VERSION ""

NS_ :

BS_:

BU_: BDCF THU FP IP RRS PLG BDCR FIS EPS ARHUD ETC EMS EPBI LAS WLCM ESCL HU APA ACC LCDAL LCDAR BMT AMP SRS TCU ATB AWD ESL ACM ECM PCU BMS IBCU OTA

BO_ 651 BCM_28B: 8 BDCF
 SG_ BCM_LowBeamStatus : 7|2@0+ (1,0) [0|3] "" THU,HU,IP
 SG_ BCM_HighBeamStatus : 5|2@0+ (1,0) [0|3] "" THU,HU,IP
 SG_ BCM_TurnLightSwitchSts : 3|2@0+ (1,0) [0|3] "" THU,HU,IP
 SG_ PEPS_EngineStallReq : 1|1@0+ (1,0) [0|1] "" EMS
 SG_ BCM_ReversePosition : 0|1@0+ (1,0) [0|1] "" THU,HU,IP,RRS
 SG_ BCM_HU_LampHeightLevFeedback : 11|4@0+ (1,0) [0|15] "" THU,HU
 SG_ BCM_DriverDoorStatus : 23|1@0+ (1,0) [0|1] "" THU,HU,IP,FIS,ESCL,BDCR
 SG_ BCM_TurnIndicatorLeft : 22|2@0+ (1,0) [0|3] "" THU,HU,IP,FIS
 SG_ BCM_TurnIndicatorRight : 20|2@0+ (1,0) [0|3] "" THU,HU,IP,FIS
 SG_ BCM_HoodStatus : 18|1@0+ (1,0) [0|1] "" THU,HU,IP
 SG_ PEPS_StartControlsignal : 17|2@0+ (1,0) [0|3] "" THU,IP
 SG_ LCM_LASSwitch : 25|2@0+ (1,0) [0|3] "" Vector__XXX
 SG_ PEPS_RemoteStartReq : 39|2@0+ (1,0) [0|3] "" THU,IP
 SG_ BCM_emergencylightstatus : 37|2@0+ (1,0) [0|3] "" THU,HU,IP
 SG_ BCM_PowerStatusFeedback : 35|2@0+ (1,0) [0|3] "" THU,HU,IP,FIS,PLG,BDCR
 SG_ BCM_RearDefrosterstatus : 33|2@0+ (1,0) [0|3] "" FP,THU
 SG_ BCM_RefuelReq : 55|1@0+ (1,0) [0|1] "" Vector__XXX
 SG_ PEPS_ShiftForbidReq : 54|1@0+ (1,0) [0|1] "" THU
 SG_ BCM_KeyAlarmStatus : 53|2@0+ (1,0) [0|3] "" THU,HU,IP,PLG
 SG_ BCM_RollingCounter_28B : 51|4@0+ (1,0) [0|15] "" Vector__XXX
 SG_ BCM_CRCCheck_28B : 63|8@0+ (1,0) [0|255] "" Vector__XXX

BO_ 610 BCM_262: 8 BDCF
 SG_ PEPS_StartIndicatorSignal : 7|1@0+ (1,0) [0|1] "" THU,IP
 SG_ PEPS_RemoteAPADoneKeyOffReq : 6|2@0+ (1,0) [0|3] "" Vector__XXX
 SG_ PEPS_APA_Engine0ffFeedback : 4|2@0+ (1,0) [0|3] "" Vector__XXX
 SG_ PEPS_APA_LockFeedback : 2|2@0+ (1,0) [0|3] "" Vector__XXX
 SG_ PEPS_APARemoteParkingSwitch : 0|1@0+ (1,0) [0|1] "" Vector__XXX
 SG_ PEPS_UnallowStart_ESCL_Error : 15|1@0+ (1,0) [0|1] "" THU,IP
 SG_ PEPS_APA_CloseWinFeedback : 11|2@0+ (1,0) [0|3] "" Vector__XXX
 SG_ PEPS_RemoteControlACReq : 9|2@0+ (1,0) [0|3] "" Vector__XXX
 SG_ PEPS_PowerDistributionStatus : 23|2@0+ (1,0) [0|3] "" THU,IP,ESCL
 SG_ PEPS_UnallowStart_ESCL_LOCK : 21|1@0+ (1,0) [0|1] "" THU,IP
 SG_ PEPS_EngineRuningWarning : 20|1@0+ (1,0) [0|1] "" Vector__XXX
 SG_ PEPS_UnallowStartSignal_Not_PN : 19|1@0+ (1,0) [0|1] "" THU,IP
 SG_ PEPS_IMMOFailedAlarmsignal : 18|1@0+ (1,0) [0|1] "" THU,IP
 SG_ PEPS_StartupButtonSignal : 17|2@0+ (1,0) [0|3] "" THU
 SG_ PEPS_RemoteStartFeedback : 31|5@0+ (1,0) [0|31] "" THU,IP
 SG_ PEPS_APA_PowerMirrorFoldFeedback : 26|2@0+ (1,0) [0|3] "" Vector__XXX
 SG_ PEPS_EngineStartupInhibitSts : 24|1@0+ (1,0) [0|1] "" Vector__XXX
 SG_ PEPS_PowerOff_NotPN_AlarmSignal : 38|1@0+ (1,0) [0|1] "" THU,IP
 SG_ PEPS_FRCameraStart : 37|2@0+ (1,0) [0|3] "" THU,IP,FIS
 SG_ PEPS_TBOX_RemoteIGNOnOffFeedback : 35|2@0+ (1,0) [0|3] "" THU,IP
 SG_ PEPS_PowerDistributionFaultBit : 47|1@0+ (1,0) [0|1] "" THU,IP
 SG_ PEPS_EngineStartupInhibitFB : 46|1@0+ (1,0) [0|1] "" THU
 SG_ PEPS_IMMOFeedback : 45|2@0+ (1,0) [0|3] "" Vector__XXX
 SG_ PEPS_PEPSFailStatus : 55|1@0+ (1,0) [0|1] "" THU,IP
 SG_ PEPS_KeyStandbyPositionIndicator : 54|1@0+ (1,0) [0|1] "" Vector__XXX
 SG_ PEPS_APARemoteParkingOff : 53|1@0+ (1,0) [0|1] "" Vector__XXX
 SG_ PEPS_RollingCounter_262 : 51|4@0+ (1,0) [0|15] "" Vector__XXX
 SG_ BCM_PEPS_BlueTooth : 60|2@0+ (1,0) [0|3] "" Vector__XXX
 SG_ PEPS_CRCCheck_262 : 63|8@0+ (1,0) [0|255] "" Vector__XXX

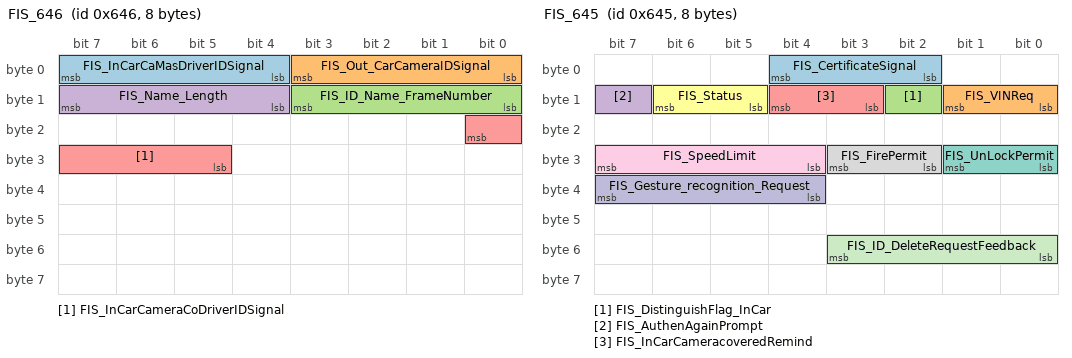
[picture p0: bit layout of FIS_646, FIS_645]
BO_ 1606 FIS_646: 8 FIS
 SG_ FIS_InCarCaMasDriverIDSignal : 7|4@0+ (1,0) [0|15] "" BDCF,THU
 SG_ FIS_Out_CarCameraIDSignal : 3|4@0+ (1,0) [0|15] "" BDCF,THU
 SG_ FIS_ID_Name_FrameNumber : 11|4@0+ (1,0) [0|15] "" BDCF,THU,IP
 SG_ FIS_Name_Length : 15|4@0+ (1,0) [0|15] "" BDCF,THU,IP
 SG_ FIS_InCarCameraCoDriverIDSignal : 16|4@0+ (1,0) [0|15] "" BDCF,THU

BO_ 1605 FIS_645: 8 FIS
 SG_ FIS_CertificateSignal : 4|3@0+ (1,0) [0|7] "" BDCF,THU,IP
 SG_ FIS_VINReq : 9|2@0+ (1,0) [0|3] "" BDCF,THU
 SG_ FIS_DistinguishFlag_InCar : 10|1@0+ (1,0) [0|1] "" BDCF,THU,IP
 SG_ FIS_AuthenAgainPrompt : 15|1@0+ (1,0) [0|1] "" BDCF,THU,IP
 SG_ FIS_InCarCameracoveredRemind : 12|2@0+ (1,0) [0|3] "" BDCF,THU,IP
 SG_ FIS_Status : 14|2@0+ (1,0) [0|3] "" BDCF,THU,IP
 SG_ FIS_UnLockPermit : 25|2@0+ (1,0) [0|3] "" BDCF,THU
 SG_ FIS_FirePermit : 27|2@0+ (1,0) [0|3] "" BDCF,THU
 SG_ FIS_SpeedLimit : 31|4@0+ (1,0) [0|15] "" BDCF,THU,IP
 SG_ FIS_Gesture_recognition_Request : 39|4@0+ (1,0) [0|7] "" BDCF,THU,IP
 SG_ FIS_ID_DeleteRequestFeedback : 51|4@0+ (1,0) [0|15] "" BDCF,THU

BO_ 935 FIS_3A7: 8 FIS
 SG_ FIS_PassengerDrowsinessStatus : 21|3@0+ (1,0) [0|3] "" BDCF,THU

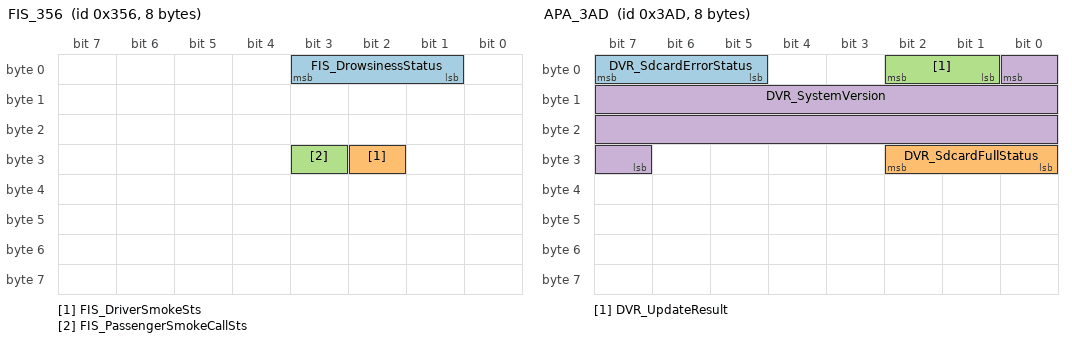
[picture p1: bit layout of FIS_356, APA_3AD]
BO_ 854 FIS_356: 8 FIS
 SG_ FIS_DrowsinessStatus : 3|3@0+ (1,0) [0|7] "" BDCF,THU
 SG_ FIS_DriverSmokeSts : 26|1@0+ (1,0) [0|1] "" BDCF,THU
 SG_ FIS_PassengerSmokeCallSts : 27|1@0+ (1,0) [0|1] "" BDCF,THU

BO_ 1554 APA_612: 8 APA
 SG_ DVR_DVREnableSetStatus : 7|2@0+ (1,0) [0|3] "" BDCF,THU
 SG_ DVR_DVRTapeSetStatus : 5|2@0+ (1,0) [0|3] "" THU
 SG_ DVR_RecordingCycleSetStatus : 1|2@0+ (1,0) [0|3] "" THU
 SG_ DVR_Error : 15|1@0+ (1,0) [0|1] "" THU
 SG_ DVR_DisplayVison : 12|3@0+ (1,0) [0|7] "" THU
 SG_ DVR_PhotographResult : 9|2@0+ (1,0) [0|3] "" THU
 SG_ DVR_DVRErrorRecordStatus : 31|2@0+ (1,0) [0|3] "" THU
 SG_ DVR_EmergencyRecordStatus : 29|2@0+ (1,0) [0|3] "" THU
 SG_ DVR_FormatStatus : 27|3@0+ (1,0) [0|7] "" THU
 SG_ AVM_DVREditFeedback : 24|1@0+ (1,0) [0|1] "" THU
 SG_ DVR_ReplayMode : 39|3@0+ (1,0) [0|7] "" THU
 SG_ AVM_DVRModeFeedback : 18|3@0+ (1,0) [0|7] ""  THU
 SG_ DVR_DistortCorrection : 34|1@0+ (1,1) [0|1] "" THU
 SG_ DVR_StoragePercent : 33|7@0+ (1,0) [0|100] "%" THU
 SG_ DVR_NormalToEmergency : 42|3@0+ (1,1) [0|7] "" THU
 SG_ DVR_StorageStatus : 55|2@0+ (1,0) [0|3] "" THU
 SG_ AVM_DVRReplayCommandStatus : 51|2@0+ (1,0) [0|3] "" THU
 SG_ AVM_DVRReplaySpeedStatus : 49|2@0+ (1,0) [0|3] "" THU
 SG_ DVR_PrintScreenFeedback : 53|2@0+ (1,0) [0|3] "" THU
 SG_ AVM_DVRDeleteStatus : 63|2@0+ (1,0) [0|3] "" THU
 SG_ AVM_CurrentVideo_counts : 61|4@0+ (1,0) [0|15] "" THU
 SG_ AVM_FormatFAT32Req : 57|1@0+ (1,0) [0|1] "" THU

BO_ 941 APA_3AD: 8 APA
 SG_ DVR_SdcardErrorStatus : 7|3@0+ (1,0) [0|7] "" BDCF,THU
 SG_ DVR_SdcardFullStatus : 26|3@0+ (1,0) [0|7] ""  THU
 SG_ DVR_UpdateResult : 2|2@0+ (1,0) [0|3] "" THU
 SG_ DVR_SystemVersion : 0|18@0+ (1,0) [0|0] "" THU

BO_ 992 APA_3E0: 8 APA
 SG_ AVM_DisplayForm : 4|5@0+ (1,0) [0|31] "" BDCF,THU
 SG_ AVM_DisplayReq : 7|2@0+ (1,0) [0|3] "" THU
 SG_ AVM_OverspeedWarning : 5|1@0+ (1,0) [0|1] "" THU
 SG_ AVM_LineOnOff : 15|2@0+ (1,0) [0|1] "" THU
 SG_ AVM_VisionAngle : 13|2@0+ (1,0) [0|3] "" THU
 SG_ AVM_RecordFeedback : 11|2@0+ (1,0) [0|3] "" THU
SG_ AVM_TopLookDownFeedBack : 52|2@0+ (1,0) [0|3] ""  THU
 SG_ AVM_3DFeedback : 23|2@0+ (1,0) [0|3] "" THU
 SG_ AVM_MODFeedback : 21|2@0+ (1,0) [0|3] "" THU
 SG_ AVM_MODAlert_Sound : 19|2@0+ (1,0) [0|3] "" THU,IP
 SG_ AVM_CalibrationStatus : 17|3@0+ (1,0) [0|7] "" THU
 SG_ AVM_CalibrationComfirm : 30|2@0+ (1,0) [0|3] "" THU
 SG_ AVM_RadarAVMFeedback : 28|2@0+ (1,0) [0|3] "" THU
 SG_ AVM_TurnlightFeedback : 26|2@0+ (1,0) [0|3] "" THU
 SG_ AVM_DVRVideoTimeLength : 24|9@0+ (1,0) [0|3] "second" THU
 SG_ AVM_DVRVideoPlayTime : 47|9@0+ (1,0) [0|3] "second" THU
 SG_ AVM_TransparentCarFeedback : 54|2@0+ (1,0) [0|3] "" THU
 SG_ AVM_RVDisplayReq : 56|1@0+ (1,0) [0|1] "" THU
 SG_ AVM_AVMOffSpeedStatus : 59|3@0+ (1,0) [0|7] "" THU
 SG_ DVR_UploadFeedback : 61|2@0+ (1,0) [0|3] "" THU
 SG_ AVM_StartOpenAvmSts : 63|2@0+ (1,0) [0|3] "" THU
 SG_ AVM_DirtyWarning : 48|1@0+ (1,0) [0|1] ""  THU

BO_ 1365 TBOX_555: 8 THU
SG_ TBOX_TUIDFrameNumber : 7|2@0+ (1,0) [0|3] "" BDCF
SG_ TBOX_TUIDNumber : 15|48@0+ (1,0) [0|16777215] "" BDCF
SG_ TBOX_CRCCheck_555 : 63|8@0+ (1,0) [0|255] "" BDCF

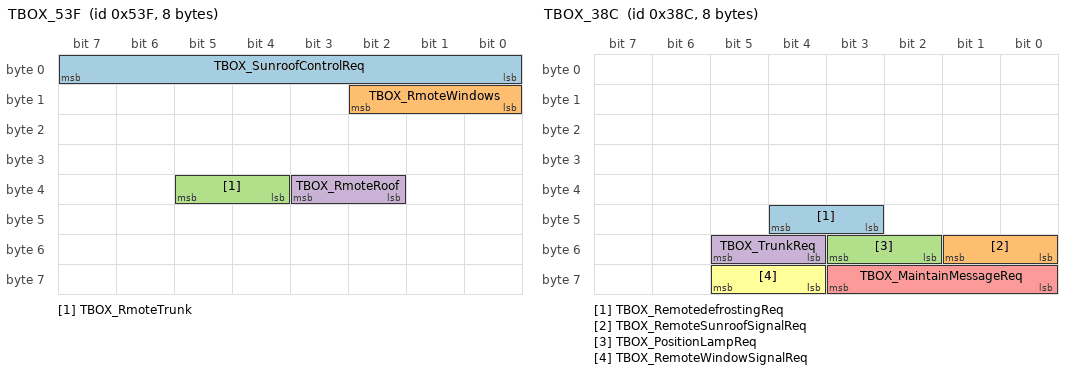
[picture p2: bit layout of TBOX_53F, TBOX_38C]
BO_ 1343 TBOX_53F: 8 THU
SG_ TBOX_SunroofControlReq : 7|8@0+ (1,0) [0|255] "" BDCF
SG_ TBOX_RmoteWindows : 10|3@0+ (1,0) [0|7] "" BDCF
SG_ TBOX_RmoteTrunk : 37|2@0+ (1,0) [0|3] "" BDCF,PLG
SG_ TBOX_RmoteRoof : 35|2@0+ (1,0) [0|3] "" BDCF

BO_ 719 TBOX_2CF: 8 THU
SG_ TBOX_BLEDataFlow : 7|64@0+ (1,0) [0|0] "" BDCF

BO_ 909 TBOX_38D: 8 THU
SG_ TBOX_VehicleVedioDetectReq : 1|2@0+ (1,0) [0|3] "" BDCF
SG_ TBOX_LockCommand : 3|2@0+ (1,0) [0|3] "" BDCF
SG_ TBOX_EngineStartupInhibit : 5|2@0+ (1,0) [0|3] "" BDCF
SG_ TBOX_RemoteEngineStartupReq : 7|2@0+ (1,0) [0|3] "" BDCF
SG_ TBOX_CallStatus : 10|3@0+ (1,0) [0|7] "" BDCF
SG_ TBOX_ChangePartStatus : 12|1@0+ (1,0) [0|1] "" BDCF
SG_ TBOX_AudioRequest : 14|2@0+ (1,0) [0|3] "" BDCF
SG_ TBOX_CarRemind : 15|1@0+ (1,0) [0|1] "" BDCF
SG_ TBOX_ACTempValueReq : 20|5@0+ (1,0) [0|31] "degreeC" BDCF
SG_ TBOX_BCallStatus : 23|3@0+ (1,0) [0|7] "" BDCF
SG_ TBOX_VINReq : 25|2@0+ (1,0) [0|3] "" BDCF
SG_ TBOX_VINMatchStatus : 27|2@0+ (1,0) [0|3] "" BDCF
SG_ TBOX_RemoteStartRunTime : 30|3@0+ (1,0) [0|7] "" BDCF
SG_ TBOX_VehicleStatusDemandReq : 31|1@0+ (1,0) [0|1] "" BDCF
SG_ TBOX_RemoteACStartupReq : 33|2@0+ (1,0) [0|3] "" BDCF
SG_ TBOX_ACFanAdjustValueReq : 37|4@0+ (1,0) [0|15] "" BDCF
SG_ TBOX_SearchCarReq : 39|2@0+ (1,0) [0|3] "" BDCF
SG_ TBOX_RemotePassangerSeatHotReq : 42|3@0+ (1,0) [0|7] "" BDCF
SG_ TBOX_RemoteDriverSeatHotReq : 45|3@0+ (1,0) [0|7] "" BDCF
SG_ TBOX_RemoteAirQualityInquire : 49|2@0+ (1,0) [0|3] "" BDCF
SG_ TBOX_CirculationModeReq : 51|2@0+ (1,0) [0|3] "" BDCF
SG_ TBOX_RemoteAirCleanReq : 53|2@0+ (1,0) [0|3] "" BDCF
SG_ TBOX_RemoteDetectReq : 55|2@0+ (1,0) [0|3] "" BDCF
SG_ TBOX_RemoteInstallReq : 57|2@0+ (1,0) [0|3] "" BDCF
SG_ TBOX_RemotePaVentilatieReq : 60|3@0+ (1,0) [0|7] "" BDCF
SG_ TBOX_RemoteDrVentilatieReq : 63|3@0+ (1,0) [0|7] "" BDCF

BO_ 908 TBOX_38C: 8 THU
 SG_ TBOX_RemotedefrostingReq : 44|2@0+ (1,0) [0|3] "" BDCF
 SG_ TBOX_RemoteSunroofSignalReq : 49|2@0+ (1,0) [0|3] "" BDCF
 SG_ TBOX_PositionLampReq : 51|2@0+ (1,0) [0|3] "" BDCF
 SG_ TBOX_TrunkReq : 53|2@0+ (1,0) [0|3] "" BDCF
 SG_ TBOX_MaintainMessageReq : 59|4@0+ (1,0) [0|15] "" BDCF
 SG_ TBOX_RemoteWindowSignalReq : 61|2@0+ (1,0) [0|3] "" BDCF

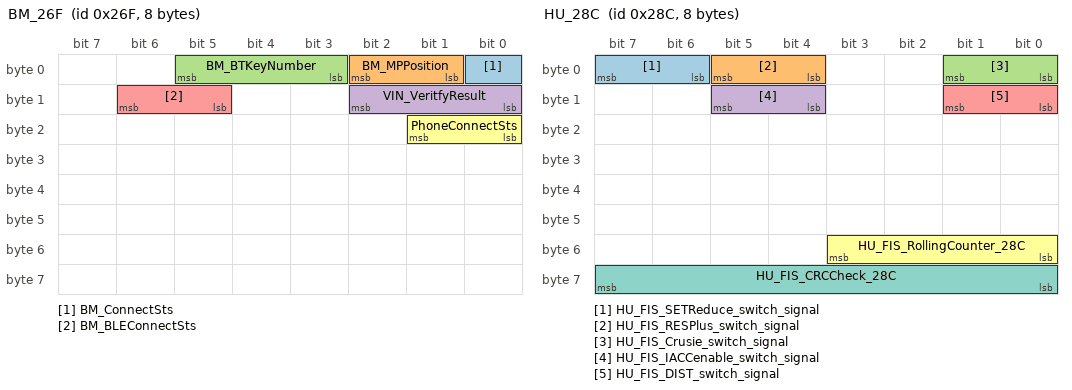
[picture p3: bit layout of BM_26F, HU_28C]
BO_ 623 BM_26F: 8 THU
SG_ BM_ConnectSts : 0|1@0+ (1,0) [0|1] "" BDCF
SG_ BM_MPPosition : 2|2@0+ (1,0) [0|3] "" BDCF
SG_ BM_BTKeyNumber : 5|3@0+ (1,0) [0|7] "" BDCF
SG_ VIN_VeritfyResult : 10|3@0+ (1,0) [0|7] "" BDCF
SG_ BM_BLEConnectSts : 14|2@0+ (1,0) [0|3] "" BDCF
 SG_ PhoneConnectSts : 17|2@0+ (1,0) [0|3] ""  BDCF

BO_ 622 BM_26E: 8 THU
SG_ BM_UnlockSignal : 0|1@0+ (1,0) [0|1] "" BDCF
SG_ BM_LockSignal : 1|1@0+ (1,0) [0|1] "" BDCF
SG_ BM_SunroofOpen : 2|1@0+ (1,0) [0|1] "" BDCF
SG_ BM_SunroofClose : 3|1@0+ (1,0) [0|1] "" BDCF
SG_ BM_LuggagelockSignal : 4|1@0+ (1,0) [0|1] "" BDCF
SG_ BM_LuggageUnlockSignal : 5|1@0+ (1,0) [0|1] "" BDCF
SG_ BM_SearchCarSignal : 9|2@0+ (1,0) [0|3] "" BDCF
SG_ BM_APAPOCModeSelect : 33|2@0+ (1,0) [0|3] "" BDCF
SG_ BM_All_WindowOpen : 34|1@0+ (1,0) [0|1] "" BDCF
SG_ BM_All_WindowClose : 35|1@0+ (1,0) [0|1] "" BDCF
SG_ BM_APAManeuverSuspend : 11|1@0+ (1,0) [0|1] "" BDCF
SG_ BM_APAManeuverCancel : 12|1@0+ (1,0) [0|1] "" BDCF
SG_ BM__StartControlsignal : 14|2@0+ (1,0) [0|3] "" BDCF
SG_ BM_APAManeuverStart : 15|1@0+ (1,0) [0|1] "" BDCF
SG_ BM_AllWindowCommand : 23|8@0+ (0.5,0) [0|100] "%" BDCF
SG_ BM_APAFunctionmoduleEnable : 25|2@0+ (1,0) [0|3] "" BDCF
SG_ BM_RPASwitch : 27|2@0+ (1,0) [0|3] "" BDCF
SG_ BM_OneTouchResponseSwitch : 29|2@0+ (1,0) [0|3] "" BDCF
SG_ BM_OneTouchDirectionSelect : 31|2@0+ (1,0) [0|3] "" BDCF

BO_ 652 HU_28C: 8 THU
 SG_ HU_FIS_SETReduce_switch_signal : 7|2@0+ (1,0) [0|3] "" BDCF,IP
 SG_ HU_FIS_RESPlus_switch_signal : 5|2@0+ (1,0) [0|3] "" BDCF,IP
 SG_ HU_FIS_Crusie_switch_signal : 1|2@0+ (1,0) [0|3] "" BDCF,IP
 SG_ HU_FIS_IACCenable_switch_signal : 13|2@0+ (1,0) [0|3] "" BDCF,IP
 SG_ HU_FIS_DIST_switch_signal : 9|2@0+ (1,0) [0|3] "" BDCF
 SG_ HU_FIS_RollingCounter_28C : 51|4@0+ (1,0) [0|15] ""  BDCF
 SG_ HU_FIS_CRCCheck_28C : 63|8@0+ (1,0) [0|255] ""  BDCF

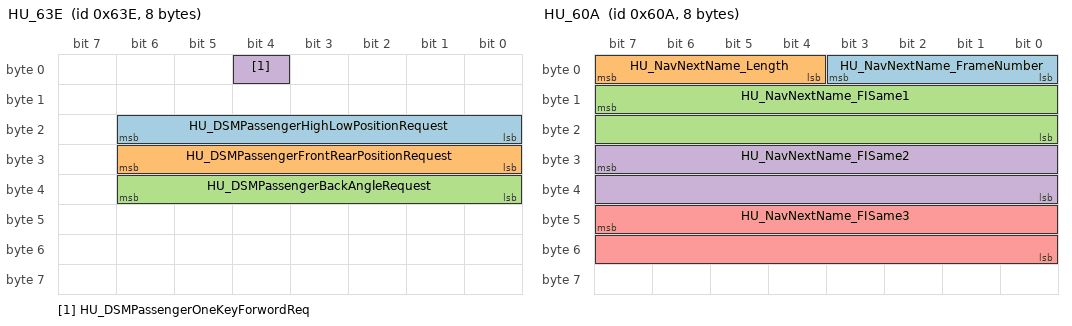
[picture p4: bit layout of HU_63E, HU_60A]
BO_ 1598 HU_63E: 8 THU
 SG_ HU_DSMPassengerHighLowPositionRequest : 22|7@0+ (1,0) [0|100] "%" BDCF
 SG_ HU_DSMPassengerFrontRearPositionRequest : 30|7@0+ (1,0) [0|100] "%" BDCF
 SG_ HU_DSMPassengerBackAngleRequest : 38|7@0+ (1,0) [0|126] "°" BDCF
 SG_ HU_DSMPassengerOneKeyForwordReq : 4|1@0+ (1,0) [0|1] "" BDCF

BO_ 1550 HU_60E: 8 THU
 SG_ HU_DSM_PositionSaved_Feedback : 1|2@0+ (1,0) [0|3] "" BDCF,FIS
 SG_ HU_MirrorTurnSet : 3|2@0+ (1,0) [0|3] "" BDCF
 SG_ HU_FRFuntionSet : 5|2@0+ (1,0) [0|3] "" BDCF,FIS
 SG_ HU_DSMComitySet : 7|2@0+ (1,0) [0|3] "" BDCF,FIS
 SG_ HU_DrDSMPositionSavedRequest : 9|2@0+ (1,0) [0|3] "" BDCF
 SG_ HU_PaDSMPositionSavedRequest : 11|2@0+ (1,0) [0|3] "" BDCF
 SG_ HU_DrDSMPositionRequest : 13|2@0+ (1,0) [0|3] "" BDCF,FIS
 SG_ HU_PaDSMPositionRequest : 15|2@0+ (1,0) [0|3] "" BDCF,FIS
 SG_ HU_DSMDriverHighLowPositionRequest : 22|7@0+ (1,0) [0|100] "%" BDCF
 SG_ HU_Current_position : 23|1@0+ (1,0) [0|1] "" BDCF
 SG_ HU_DSMDriverFrontRearPositionRequest : 30|7@0+ (1,0) [0|100] "%" BDCF
 SG_ HU_DSMDriverBackAngleRequest : 38|7@0+ (1,0) [0|126] "°" BDCF
 SG_ HU_DSMLeftMirrorXPositionRequest : 43|4@0+ (5,0) [0|75] "°" BDCF
 SG_ HU_DSMLeftMirrorYPositionRequest : 47|4@0+ (5,0) [0|75] "°" BDCF
 SG_ HU_DSMRightMirrorXPositionRequest : 51|4@0+ (5,0) [0|75] "°" BDCF
 SG_ HU_DSMRighttMirrorYPositionRequest : 55|4@0+ (5,0) [0|75] "°" BDCF
 SG_ HU_DSMComity_SwitchSet : 57|2@0+ (1,0) [0|3] "" BDCF
 SG_ HU_MirrorPositionSaved_Reques : 59|2@0+ (1,0) [0|3] "" BDCF

BO_ 1546 HU_60A: 8 THU
 SG_ HU_NavNextName_FrameNumber : 3|4@0+ (1,0) [0|15] "" BDCF
 SG_ HU_NavNextName_Length : 7|4@0+ (1,0) [0|15] "" BDCF
 SG_ HU_NavNextName_FISame1 : 15|16@0+ (1,0) [0|65535] "" BDCF
 SG_ HU_NavNextName_FISame2 : 31|16@0+ (1,0) [0|65535] "" BDCF
 SG_ HU_NavNextName_FISame3 : 47|16@0+ (1,0) [0|65535] "" BDCF

BO_ 1549 HU_60D: 8 THU
 SG_ HU_DSMUserIDDelete : 27|4@0+ (1,0) [0|15] ""  BDCF,FIS
 SG_ HU_GameStartRuest : 63|2@0+ (1,0) [0|3] ""  BDCF,FIS

BO_ 1552 HU_610: 8 THU
 SG_ CallingStatus : 7|4@0+ (1,0) [0|15] "" BDCF,IP

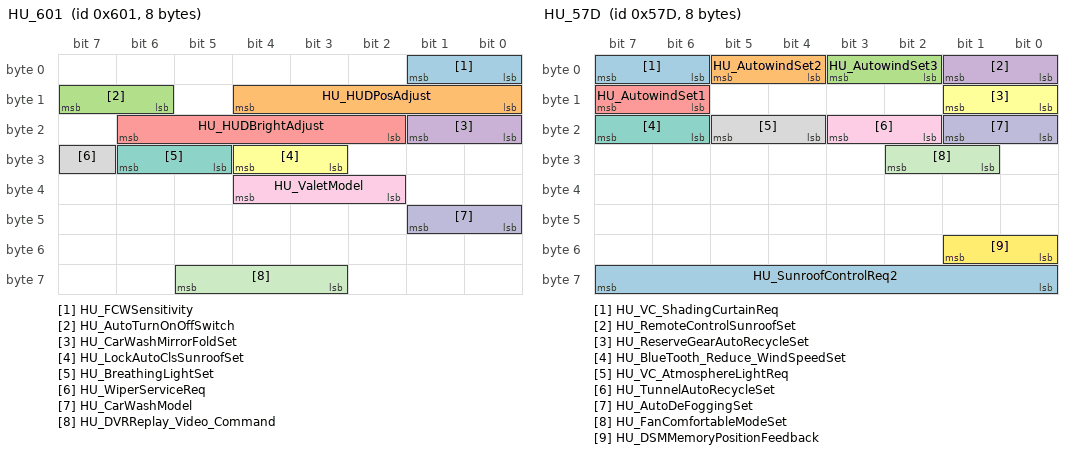
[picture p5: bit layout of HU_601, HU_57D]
BO_ 1537 HU_601: 8 THU
 SG_ HU_FCWSensitivity : 1|2@0+ (1,0) [0|3] "" BDCF
 SG_ HU_HUDPosAdjust : 12|5@0+ (1,0) [0|31] "" BDCF
 SG_ HU_AutoTurnOnOffSwitch : 15|2@0+ (1,0) [0|3] "" BDCF
 SG_ HU_CarWashMirrorFoldSet : 17|2@0+ (1,0) [0|3] "" BDCF
 SG_ HU_HUDBrightAdjust : 22|5@0+ (1,0) [0|31] "" BDCF
 SG_ HU_LockAutoClsSunroofSet : 28|2@0+ (1,0) [0|3] "" BDCF
 SG_ HU_BreathingLightSet : 30|2@0+ (1,0) [0|3] "" BDCF
 SG_ HU_WiperServiceReq : 31|1@0+ (1,0) [0|1] "" BDCF
 SG_ HU_ValetModel : 36|3@0+ (1,0) [0|7] "" BDCF
 SG_ HU_CarWashModel : 41|2@0+ (1,0) [0|1] "" BDCF
 SG_ HU_DVRReplay_Video_Command : 61|3@0+ (1,0) [0|7] "" BDCF

BO_ 1405 HU_57D: 8 THU
 SG_ HU_VC_ShadingCurtainReq : 7|2@0+ (1,0) [0|3] "" BDCF
 SG_ HU_AutowindSet2 : 5|2@0+ (1,0) [0|3] "" BDCF
 SG_ HU_AutowindSet3 : 3|2@0+ (1,0) [0|3] "" BDCF
 SG_ HU_RemoteControlSunroofSet : 1|2@0+ (1,0) [0|3] "" BDCF
 SG_ HU_AutowindSet1 : 15|2@0+ (1,0) [0|3] "" BDCF
 SG_ HU_ReserveGearAutoRecycleSet : 9|2@0+ (1,0) [0|3] "" BDCF
 SG_ HU_BlueTooth_Reduce_WindSpeedSet : 23|2@0+ (1,0) [0|3] "" BDCF
 SG_ HU_VC_AtmosphereLightReq : 21|2@0+ (1,0) [0|3] "" BDCF
 SG_ HU_TunnelAutoRecycleSet : 19|2@0+ (1,0) [0|3] "" BDCF
 SG_ HU_AutoDeFoggingSet : 17|2@0+ (1,0) [0|3] "" BDCF
 SG_ HU_FanComfortableModeSet : 26|2@0+ (1,0) [0|3] "" BDCF
 SG_ HU_DSMMemoryPositionFeedback : 49|2@0+ (1,0) [0|3] "" BDCF
 SG_ HU_SunroofControlReq2 : 63|8@0+ (1,0) [0|255] "" BDCF

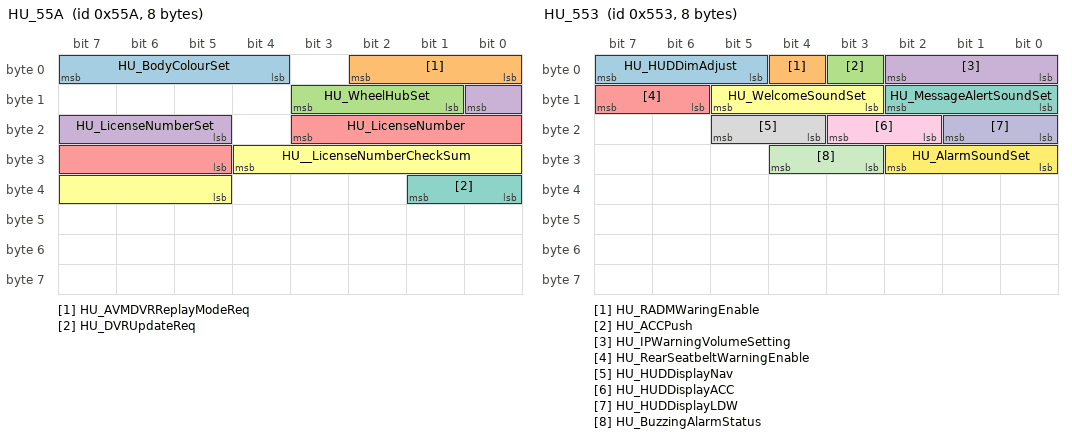
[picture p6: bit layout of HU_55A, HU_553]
BO_ 1370 HU_55A: 8 THU
 SG_ HU_BodyColourSet : 7|4@0+ (1,0) [0|15] "" BDCF
 SG_ HU_AVMDVRReplayModeReq : 2|3@0+ (1,0) [0|7] "" BDCF
 SG_ HU_WheelHubSet : 11|3@0+ (1,0) [0|7] "" BDCF
 SG_ HU_LicenseNumberSet : 8|4@0+ (1,0) [0|15] "" BDCF
 SG_ HU_LicenseNumber : 19|7@0+ (1,0) [0|127] "" BDCF
 SG_ HU__LicenseNumberCheckSum : 28|8@0+ (1,0) [0|255] "" BDCF
 SG_ HU_DVRUpdateReq : 33|2@0+ (1,0) [0|3] "" BDCF

BO_ 1363 HU_553: 8 THU
 SG_ HU_HUDDimAdjust : 7|3@0+ (1,0) [0|7] "" BDCF
 SG_ HU_RADMWaringEnable : 4|1@0+ (1,0) [0|1] "" BDCF
 SG_ HU_ACCPush : 3|1@0+ (1,0) [0|1] "" BDCF
 SG_ HU_IPWarningVolumeSetting : 2|3@0+ (1,0) [0|7] "" BDCF
 SG_ HU_RearSeatbeltWarningEnable : 15|2@0+ (1,0) [0|3] "" BDCF
 SG_ HU_WelcomeSoundSet : 13|3@0+ (1,0) [0|7] "" BDCF
 SG_ HU_MessageAlertSoundSet : 10|3@0+ (1,0) [0|7] "" BDCF
 SG_ HU_HUDDisplayNav : 21|2@0+ (1,0) [0|3] "" BDCF
 SG_ HU_HUDDisplayACC : 19|2@0+ (1,0) [0|3] "" BDCF
 SG_ HU_HUDDisplayLDW : 17|2@0+ (1,0) [0|3] "" BDCF
 SG_ HU_BuzzingAlarmStatus : 28|2@0+ (1,0) [0|3] "" BDCF
 SG_ HU_AlarmSoundSet : 26|3@0+ (1,0) [0|7] "" BDCF

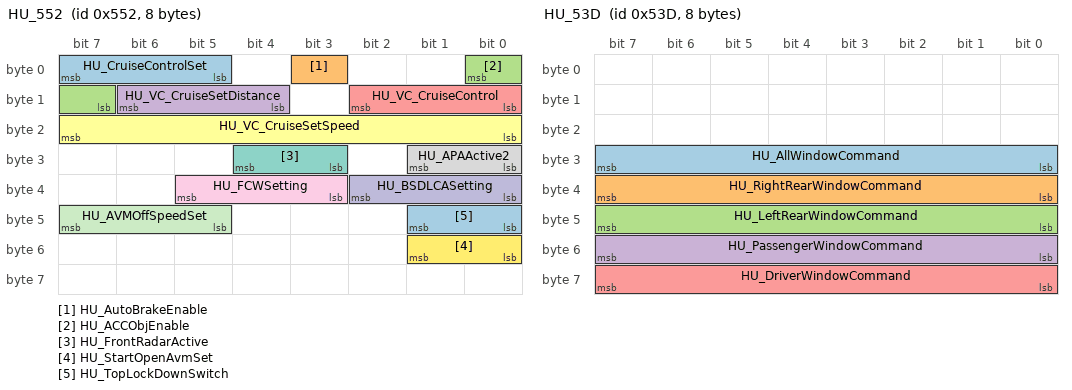
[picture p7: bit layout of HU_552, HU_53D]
BO_ 1362 HU_552: 8 THU
 SG_ HU_CruiseControlSet : 7|3@0+ (1,0) [0|7] "" BDCF
 SG_ HU_AutoBrakeEnable : 3|1@0+ (1,0) [0|1] "" BDCF
 SG_ HU_ACCObjEnable : 0|2@0+ (1,0) [0|3] "" BDCF
 SG_ HU_VC_CruiseSetDistance : 14|3@0+ (1,0) [0|7] "" BDCF
 SG_ HU_VC_CruiseControl : 10|3@0+ (1,0) [0|7] "" BDCF
 SG_ HU_VC_CruiseSetSpeed : 23|8@0+ (1,0) [0|255] "" BDCF
 SG_ HU_FrontRadarActive : 28|2@0+ (1,0) [0|3] "" BDCF
 SG_ HU_APAActive2 : 25|2@0+ (1,0) [0|3] "" BDCF
 SG_ HU_FCWSetting : 37|3@0+ (1,0) [0|7] "" BDCF
 SG_ HU_BSDLCASetting : 34|3@0+ (1,0) [0|7] "" BDCF
 SG_ HU_AVMOffSpeedSet : 47|3@0+ (1,0) [0|7] "" BDCF
 SG_ HU_StartOpenAvmSet : 49|2@0+ (1,0) [0|3] "" BDCF
 SG_ HU_TopLockDownSwitch : 41|2@0+ (1,0) [0|3] "" BDCF

BO_ 1341 HU_53D: 8 THU
 SG_ HU_AllWindowCommand : 31|8@0+ (0.5,0) [0|100] "%" BDCF
 SG_ HU_RightRearWindowCommand : 39|8@0+ (0.5,0) [0|100] "%" BDCF
 SG_ HU_LeftRearWindowCommand : 47|8@0+ (0.5,0) [0|100] "%" BDCF
 SG_ HU_PassengerWindowCommand : 55|8@0+ (0.5,0) [0|100] "%" BDCF
 SG_ HU_DriverWindowCommand : 63|8@0+ (0.5,0) [0|100] "%" BDCF

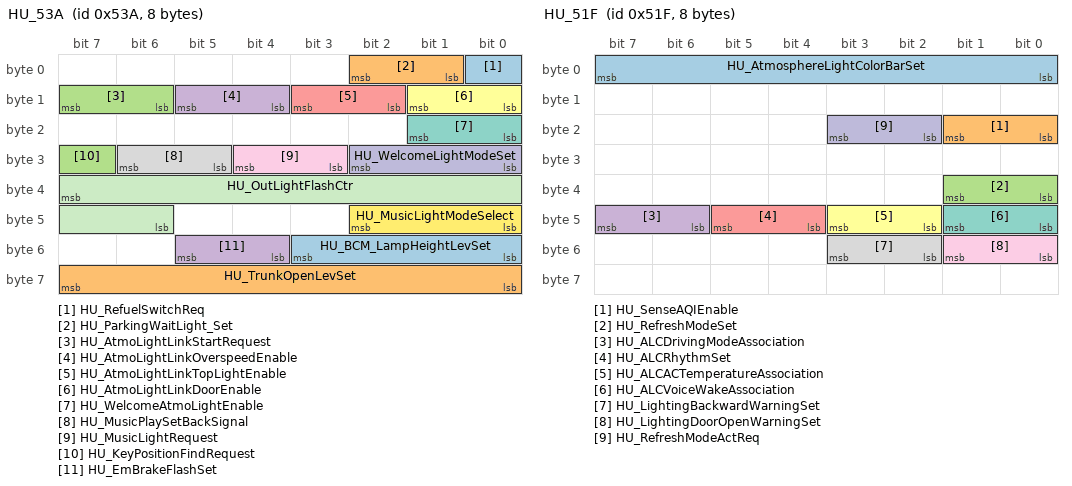
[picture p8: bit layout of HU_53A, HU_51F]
BO_ 1338 HU_53A: 8 THU
 SG_ HU_RefuelSwitchReq : 0|1@0+ (1,0) [0|1] "" BDCF
 SG_ HU_ParkingWaitLight_Set : 2|2@0+ (1,0) [0|3] "" BDCF
 SG_ HU_AtmoLightLinkStartRequest : 15|2@0+ (1,0) [0|3] "" BDCF
 SG_ HU_AtmoLightLinkOverspeedEnable : 13|2@0+ (1,0) [0|3] "" BDCF
 SG_ HU_AtmoLightLinkTopLightEnable : 11|2@0+ (1,0) [0|3] "" BDCF
 SG_ HU_AtmoLightLinkDoorEnable : 9|2@0+ (1,0) [0|3] "" BDCF
 SG_ HU_WelcomeAtmoLightEnable : 17|2@0+ (1,0) [0|3] "" BDCF
 SG_ HU_MusicPlaySetBackSignal : 30|2@0+ (1,0) [0|3] "" BDCF
 SG_ HU_MusicLightRequest : 28|2@0+ (1,0) [0|3] "" BDCF
 SG_ HU_WelcomeLightModeSet : 26|3@0+ (1,0) [0|7] "" BDCF
 SG_ HU_OutLightFlashCtr : 39|10@0+ (1,0) [0|1023] "" BDCF
 SG_ HU_MusicLightModeSelect : 42|3@0+ (1,0) [0|7] "" BDCF
 SG_ HU_BCM_LampHeightLevSet : 51|4@0+ (1,0) [0|15] "" BDCF
 SG_ HU_TrunkOpenLevSet : 63|8@0+ (0.395,0) [0|100] "" BDCF,PLG,BDCR
 SG_ HU_KeyPositionFindRequest : 31|1@0+ (1,0) [0|1] "" BDCF
 SG_ HU_EmBrakeFlashSet : 53|2@0+ (1,0) [0|3] "" BDCF

BO_ 1335 HU_537: 8 THU
 SG_ HU_RKEUnlockDoorTypeSet : 7|2@0+ (1,0) [0|3] "" BDCF
 SG_ HU_AutoIGNOFFUnlockSet : 5|2@0+ (1,0) [0|3] "" BDCF
 SG_ HU_RemoteControlWindowSet : 3|2@0+ (1,0) [0|3] "" BDCF
 SG_ HU_DrEasyEntrySet : 15|2@0+ (1,0) [0|3] ""  BDCF
 SG_ HU_PaEasyEntrySet : 17|2@0+ (1,0) [0|3] ""  BDCF
 SG_ HU_LaneChangeTurnLightSet : 13|3@0+ (1,0) [0|7] "" BDCF
 SG_ HU_FollowMeHomeLightSet : 10|3@0+ (1,0) [0|7] "" BDCF
 SG_ HU_AtmoLightAAEnable : 21|2@0+ (1,0) [0|3] "" BDCF
 SG_ HU_AutoFlashlightovertakeSet : 23|2@0+ (1,0) [0|3] ""  BDCF
 SG_ HU_TwiceLockDoorSet : 19|2@0+ (1,0) [0|3] ""  BDCF
 SG_ HU_AutoLeaveLockSet : 29|3@0+ (1,0) [0|7] ""  BDCF
 SG_ HU_HonkovertakeSet : 31|2@0+ (1,0) [0|3] ""  BDCF
 SG_ HU_RearWiperSet : 39|2@0+ (1,0) [0|3] ""  BDCF
 SG_ HU_LockAutoClsWinSet : 37|2@0+ (1,0) [0|3] ""  BDCF
 SG_ HU_MirrorSetStatus : 35|2@0+ (1,0) [0|3] ""  BDCF
 SG_ HU_AutoSpeedLockSet : 33|2@0+ (1,0) [0|3] ""  BDCF
 SG_ HU_MirrorAutoFoldSet : 47|2@0+ (1,0) [0|3] ""  BDCF
 SG_ HU_SmartUnlockSet : 43|2@0+ (1,0) [0|3] ""  BDCF
 SG_ HU_SmartLockSet : 41|2@0+ (1,0) [0|3] ""  BDCF
 SG_ HU_DriverSeatAdjust : 55|2@0+ (1,0) [0|3] ""  BDCF
 SG_ HU_RemoteControlWindowUpSet : 53|2@0+ (1,0) [0|3] ""  BDCF
 SG_ HU_RainCtrlSunRoofSet : 51|2@0+ (1,0) [0|3] ""  BDCF
 SG_ HU_Autoturnlightovertakemodeset : 49|2@0+ (1,0) [0|3] ""  BDCF
 SG_ HU_WelcomeLightMode : 60|3@0+ (1,0) [0|7] ""  BDCF
 SG_ HU_RainOpenLightSet : 57|2@0+ (1,0) [0|3] ""  BDCF

BO_ 1327 HU_52F: 8 THU
 SG_ HU_ACComfortAdjustment : 5|2@0+ (1,0) [0|3] "" BDCF
 SG_ HU_ACScenarioReq : 2|3@0+ (1,0) [0|7] "" BDCF

BO_ 1325 HU_52D: 8 THU
 SG_ HU_MaxACReq : 1|2@0+ (1,0) [0|3] "" BDCF
 SG_ HU_AQSReq : 3|2@0+ (1,0) [0|3] "" BDCF
 SG_ HU_ACFrontModeAdjustReq : 7|4@0+ (1,0) [0|15] "" BDCF
 SG_ HU_VentilationSetMorning : 11|4@0+ (1,0) [0|15] "" BDCF
 SG_ HU_VentilationSetAfternoon : 19|4@0+ (1,0) [0|15] "" BDCF
 SG_ HU_ACFanAdjustValueReq : 23|4@0+ (1,0) [0|15] "" BDCF
 SG_ HU_VentilationOn : 25|2@0+ (1,0) [0|3] "" BDCF
 SG_ HU_VentilationSetEvening : 29|4@0+ (1,0) [0|15] "" BDCF
 SG_ HU_SyncReq : 33|2@0+ (1,0) [0|3] "" BDCF
 SG_ HU_ACreq : 35|2@0+ (1,0) [0|3] "" BDCF
 SG_ HU_MaxDefrost_Switch : 36|1@0+ (1,0) [0|1] "" BDCF
 SG_ HU_CirculationModeReq : 45|3@0+ (1,0) [0|7] "" BDCF
 SG_ HU_IonizerReq : 47|2@0+ (1,0) [0|3] "" BDCF
 SG_ HU_ACRDEFAdjustReq : 49|2@0+ (1,0) [0|3] "" BDCF
 SG_ HU_ACDEFAdjustReq : 53|2@0+ (1,0) [0|3] "" BDCF
 SG_ HU_FrontACOffReq : 55|2@0+ (1,0) [0|3] "" BDCF
 SG_ HU_FrontAUTOACOnReq : 59|2@0+ (1,0) [0|3] "" BDCF
 SG_ HU_ACControlMode : 63|2@0+ (1,0) [0|3] "" BDCF

BO_ 1319 HU_527: 8 THU
 SG_ HU_TopLookDownSwitch : 1|2@0+ (1,0) [0|3] "" BDCF
 SG_ HU_DVRFormatReq : 3|2@0+ (1,0) [0|3] "" BDCF
 SG_ HU_RecordingcycleSetting : 5|2@0+ (1,0) [0|3] "" BDCF
 SG_ HU_DVRReplayCommand : 7|2@0+ (1,0) [0|3] "" BDCF
 SG_ HU_AVMCalibrationConfirm : 9|2@0+ (1,0) [0|3] "" BDCF
 SG_ HU_DVRDisplayVision : 12|3@0+ (1,0) [0|7] "" BDCF
 SG_ HU_DVRVedioSeek : 15|3@0+ (1,0) [0|7] "" BDCF
 SG_ HU_DVRTapeSet : 17|2@0+ (1,0) [0|3] "" BDCF
 SG_ HU_DVREnableSet : 19|2@0+ (1,0) [0|3] "" BDCF
 SG_ HU_DVRReplaySpeed : 21|2@0+ (1,0) [0|3] "" BDCF
 SG_ HU_DVRPrintScreen : 23|2@0+ (1,0) [0|3] "" BDCF
 SG_ HU_RadarAVMSwitch : 25|2@0+ (1,0) [0|3] "" BDCF
 SG_ HU_TurnLightAVMSwitch : 27|2@0+ (1,0) [0|3] "" BDCF
 SG_ HU_LanguageSet : 31|4@0+ (1,0) [0|15] "" BDCF
 SG_ HU_DVRDistortCorrectSwitch : 35|2@0+ (1,0) [0|3] "" BDCF
 SG_ HU_ResolutionSet : 37|2@0+ (1,0) [0|3] "" BDCF
 SG_ HU_DVRReplayMode : 39|2@0+ (1,0) [0|3] "" BDCF
 SG_ HU_DVRVideoPlayUserTime : 32|9@0+ (1,0) [0|511] "second" BDCF
 SG_ HU_VibrationWarningStatus : 49|2@0+ (1,0) [0|3] "" BDCF
 SG_ HU_DVREmergencyRecord : 51|2@0+ (1,0) [0|3] "" BDCF
 SG_ HU_MODEnable : 53|2@0+ (1,0) [0|3] "" BDCF
 SG_ HU_AVMCalibrationSwitch : 55|2@0+ (1,0) [0|3] "" BDCF
 SG_ HU_TransparentCarSwitch : 57|2@0+ (1,0) [0|3] "" BDCF
 SG_ HU_ShootControl : 59|2@0+ (1,0) [0|3] "" BDCF
 SG_ HU_DVRBrowseCommand : 63|4@0+ (1,0) [0|15] "" BDCF

BO_ 1311 HU_51F: 8 THU
 SG_ HU_AtmosphereLightColorBarSet : 7|8@0+ (1,0) [0|255] "" BDCF
 SG_ HU_SenseAQIEnable : 17|2@0+ (1,0) [0|3] "" BDCF
 SG_ HU_RefreshModeSet : 33|2@0+ (1,0) [0|3] "" BDCF
 SG_ HU_ALCDrivingModeAssociation : 47|2@0+ (1,0) [0|3] "" BDCF
 SG_ HU_ALCRhythmSet : 45|2@0+ (1,0) [0|3] "" BDCF
 SG_ HU_ALCACTemperatureAssociation : 43|2@0+ (1,0) [0|3] "" BDCF
 SG_ HU_ALCVoiceWakeAssociation : 41|2@0+ (1,0) [0|3] "" BDCF
 SG_ HU_LightingBackwardWarningSet : 51|2@0+ (1,0) [0|3] "" BDCF
 SG_ HU_LightingDoorOpenWarningSet : 49|2@0+ (1,0) [0|3] "" BDCF
 SG_ HU_RefreshModeActReq : 19|2@0+ (1,0) [0|3] ""  BDCF

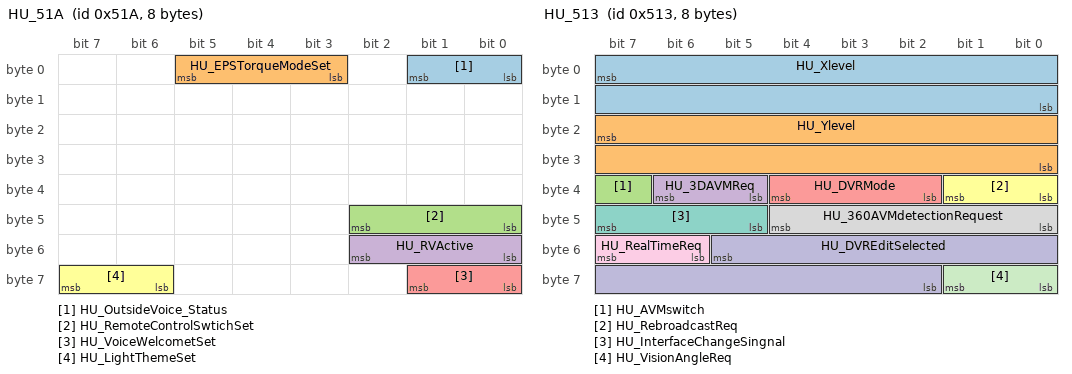
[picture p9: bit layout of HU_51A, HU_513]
BO_ 1306 HU_51A: 8 THU
 SG_ HU_OutsideVoice_Status : 1|2@0+ (1,0) [0|3] "" BDCF
 SG_ HU_EPSTorqueModeSet : 5|3@0+ (1,0) [0|7] "" BDCF,IP
 SG_ HU_RemoteControlSwtichSet : 42|3@0+ (1,0) [0|7] "" BDCF
 SG_ HU_RVActive : 50|3@0+ (1,0) [0|7] "" BDCF
 SG_ HU_VoiceWelcometSet : 57|2@0+ (1,0) [0|3] "" BDCF
 SG_ HU_LightThemeSet : 63|2@0+ (1,0) [0|3] "" BDCF

BO_ 1300 HU_514: 8 THU
 SG_ HU_ParkingModeSelect : 7|2@0+ (1,0) [0|3] "" BDCF
 SG_ HU_LASModeSelection : 5|3@0+ (1,0) [0|7] "" BDCF
 SG_ HU_FCTAEnable : 2|2@0+ (1,0) [0|3] "" BDCF
 SG_ HU_RCTAEnable : 0|2@0+ (1,0) [0|3] "" BDCF
 SG_ HU_RCWEnable : 14|2@0+ (1,0) [0|3] "" BDCF
 SG_ HU_HMAEnable : 12|1@0+ (1,0) [0|1] "" BDCF,LAS
 SG_ HU_TSRSwitch : 11|1@0+ (1,0) [0|1] "" BDCF
 SG_ HU_LASWarningModeSelection : 10|3@0+ (1,0) [0|7] "" BDCF
 SG_ HU_FatigueDectionEnable : 21|2@0+ (1,0) [0|3] "" BDCF
 SG_ HU_LDWShakeLev : 23|2@0+ (1,0) [0|3] "" BDCF
 SG_ HU_RCTBEnable : 19|2@0+ (1,0) [0|3] "" BDCF
 SG_ HU_SEAEnable : 17|2@0+ (1,0) [0|3] "" BDCF
 SG_ HU_OverspeedSoundWarEnable : 31|2@0+ (1,0) [0|3] "" BDCF
 SG_ HU_IACCEnable : 29|2@0+ (1,0) [0|3] "" BDCF
 SG_ HU_LockCtrlEnable : 27|2@0+ (1,0) [0|3] "" BDCF
 SG_ HU_AudioWarningEnable : 25|2@0+ (1,0) [0|3] "" BDCF
 SG_ HU_OverspeedWarningOffset : 38|5@0+ (1,-10) [-10|10] "" BDCF
 SG_ HU_OverspeedWarningEnable : 33|2@0+ (1,0) [0|3] "" BDCF
 SG_ HU_ParkingResume : 46|1@0+ (1,0) [0|1] "" BDCF
 SG_ HU_Uls_FKP_Activation : 45|2@0+ (1,0) [0|3] "" BDCF
 SG_ HU_FCTBEnable : 43|2@0+ (1,0) [0|3] "" BDCF
 SG_ HU_Uls_BSD_Activation : 41|2@0+ (1,0) [0|3] "" BDCF
 SG_ HU_ParkingConfirm : 54|1@0+ (1,0) [0|1] "" BDCF
 SG_ HU_RemoteDistanceSet : 53|4@0+ (1,0) [0|15] "m" BDCF
 SG_ HU_TJPEnable : 49|2@0+ (1,0) [0|3] "" BDCF
 SG_ HU_SlotVoiceSelect : 63|4@0+ (1,0) [0|15] "" BDCF
 SG_ HU_ObstacleSafeDistSet : 58|3@0+ (1,0) [0|7] "cm" BDCF

BO_ 1299 HU_513: 8 THU
 SG_ HU_Xlevel : 7|16@0+ (1,0) [0|1920] ""  BDCF
 SG_ HU_Ylevel : 23|16@0+ (1,0) [0|720] ""  BDCF
 SG_ HU_AVMswitch : 39|1@0+ (1,0) [0|1] ""  BDCF
 SG_ HU_3DAVMReq : 38|2@0+ (1,0) [0|3] ""  BDCF
 SG_ HU_DVRMode : 36|3@0+ (1,0) [0|7] ""  BDCF
 SG_ HU_RebroadcastReq : 33|2@0+ (1,0) [0|3] ""  BDCF
 SG_ HU_InterfaceChangeSingnal : 47|3@0+ (1,0) [0|7] ""  BDCF
 SG_ HU_360AVMdetectionRequest : 44|5@0+ (1,0) [0|31] ""  BDCF
 SG_ HU_RealTimeReq : 55|2@0+ (1,0) [0|3] ""  BDCF
 SG_ HU_DVREditSelected : 53|12@0+ (1,0) [0|4095] ""  BDCF
 SG_ HU_VisionAngleReq : 57|2@0+ (1,0) [0|3] ""  BDCF

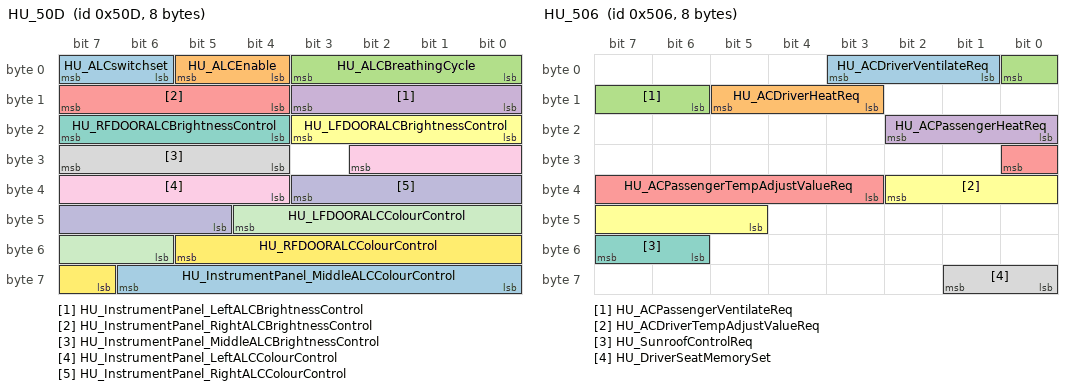
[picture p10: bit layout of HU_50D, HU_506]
BO_ 1293 HU_50D: 8 THU
 SG_ HU_ALCswitchset : 7|2@0+ (1,0) [0|3] "" BDCF
 SG_ HU_ALCEnable : 5|2@0+ (1,0) [0|3] "" BDCF
 SG_ HU_ALCBreathingCycle : 3|4@0+ (1,0) [0|15] "" BDCF
 SG_ HU_InstrumentPanel_LeftALCBrightnessControl : 11|4@0+ (1,0) [0|15] "" BDCF
 SG_ HU_InstrumentPanel_RightALCBrightnessControl : 15|4@0+ (1,0) [0|15] "" BDCF
 SG_ HU_LFDOORALCBrightnessControl : 19|4@0+ (1,0) [0|15] "" BDCF
 SG_ HU_RFDOORALCBrightnessControl : 23|4@0+ (1,0) [0|15] "" BDCF
 SG_ HU_InstrumentPanel_MiddleALCBrightnessControl : 31|4@0+ (1,0) [0|15] "" BDCF
 SG_ HU_InstrumentPanel_LeftALCColourControl : 26|7@0+ (1,0) [0|127] "" BDCF
 SG_ HU_InstrumentPanel_RightALCColourControl : 35|7@0+ (1,0) [0|127] "" BDCF
 SG_ HU_LFDOORALCColourControl : 44|7@0+ (1,0) [0|127] "" BDCF
 SG_ HU_RFDOORALCColourControl : 53|7@0+ (1,0) [0|127] "" BDCF
 SG_ HU_InstrumentPanel_MiddleALCColourControl : 62|7@0+ (1,0) [0|127] "" BDCF

BO_ 1286 HU_506: 8 THU
 SG_ HU_ACDriverVentilateReq : 3|3@0+ (1,0) [0|7] "" BDCF
 SG_ HU_ACDriverHeatReq : 13|3@0+ (1,0) [0|7] "" BDCF
 SG_ HU_ACPassengerVentilateReq : 0|3@0+ (1,0) [0|7] "" BDCF
 SG_ HU_ACPassengerHeatReq : 18|3@0+ (1,0) [0|7] "" BDCF
 SG_ HU_ACPassengerTempAdjustValueReq : 24|6@0+ (1,0) [18|32] "degree" BDCF
 SG_ HU_ACDriverTempAdjustValueReq : 34|6@0+ (1,0) [18|32] "degree" BDCF
 SG_ HU_SunroofControlReq : 55|2@0+ (1,0) [0|3] "" BDCF
 SG_ HU_DriverSeatMemorySet : 57|2@0+ (1,0) [0|3] "" BDCF,FIS

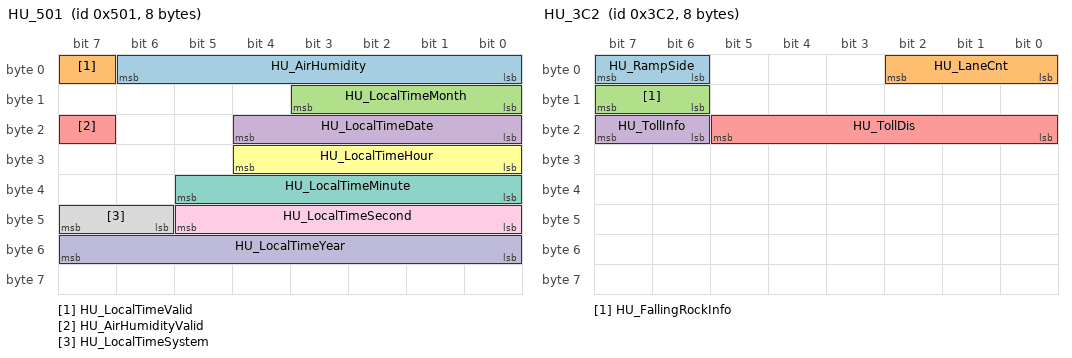
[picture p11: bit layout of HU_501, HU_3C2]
BO_ 1281 HU_501: 8 THU
 SG_ HU_AirHumidity : 6|7@0+ (1,0) [0|100] "%" BDCF
 SG_ HU_LocalTimeValid : 7|1@0+ (1,0) [0|1] "" BDCF,IP,FIS,ETC
 SG_ HU_LocalTimeMonth : 11|4@0+ (1,0) [1|12] "month" BDCF,IP,FIS,ETC
 SG_ HU_LocalTimeDate : 20|5@0+ (1,0) [1|31] "day" BDCF,IP,FIS,ETC
 SG_ HU_AirHumidityValid : 23|1@0+ (1,0) [0|1] "" BDCF
 SG_ HU_LocalTimeHour : 28|5@0+ (1,0) [0|23] "hour" BDCF,IP,FIS,ETC
 SG_ HU_LocalTimeMinute : 37|6@0+ (1,0) [0|59] "minute" BDCF,IP,FIS,ETC
 SG_ HU_LocalTimeSystem : 47|2@0+ (1,0) [0|3] "" BDCF,IP,FIS,ETC
 SG_ HU_LocalTimeSecond : 45|6@0+ (1,0) [0|59] "second" BDCF,IP,FIS,ETC
 SG_ HU_LocalTimeYear : 55|8@0+ (1,2013) [2013|2268] "year" BDCF,IP,FIS,ETC

BO_ 1280 HU_500: 8 THU
 SG_ HU_CurrentLocationValid : 7|1@0+ (1,0) [0|1] "" BDCF
 SG_ HU_CurrentLocationLongitude : 4|29@0+ (1E-06,-268.435455) [-180|180] "degree" BDCF
 SG_ HU_CurrentLocationLatitude : 35|28@0+ (1E-06,-134.217727) [-90|90] "degree" BDCF

BO_ 962 HU_3C2: 8 THU
 SG_ HU_RampSide : 7|2@0+ (1,0) [0|3] "" BDCF
 SG_ HU_LaneCnt : 2|3@0+ (1,0) [0|7] "" BDCF
 SG_ HU_FallingRockInfo : 15|2@0+ (1,0) [0|3] "" BDCF
 SG_ HU_TollInfo : 23|2@0+ (1,0) [0|3] "" BDCF
 SG_ HU_TollDis : 21|6@0+ (10,0) [0|600] "m" BDCF

BO_ 955 HU_3BB: 8 THU
 SG_ HU_SpeedLimitDistance : 5|6@0+ (10,0) [0|600] "m" BDCF

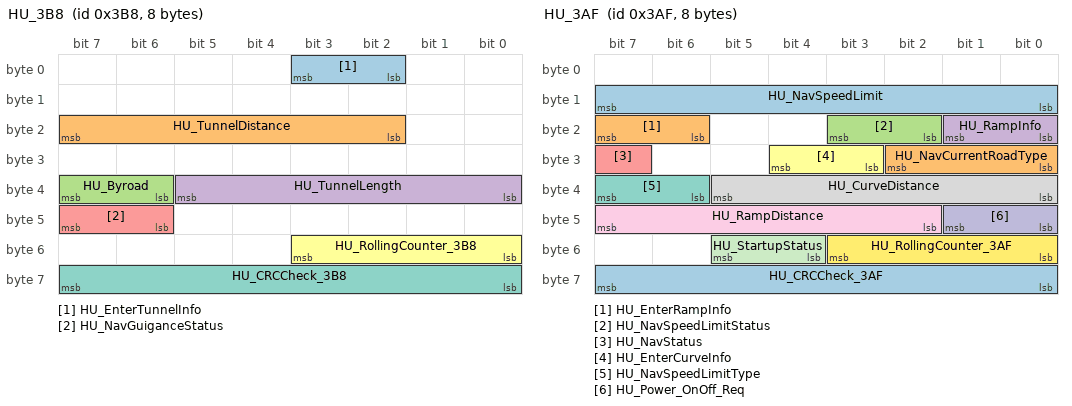
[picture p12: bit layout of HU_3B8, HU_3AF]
BO_ 952 HU_3B8: 8 THU
 SG_ HU_EnterTunnelInfo : 3|2@0+ (1,0) [0|3] "" BDCF,IP
 SG_ HU_TunnelDistance : 23|6@0+ (10,0) [0|600] "m" BDCF
 SG_ HU_Byroad : 39|2@0+ (1,0) [0|3] "" BDCF
 SG_ HU_TunnelLength : 37|6@0+ (1,0) [0|63] "m" BDCF
 SG_ HU_NavGuiganceStatus : 47|2@0+ (1,0) [0|3] "" BDCF
 SG_ HU_RollingCounter_3B8 : 51|4@0+ (1,0) [0|15] "" BDCF
 SG_ HU_CRCCheck_3B8 : 63|8@0+ (1,0) [0|255] "" BDCF

BO_ 943 HU_3AF: 8 THU
 SG_ HU_NavSpeedLimit : 15|8@0+ (1,0) [0|255] "" BDCF,IP
 SG_ HU_EnterRampInfo : 23|2@0+ (1,0) [0|3] "" BDCF
 SG_ HU_NavSpeedLimitStatus : 19|2@0+ (1,0) [0|3] "" BDCF,IP
 SG_ HU_RampInfo : 17|2@0+ (1,0) [0|3] "" BDCF
 SG_ HU_NavStatus : 31|1@0+ (1,0) [0|1] "" BDCF,IP
 SG_ HU_EnterCurveInfo : 28|2@0+ (1,0) [0|3] "" BDCF
 SG_ HU_NavSpeedLimitType : 39|2@0+ (1,0) [0|3] "" BDCF
 SG_ HU_CurveDistance : 37|6@0+ (10,0) [0|600] "m" BDCF
 SG_ HU_RampDistance : 47|6@0+ (10,0) [0|600] "m" BDCF
 SG_ HU_Power_OnOff_Req : 41|2@0+ (1,0) [0|3] "" BDCF
 SG_ HU_StartupStatus : 53|2@0+ (1,0) [0|3] "" BDCF
 SG_ HU_RollingCounter_3AF : 51|4@0+ (1,0) [0|15] "" BDCF
 SG_ HU_CRCCheck_3AF : 63|8@0+ (1,0) [0|255] "" BDCF
 SG_ HU_NavCurrentRoadType : 26|3@0+ (1,0) [0|7] ""  BDCF,IP

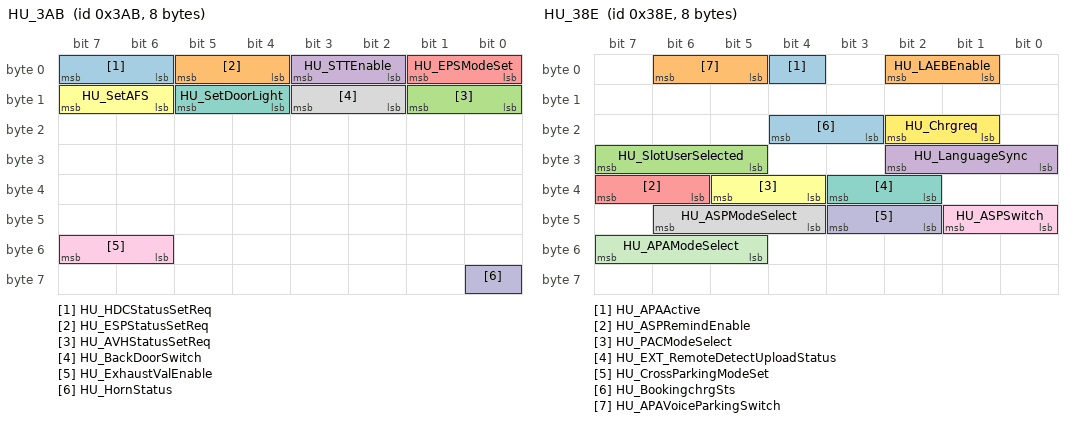
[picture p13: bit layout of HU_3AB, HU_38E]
BO_ 939 HU_3AB: 8 THU
 SG_ HU_HDCStatusSetReq : 7|2@0+ (1,0) [0|3] "" EPBI,BDCF
 SG_ HU_ESPStatusSetReq : 5|2@0+ (1,0) [0|3] "" EPBI,BDCF
 SG_ HU_AVHStatusSetReq : 9|2@0+ (1,0) [0|3] "" EPBI,BDCF
 SG_ HU_STTEnable : 3|2@0+ (1,0) [0|3] "" EMS,BDCF
 SG_ HU_EPSModeSet : 1|2@0+ (1,0) [0|3] "" EPS,BDCF
 SG_ HU_SetAFS : 15|2@0+ (1,0) [0|3] "" BDCF
 SG_ HU_SetDoorLight : 13|2@0+ (1,0) [0|3] "" BDCF
 SG_ HU_BackDoorSwitch : 11|2@0+ (1,0) [0|3] "" BDCF,PLG,BDCR
 SG_ HU_ExhaustValEnable : 55|2@0+ (1,0) [0|3] "" BDCF
 SG_ HU_HornStatus : 56|1@0+ (1,0) [0|1] "" BDCF

BO_ 910 HU_38E: 8 THU
 SG_ HU_APAActive : 4|1@0+ (1,0) [0|1] ""  BDCF
 SG_ HU_LAEBEnable : 2|2@0+ (1,0) [0|3] ""  BDCF
 SG_ HU_SlotUserSelected : 31|3@0+ (1,0) [0|7] ""  BDCF
 SG_ HU_LanguageSync : 26|3@0+ (1,0) [0|7] ""  BDCF,IP
 SG_ HU_ASPRemindEnable : 39|2@0+ (1,0) [0|3] ""  BDCF
 SG_ HU_PACModeSelect : 37|2@0+ (1,0) [0|3] ""  BDCF
 SG_ HU_EXT_RemoteDetectUploadStatus : 35|2@0+ (1,0) [0|3] ""  BDCF
 SG_ HU_ASPModeSelect : 46|3@0+ (1,0) [0|7] ""  BDCF
 SG_ HU_ASPSwitch : 41|2@0+ (1,0) [0|3] ""  BDCF
 SG_ HU_CrossParkingModeSet : 43|2@0+ (1,0) [0|3] ""  BDCF
 SG_ HU_APAModeSelect : 55|3@0+ (1,0) [0|7] ""  BDCF
 SG_ HU_Chrgreq : 18|2@0+ (1,0) [0|3] ""  BDCF
 SG_ HU_BookingchrgSts : 20|2@0+ (1,0) [0|3] ""  BDCF
 SG_ HU_APAVoiceParkingSwitch : 6|2@0+ (1,0) [0|3] ""  BDCF

BO_ 840 HU_348: 8 THU
 SG_ HU_NaviIconNumber_2 : 7|4@0+ (1,0) [0|15] "" BDCF,IP,ARHUD
 SG_ HU_AutoViewSet : 2|1@0+ (1,0) [0|1] "" BDCF
 SG_ HU_SDCapacity : 1|2@0+ (1,0) [0|3] "" BDCF
 SG_ HU_Seeoffanimation : 15|1@0+ (1,0) [0|1] "" BDCF,IP
 SG_ HU_TUIDReq : 11|2@0+ (1,0) [0|3] "" BDCF
 SG_ HU_RegisterStatus : 9|2@0+ (1,0) [0|3] "" BDCF
 SG_ HU_SurrondingMonitorDone : 23|1@0+ (1,0) [0|1] "" BDCF
 SG_ HU_BcallReq : 22|2@0+ (1,0) [0|3] "" BDCF
 SG_ HU_DVRErrorRecord : 20|2@0+ (1,0) [0|3] "" BDCF
 SG_ HU_DVRSystemImprint : 18|2@0+ (1,0) [0|3] "" BDCF
 SG_ HU_NaviDistance : 16|17@0+ (1,0) [0|131070] "m" BDCF,IP,ARHUD
 SG_ HU_NaviIconNumber : 47|8@0+ (1,0) [0|255] "" BDCF,IP,ARHUD
 SG_ HU_HUDMovingTargetDetect_Set : 53|1@0+ (1,0) [0|1] "" BDCF
 SG_ HU_HUDRearIncomingVehicleSet : 52|1@0+ (1,0) [0|1] "" BDCF
 SG_ CallingStatus : 51|4@0+ (1,0) [0|15] "" BDCF
 SG_ HU_HUDOnOffReq : 57|2@0+ (1,0) [0|3] "" BDCF,ARHUD
 SG_ HU_HUDBiasLightSet : 59|2@0+ (1,0) [0|3] "" BDCF
 SG_ HU_FollowTargetDisplay_Set : 60|1@0+ (1,0) [0|1] "" BDCF

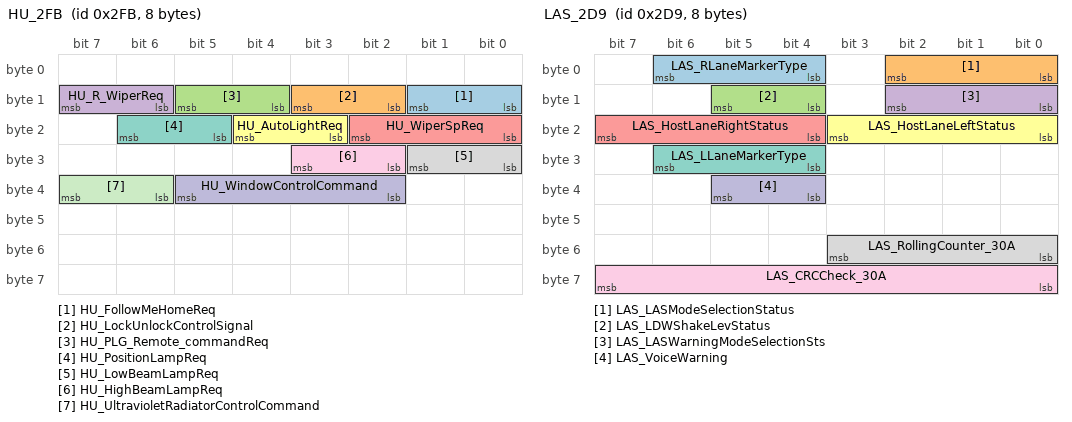
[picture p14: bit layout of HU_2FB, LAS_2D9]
BO_ 763 HU_2FB: 8 THU
 SG_ HU_FollowMeHomeReq : 9|2@0+ (1,0) [0|3] "" BDCF
 SG_ HU_LockUnlockControlSignal : 11|2@0+ (1,0) [0|3] "" BDCF
 SG_ HU_PLG_Remote_commandReq : 13|2@0+ (1,0) [0|3] "" BDCF,PLG
 SG_ HU_R_WiperReq : 15|2@0+ (1,0) [0|3] "" BDCF
 SG_ HU_WiperSpReq : 18|3@0+ (1,0) [0|3] "" BDCF
 SG_ HU_AutoLightReq : 20|2@0+ (1,0) [0|3] "" BDCF
 SG_ HU_PositionLampReq : 22|2@0+ (1,0) [0|3] "" BDCF
 SG_ HU_LowBeamLampReq : 25|2@0+ (1,0) [0|3] "" BDCF
 SG_ HU_HighBeamLampReq : 27|2@0+ (1,0) [0|3] "" BDCF
 SG_ HU_WindowControlCommand : 37|4@0+ (1,0) [0|15] "" BDCF
 SG_ HU_UltravioletRadiatorControlCommand : 39|2@0+ (1,0) [0|3] "" BDCF

BO_ 729 LAS_2D9: 8 LAS
 SG_ LAS_RLaneMarkerType : 6|3@0+ (1,0) [0|7] "" BDCF,THU,IP
 SG_ LAS_LASModeSelectionStatus : 2|3@0+ (1,0) [0|7] "" EPS,THU,IP
 SG_ LAS_LDWShakeLevStatus : 13|2@0+ (1,0) [0|3] "" EPS,THU,IP
 SG_ LAS_LASWarningModeSelectionSts : 10|3@0+ (1,0) [0|7] "" THU,IP
 SG_ LAS_HostLaneRightStatus : 23|4@0+ (1,0) [0|15] "" THU,IP
 SG_ LAS_HostLaneLeftStatus : 19|4@0+ (1,0) [15|15] "" THU,IP
 SG_ LAS_LLaneMarkerType : 30|3@0+ (1,0) [0|7] "" THU,IP
 SG_ LAS_RollingCounter_30A : 51|4@0+ (1,0) [0|15] "" THU,IP
 SG_ LAS_CRCCheck_30A : 63|8@0+ (1,0) [0|255] "" THU,IP
 SG_ LAS_VoiceWarning : 37|2@0+ (1,0) [0|3] "" THU,IP

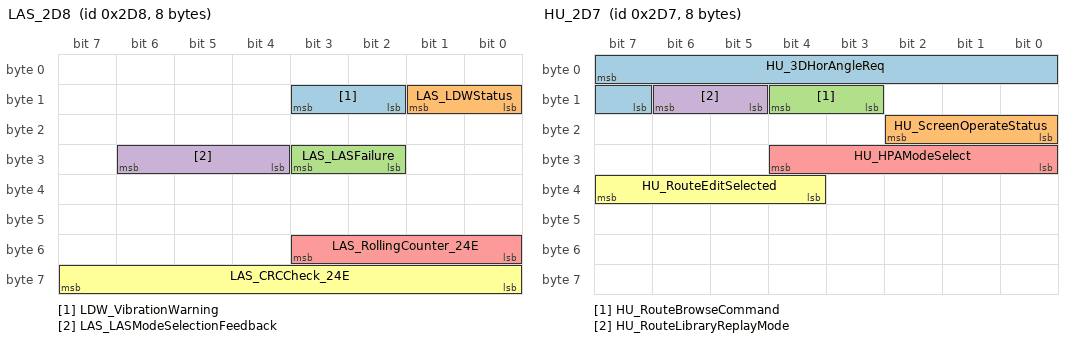
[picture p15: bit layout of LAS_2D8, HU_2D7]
BO_ 728 LAS_2D8: 8 LAS
 SG_ LDW_VibrationWarning : 11|2@0+ (1,0) [0|3] "" BDCF,EPS,THU,IP
 SG_ LAS_LDWStatus : 9|2@0+ (1,0) [0|3] "" EPS,THU,IP
 SG_ LAS_LASFailure : 27|2@0+ (1,0) [0|3] "" THU,IP,FIS
 SG_ LAS_LASModeSelectionFeedback : 30|3@0+ (1,0) [0|7] "" THU
 SG_ LAS_RollingCounter_24E : 51|4@0+ (1,0) [0|15] "" EPS,THU,IP
 SG_ LAS_CRCCheck_24E : 63|8@0+ (1,0) [0|255] "" EPS,THU,IP

BO_ 727 HU_2D7: 8 THU
 SG_ HU_3DHorAngleReq : 7|9@0+ (1,0) [0|360] "°"  BDCF
 SG_ HU_ScreenOperateStatus : 18|3@0+ (1,0) [0|7] ""  BDCF
 SG_ HU_RouteBrowseCommand : 12|2@0+ (1,0) [0|3] ""  BDCF
 SG_ HU_RouteLibraryReplayMode : 14|2@0+ (1,0) [0|3] ""  BDCF
 SG_ HU_HPAModeSelect : 28|5@0+ (1,0) [0|31] ""  BDCF
 SG_ HU_RouteEditSelected : 39|4@0+ (1,0) [0|15] ""  BDCF

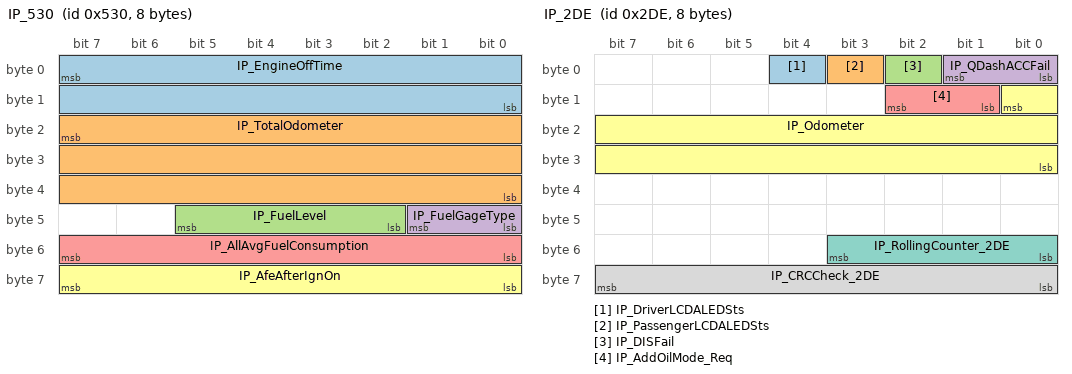
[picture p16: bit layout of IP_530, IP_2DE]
BO_ 1328 IP_530: 8 IP
 SG_ IP_EngineOffTime : 7|16@0+ (1,0) [0|65535] "s" BDCF
 SG_ IP_TotalOdometer : 23|24@0+ (0.1,0) [0|999999] "Km" BDCF,THU,FIS
 SG_ IP_FuelLevel : 45|4@0+ (1,0) [0|15] "" BDCF,THU
 SG_ IP_FuelGageType : 41|2@0+ (1,0) [0|3] "" BDCF
 SG_ IP_AllAvgFuelConsumption : 55|8@0+ (0.1,0) [0|25.4] "L/100Km" BDCF,THU
 SG_ IP_AfeAfterIgnOn : 63|8@0+ (0.1,0) [0|25.4] "L/100Km" BDCF,THU

BO_ 1290 IP_50A: 8 IP
 SG_ IP_FuelLeftoverVD : 23|1@0+ (1,0) [0|1] "" BDCF

BO_ 901 IP_385: 8 IP
 SG_ IP_EngineCoolanTemperatureHigh : 37|1@0+ (1,0) [0|1] "" BDCF,THU
 SG_ IP_EngineOilPressureLowSts : 38|1@0+ (1,0) [0|1] "" BDCF,THU
 SG_ IP_FuelLow : 39|1@0+ (1,0) [0|1] "" BDCF,THU

BO_ 734 IP_2DE: 8 IP
 SG_ IP_DriverLCDALEDSts : 4|1@0+ (1,0) [0|1] "" BDCF
 SG_ IP_PassengerLCDALEDSts : 3|1@0+ (1,0) [0|1] "" BDCF
 SG_ IP_DISFail : 2|1@0+ (1,0) [0|1] "" BDCF
 SG_ IP_QDashACCFail : 1|2@0+ (1,0) [0|3] "" BDCF
 SG_ IP_AddOilMode_Req : 10|2@0+ (1,0) [0|3] ""  BDCF,THU
 SG_ IP_Odometer : 8|17@0+ (0.1,0) [0|13107.1] "Km" BDCF
 SG_ IP_RollingCounter_2DE : 51|4@0+ (1,0) [0|15] "" BDCF
 SG_ IP_CRCCheck_2DE : 63|8@0+ (1,0) [0|255] "" BDCF

BO_ 1662 AC_67E: 8 BDCF
 SG_ AC_DTC1_HighByte : 7|8@0+ (1,0) [0|255] "" THU
 SG_ AC_DTC1_MiddByte : 15|8@0+ (1,0) [0|255] "" THU
 SG_ AC_DTC1_LowByte : 23|8@0+ (1,0) [0|255] "" THU
 SG_ AC_DTC1_Status : 31|8@0+ (1,0) [0|255] "" THU
 SG_ AC_DTC2_HighByte : 39|8@0+ (1,0) [0|255] "" THU
 SG_ AC_DTC2_MiddByte : 47|8@0+ (1,0) [0|255] "" THU
 SG_ AC_DTC2_LowByte : 55|8@0+ (1,0) [0|255] "" THU
 SG_ AC_DTC2_Status : 63|8@0+ (1,0) [0|255] "" THU

BO_ 1297 AC_511: 8 BDCF
 SG_ AC_Actual_pre_blow_mode : 45|6@0+ (0.1,0) [0|5] "v" Vector__XXX
 SG_ AC_EvaporatorSurfaceTemp_Reserve : 55|8@0+ (0.5,-40) [-40|87] "degree_C" Vector__XXX
 SG_ AC_LightSensorDiagnosis : 57|2@0+ (1,0) [0|3] "" Vector__XXX
 SG_ AC_CarInTempSensorDiagnosis : 59|2@0+ (1,0) [0|3] "" Vector__XXX
 SG_ AC_ThreeStateSwitchDiagnosis : 61|2@0+ (1,0) [0|3] "" Vector__XXX
 SG_ AC_EnvironmentalTempSensorDiagnosis : 63|2@0+ (1,0) [0|3] "" Vector__XXX

BO_ 1296 AC_510: 8 BDCF
 SG_ AC_InternalTemp : 7|8@0+ (0.5,-40) [-40|87] "degreeC" THU,IP
 SG_ AC_PM25InCar : 15|10@0+ (1,0) [0|1000] "ug/m^3" Vector__XXX
 SG_ AC_CO2Density : 20|13@0+ (1,0) [0|8191] "ppm" Vector__XXX
 SG_ AC_PM25InCarValid : 39|2@0+ (1,0) [0|3] "" Vector__XXX
 SG_ AC_AirQualityInCarLevel : 37|3@0+ (1,0) [0|7] "" Vector__XXX
 SG_ AC_PM25OutCar : 34|10@0+ (1,0) [0|1023] "ug/m^3" Vector__XXX

BO_ 923 AC_39B: 8 BDCF
 SG_ AC_ACSt : 7|1@0+ (1,0) [0|1] "" FP,THU
 SG_ AC_FrAutoSts : 6|2@0+ (1,0) [0|3] "" FP,THU
 SG_ AC_AutoWorkStatus : 4|2@0+ (1,0) [0|3] "" THU
 SG_ AC_RrBlowType : 15|2@0+ (1,0) [0|3] "" Vector__XXX
 SG_ AC_RearAutoSts : 13|2@0+ (1,0) [0|3] "" Vector__XXX
 SG_ AC_DriverReqTempModel : 23|5@0+ (1,1) [1|16] "档" THU
 SG_ AC_RemoteStartFeedback : 18|3@0+ (1,0) [0|7] "" THU
 SG_ AC_RearReqTemp : 30|5@0+ (0.5,17.5) [18|32] "℃" THU
 SG_ AC_DriverReqTemp : 25|5@0+ (0.5,17.5) [18|32] "℃" FP,THU
 SG_ AC_PaReqTemp : 36|5@0+ (0.5,17.5) [18|32] "℃" THU
 SG_ AC_TunnelAutoRecycleWork : 46|1@0+ (1,0) [0|1] "" THU
 SG_ AC_ClimateDisplayReq : 45|1@0+ (1,0) [0|1] "" THU
 SG_ AC_VentilationOnMode : 44|2@0+ (1,0) [0|3] "" THU
 SG_ AC_RecycleType : 42|3@0+ (1,0) [0|7] "" FP,THU
 SG_ AC_ACEcoSt : 55|1@0+ (1,0) [0|1] "" THU
 SG_ AC_AQSSt : 54|1@0+ (1,0) [0|1] "" THU
 SG_ AC_PlasmaSt : 53|1@0+ (1,0) [0|1] "" THU
 SG_ AC_RearSt : 50|2@0+ (1,0) [0|3] "" THU
 SG_ AC_RrpanelLock_St : 48|1@0+ (1,0) [0|1] "" Vector__XXX
 SG_ AC_EnvironmentalTemp_RAW : 63|8@0+ (0.5,-40) [-40|87] "℃" THU,IP

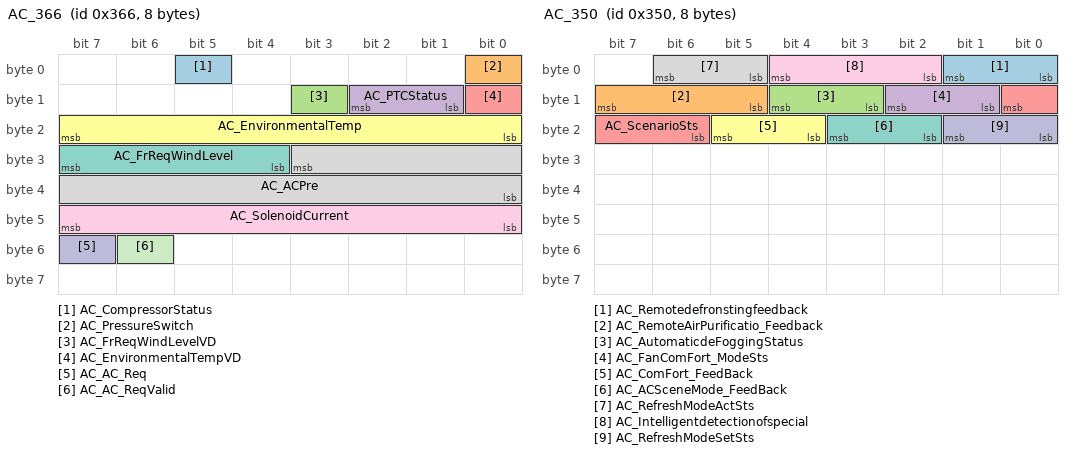
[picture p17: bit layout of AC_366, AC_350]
BO_ 870 AC_366: 8 BDCF
 SG_ AC_CompressorStatus : 5|1@0+ (1,0) [0|1] "" THU
 SG_ AC_PressureSwitch : 0|1@0+ (1,0) [0|1] "" Vector__XXX
 SG_ AC_FrReqWindLevelVD : 11|1@0+ (1,0) [0|1] "" THU
 SG_ AC_PTCStatus : 10|2@0+ (1,0) [0|3] "" Vector__XXX
 SG_ AC_EnvironmentalTempVD : 8|1@0+ (1,0) [0|1] "" THU,IP,PLG
 SG_ AC_EnvironmentalTemp : 23|8@0+ (0.5,-40) [-40|87] "degree_C" THU,IP,PLG
 SG_ AC_FrReqWindLevel : 31|4@0+ (1,0) [0|15] "" THU,BDCR
 SG_ AC_ACPre : 27|12@0+ (0.01,0) [0|40.94] "Mpa" THU
 SG_ AC_SolenoidCurrent : 47|8@0+ (0.004,0) [0|1.016] "A" Vector__XXX
 SG_ AC_AC_Req : 55|1@0+ (1,0) [0|1] "" FP,THU
 SG_ AC_AC_ReqValid : 54|1@0+ (1,0) [0|1] "" FP,THU

BO_ 848 AC_350: 8 BDCF
 SG_ AC_Remotedefronstingfeedback : 1|2@0+ (1,0) [0|3] ""  THU
 SG_ AC_RemoteAirPurificatio_Feedback : 15|3@0+ (1,0) [0|7] ""  THU
 SG_ AC_AutomaticdeFoggingStatus : 12|2@0+ (1,0) [0|3] ""  THU
 SG_ AC_FanComFort_ModeSts : 10|2@0+ (1,0) [0|3] ""  THU
 SG_ AC_ScenarioSts : 8|3@0+ (1,0) [0|7] ""  THU
 SG_ AC_ComFort_FeedBack : 21|2@0+ (1,0) [0|3] ""  THU
 SG_ AC_ACSceneMode_FeedBack : 19|2@0+ (1,0) [0|3] ""  THU
 SG_ AC_RefreshModeActSts : 6|2@0+ (1,0) [0|3] ""  THU
 SG_ AC_Intelligentdetectionofspecial : 4|3@0+ (1,0) [0|7] "" Vector__XXX
 SG_ AC_RefreshModeSetSts : 17|2@0+ (1,0) [0|3] ""  THU

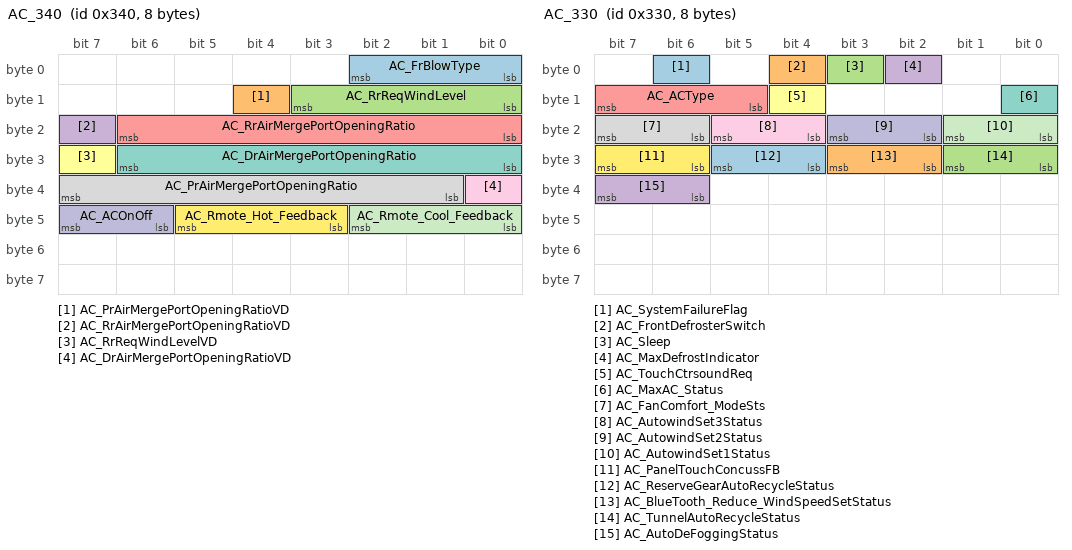
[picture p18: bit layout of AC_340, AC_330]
BO_ 832 AC_340: 8 BDCF
 SG_ AC_FrBlowType : 2|3@0+ (1,0) [0|7] "" THU
 SG_ AC_PrAirMergePortOpeningRatioVD : 12|1@0+ (1,0) [0|1] "" Vector__XXX
 SG_ AC_RrReqWindLevel : 11|4@0+ (1,0) [0|15] "档" Vector__XXX
 SG_ AC_RrAirMergePortOpeningRatioVD : 23|1@0+ (1,0) [0|1] "" Vector__XXX
 SG_ AC_RrAirMergePortOpeningRatio : 22|7@0+ (1,0) [0|100] "" Vector__XXX
 SG_ AC_RrReqWindLevelVD : 31|1@0+ (1,0) [0|1] "" THU
 SG_ AC_DrAirMergePortOpeningRatio : 30|7@0+ (1,0) [0|100] "" Vector__XXX
 SG_ AC_PrAirMergePortOpeningRatio : 39|7@0+ (1,0) [0|100] "" Vector__XXX
 SG_ AC_DrAirMergePortOpeningRatioVD : 32|1@0+ (1,0) [0|1] "" Vector__XXX
 SG_ AC_ACOnOff : 47|2@0+ (1,0) [0|3] "" THU
 SG_ AC_Rmote_Cool_Feedback : 42|3@0+ (1,0) [0|7] "" THU
 SG_ AC_Rmote_Hot_Feedback : 45|3@0+ (1,0) [0|7] "" THU

BO_ 816 AC_330: 8 BDCF
 SG_ AC_SystemFailureFlag : 6|1@0+ (1,0) [0|1] "" THU
 SG_ AC_FrontDefrosterSwitch : 4|1@0+ (1,0) [0|1] "" FP,THU
 SG_ AC_Sleep : 3|1@0+ (1,0) [0|1] "" THU
 SG_ AC_MaxDefrostIndicator : 2|1@0+ (1,0) [0|1] "" THU
 SG_ AC_ACType : 15|3@0+ (1,0) [0|7] "" THU
 SG_ AC_TouchCtrsoundReq : 12|1@0+ (1,0) [0|1] "" Vector__XXX
 SG_ AC_MaxAC_Status : 8|1@0+ (1,0) [0|1] "" THU
 SG_ AC_FanComfort_ModeSts : 23|2@0+ (1,0) [0|1] "" Vector__XXX
 SG_ AC_AutowindSet3Status : 21|2@0+ (1,0) [0|3] "" THU
 SG_ AC_AutowindSet2Status : 19|2@0+ (1,0) [0|3] "" THU
 SG_ AC_AutowindSet1Status : 17|2@0+ (1,0) [0|3] "" THU
 SG_ AC_PanelTouchConcussFB : 31|2@0+ (1,0) [0|3] "" Vector__XXX
 SG_ AC_ReserveGearAutoRecycleStatus : 29|2@0+ (1,0) [0|3] "" THU
 SG_ AC_BlueTooth_Reduce_WindSpeedSetStatus : 27|2@0+ (1,0) [0|3] "" THU
 SG_ AC_TunnelAutoRecycleStatus : 25|2@0+ (1,0) [0|3] "" THU
 SG_ AC_AutoDeFoggingStatus : 39|2@0+ (1,0) [0|3] "" THU

BO_ 769 CSU_301: 8 FP
 SG_ FP_RearDefrosterSwitch : 0|1@0+ (1,0) [0|1] "" BDCF,THU
 SG_ FP_Front_Defrost_Switch : 1|1@0+ (1,0) [0|1] "" BDCF
 SG_ FP_AC_Swtich : 2|1@0+ (1,0) [0|1] "" BDCF,THU
 SG_ FP_Front_AUTO_Switch : 3|1@0+ (1,0) [0|1] "" BDCF,THU
 SG_ FP_FanLongPress_Botton : 6|1@0+ (1,0) [0|1] "" BDCF
 SG_ FP_TempLongPress_Botton : 7|1@0+ (1,0) [0|1] "" BDCF
 SG_ FP_CyclingMode : 10|1@0+ (1,0) [0|1] "" BDCF,THU
 SG_ FP_AirFlowMode_CW : 11|1@0+ (1,0) [0|1] "" BDCF,THU
 SG_ FP_OFF : 12|1@0+ (1,0) [0|1] "" BDCF,THU
 SG_ FP_MaxAC_Switch : 14|1@0+ (1,0) [0|1] "" BDCF,THU
 SG_ FP_Fan_Inc_Swich : 19|4@0+ (1,0) [0|15] "" BDCF,THU
 SG_ FP_Fan_dec_Swich : 23|4@0+ (1,0) [0|15] "" BDCF,THU
 SG_ FP_Temp_Inc_Switch : 27|4@0+ (1,0) [0|15] "" BDCF
 SG_ FP_Temp_Dec_Switch : 31|4@0+ (1,0) [0|15] "" BDCF
 SG_ AC_HardwireDriveModeChange : 41|2@0+ (1,0) [0|3] "" BDCF
 SG_ FP_MaxDefrost_Switch : 42|1@0+ (1,0) [0|1] "" BDCF
 SG_ FP_ACDriverTempAdjustValueReq : 53|6@0+ (1,0) [18|32] "degree" BDCF,THU

BO_ 1352 BDCF_548: 8 BDCF
 SG_ IR_Brightness : 7|8@0+ (400,0) [400|101600] "Lux" THU,IP
 SG_ FW_Brightness : 9|10@0+ (6,0) [6|6132] "Lux" THU,IP
 SG_ AMB_Brightness : 25|10@0+ (20,0) [20|20440] "Lux" THU,IP
 SG_ PWM_Voltage : 41|10@0+ (1,0) [1|1022] "V" THU,IP

BO_ 924 HU_39C: 8 THU
 SG_ HU_PowerOutputReq : 7|3@0+ (1,0) [0|7] "" BDCF
 SG_ HU_IxModeMemoryEnable : 4|2@0+ (1,0) [0|3] "" BDCF
 SG_ HU_IxModePrior : 2|4@0+ (1,0) [0|15] "" BDCF

BO_ 866 BDCF_362: 8 BDCF
 SG_ PCU_DrvModVld : 18|1@0+ (1,0) [0|1] "" THU
 SG_ PCU_DrvMod : 21|3@0+ (1,0) [0|7] "" THU

BO_ 706 BDCF_2C2: 8 BDCF
 SG_ PCU_SavetargetSOCSts : 23|8@0+ (1,0) [0|100] "" THU

BO_ 459 BDCF_1CB: 8 BDCF
 SG_ IBCU_BrakeModeFeedBack : 1|2@0+ (1,0) [0|3] "" THU

BO_ 977 BDCF_3D1: 8 BDCF
 SG_ PCU_CoastLevel : 63|2@0+ (1,0) [0|3] "" THU

BO_ 913 BDCF_391: 8 BDCF
 SG_ PCU_ChrgImaxlimtFB : 31|3@0+ (1,0) [0|7] "" THU
 SG_ PCU_BookingChrgExeFeedback : 53|3@0+ (1,0) [0|7] "" THU
 SG_ PCU_ChrgModeSetFeedback : 50|2@0+ (1,0) [0|3] "" THU
 SG_ PCU_IxModeMemoryEnableSts : 4|2@0+ (1,0) [0|3] "" THU
 SG_ PCU_PowerOutputSts : 7|3@0+ (1,0) [0|7] "" THU
 SG_ PCU_IxModePriorSts : 41|4@0+ (1,0) [0|15] "" THU
 SG_ PCU_SysinfDis : 28|5@0+ (1,0) [0|31] "" THU
 SG_ PCU_ECnsAvgShortTerm : 34|9@0+ (0.1,0) [0|51] "" THU
 SG_ PCU_EcnsTotAftIgnOn : 2|11@0+ (0.1,0) [0|204.6] "" THU

BO_ 1016 HU_3F8: 8 THU
 SG_ HU_ChrgImaxlimt : 2|3@0+ (1,0) [0|7] "" BDCF
 SG_ HU_CoastLevelReq : 4|2@0+ (1,0) [0|3] "" BDCF
 SG_ HU_SavetargetSOC : 15|8@0+ (1,0) [0|100] "" BDCF

BO_ 852 BDCF_354: 8 BMS
 SG_ EMS_FuelTankLetOutSts : 54|3@0+ (1,0) [0|7] "" BDCF,THU

BO_ 773 BDCF_305: 8 BMS
 SG_ BMS_ChrgSts : 42|2@0+ (1,0) [0|3] "" BDCF,THU

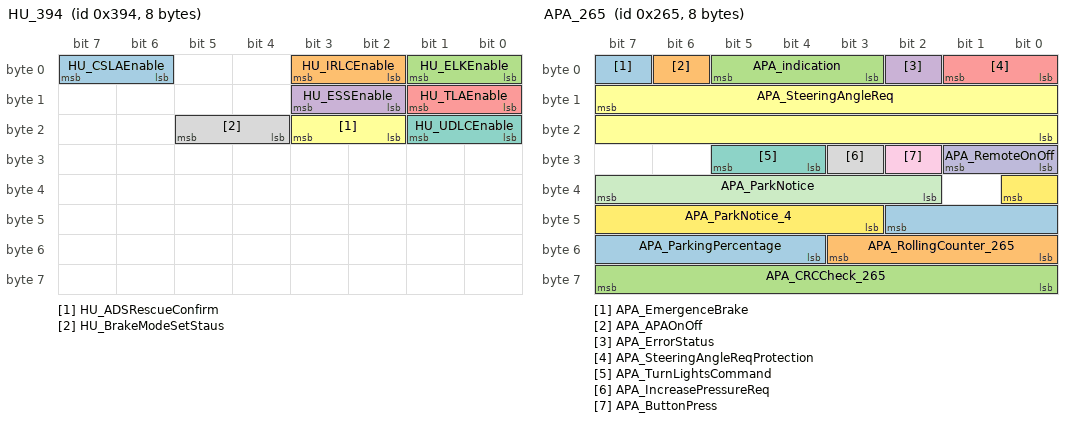
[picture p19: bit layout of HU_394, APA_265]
BO_ 916 HU_394: 8 THU
 SG_ HU_CSLAEnable : 7|2@0+ (1,0) [0|3] ""  BDCF
 SG_ HU_IRLCEnable : 3|2@0+ (1,0) [0|3] ""  BDCF
 SG_ HU_ELKEnable : 1|2@0+ (1,0) [0|3] ""  BDCF
 SG_ HU_ESSEnable : 11|2@0+ (1,0) [0|3] ""  BDCF
 SG_ HU_TLAEnable : 9|2@0+ (1,0) [0|3] ""  BDCF
 SG_ HU_ADSRescueConfirm : 19|2@0+ (1,0) [0|3] ""  BDCF
 SG_ HU_UDLCEnable : 17|2@0+ (1,0) [0|3] ""  BDCF
 SG_ HU_BrakeModeSetStaus : 21|2@0+ (1,0) [0|3] ""  BDCF

BO_ 604 BDCF_25C: 8 BDCF
 SG_ GW_Authernticator_25C : 55|16@0+ (1,0) [0|65535] ""  THU
 SG_ GW_ResetCounter_25C : 17|24@0+ (1,0) [0|16777215] ""  THU
 SG_ GW_TripCounter_25C : 7|22@0+ (1,0) [0|4194303] ""  THU

BO_ 613 APA_265: 8 BDCF
	SG_ APA_EmergenceBrake : 7|1@0+ (1,0) [0|1] "" APA
	SG_ APA_APAOnOff : 6|1@0+ (1,0) [0|1] "" THU
	SG_ APA_indication : 5|3@0+ (1,0) [0|7] "" Vector__XXX
	SG_ APA_ErrorStatus : 2|1@0+ (1,0) [0|1] "" Vector__XXX
	SG_ APA_SteeringAngleReqProtection : 1|2@0+ (1,0) [0|3] "" Vector__XXX
	SG_ APA_SteeringAngleReq : 15|16@0+ (0.1,0) [-780|780] "degree" Vector__XXX
	SG_ APA_TurnLightsCommand : 29|2@0+ (1,0) [0|3] "" Vector__XXX
	SG_ APA_IncreasePressureReq : 27|1@0+ (1,0) [0|1] "" Vector__XXX
	SG_ APA_ButtonPress : 26|1@0+ (1,0) [0|1] "" THU,IP
	SG_ APA_RemoteOnOff : 25|2@0+ (1,0) [0|3] "" THU,IP
	SG_ APA_ParkNotice : 39|6@0+ (1,0) [0|63] "" THU,IP
	SG_ APA_ParkNotice_4 : 32|6@0+ (1,0) [0|63] "" THU,IP
	SG_ APA_ParkingPercentage : 42|7@0+ (1,0) [0|100] "%" Vector__XXX
	SG_ APA_RollingCounter_265 : 51|4@0+ (1,0) [0|15] "" THU,IP
	SG_ APA_CRCCheck_265 : 63|8@0+ (1,0) [0|255] "" THU,IP

CM_ SG_ 1568 IP_Statuts "互联请求";
CM_ SG_ 1568 Error "错误标志";
CM_ SG_ 773 ETC_Packing_Duration_Minute "停车时长分钟";
CM_ SG_ 773 ETC_Packing_Duration_Hour "停车时长小时";
CM_ SG_ 773 ETC_Packing_Duration_Day "停车时长天";
CM_ SG_ 773 ETC_Consume_Amount_Branch "ETC_消费金额分";
CM_ SG_ 773 ETC_Consume_Amount_Horn "ETC_消费金额角";
CM_ SG_ 773 ETC_Consume_Amount_Element "ETC_消费金额元";
CM_ SG_ 773 ETC_Consume_Amount_Ten_Element "ETC_消费金额十元";
CM_ SG_ 773 ETC_Consume_Amount_Hundred_Element "ETC_消费金额百元";
CM_ SG_ 773 ETC_Consume_Amount_Thousand_Element "ETC_消费金额千元";
CM_ SG_ 773 ETC_Packing_Information "停车场信息";
CM_ SG_ 773 ETC_Highway_information "高速信息";
CM_ SG_ 773 ETC_FaultStatus "ETC故障状态";
CM_ SG_ 773 ETC_ActiveStatus "ETC激活状态";
CM_ SG_ 613 APA_CRCCheck_265 "APA_264校验和";
CM_ SG_ 613 APA_RollingCounter_265 "APA_264计数器";
CM_ SG_ 613 APA_ParkingPercentage "泊车进度条显示";
CM_ SG_ 613 APA_ParkNotice_4 "自动泊车过程提示信号";
CM_ SG_ 613 APA_ParkNotice "自动泊车过程提示信号";
CM_ SG_ 613 APA_RemoteOnOff "遥控钥匙方案_APA_发出信号给PEPS";
CM_ SG_ 613 APA_ButtonPress "APA开关状态";
CM_ SG_ 613 APA_IncreasePressureReq "APA请求主动建压请求";
CM_ SG_ 613 APA_TurnLightsCommand "转向灯控制命令";
CM_ SG_ 613 APA_SteeringAngleReq "APA转向角度请求";
CM_ SG_ 613 APA_ErrorStatus "自动泊车故障信号";
CM_ SG_ 613 APA_indication "APA功能指示";
CM_ SG_ 613 APA_APAOnOff "APA功能开启状态";
CM_ SG_ 613 APA_EmergenceBrake "紧急制动请求";

CM_ SG_ 782 AMP_LRBalanceSETStatus "声场左右平衡设置状态";
CM_ SG_ 782 AMP_FRBalanceSETStatus "声场前后平衡设置状态";
CM_ SG_ 782 AMP_CustomBassSETStatus "自定义低音设置状态";
CM_ SG_ 782 AMP_CustomMidrangeSETStatus "自定义中音设置状态";
CM_ SG_ 782 AMP_CustomTrebleSETStatus "自定义高音设置状态";
CM_ SG_ 782 AMP_CustomEffectSETStatus "自定义音效设置状态";
CM_ SG_ 782 AMP_SoundEffectSETStatus "音效设置状态";
CM_ SG_ 782 AMP_NAVIVolSETStatus "导航播报音量设置状态";
CM_ SG_ 782 AMP_TTSVRVolSETStatus "TTS/语音音量设置状态";
CM_ SG_ 782 AMP_TELBCALLVolSETStatus "蓝牙电话音量/becall音量设置状态";
CM_ SG_ 782 AMP_SoundFieldSETStatus "声场设置状态";
CM_ SG_ 782 AMP_MediaVolSETStatus "多媒体音量设置状态";
CM_ SG_ 1368 WLCM_WirelessChargingSetStatus "无线充电设置反馈";
CM_ SG_ 1368 WLCM_WirelessChargingStatus "无线充电工作状态反馈";
CM_ SG_ 738 RRS_RRMSensorDiagnosis "RRS右后中雷达传感器诊断信号";
CM_ SG_ 738 RRS_LRMSensorDiagnosis "RRS左后中雷达传感器诊断信号";
CM_ SG_ 738 RRS_RRCSensorDiagnosis "RRS右后雷达传感器诊断信号";
CM_ SG_ 738 RRS_LRCSensorDiagnosis "RRS左后雷达传感器诊断信号";
CM_ SG_ 738 RRS_RFMSensorDiagnosis "RRS右前中雷达传感器诊断信号";
CM_ SG_ 738 RRS_LFMSensorDiagnosis "RRS左前中雷达传感器诊断信号";
CM_ SG_ 738 RRS_RFCSensorDiagnosis "RRS右前雷达传感器诊断信号";
CM_ SG_ 738 RRS_LFCSensorDiagnosis "RRS左前雷达传感器诊断信号";
CM_ SG_ 737 RRS_LoudspeakersPosition "扬声器位置";
CM_ SG_ 737 RFM_Sector_Dist "右前中扇区距离";
CM_ SG_ 737 LFM_Sector_Dist "左前中扇区距离";
CM_ SG_ 737 RFC_Sector_Dist "右前角扇区距离";
CM_ SG_ 737 LFC_Sector_Dist "左前角扇区距离";
CM_ SG_ 737 RRC_Sector_Dist "右后角扇区距离";
CM_ SG_ 737 LRC_Sector_Dist "左后角扇区距离";
CM_ SG_ 737 RRM_Sector_Dist "右后中扇区距离";
CM_ SG_ 737 LRM_Sector_Dist "左后中扇区距离";
CM_ SG_ 736 RRS_SpkErrFlag "Speaker错误标志位";
CM_ SG_ 736 RRS_RFMSnsErrFlag "右前中sensor错误标志位";
CM_ SG_ 736 RRS_LFMSnsErrFlag "左前中sensor错误标志位";
CM_ SG_ 736 RRS_SystemFailureFlag "系统故障";
CM_ SG_ 736 RRS_SwitchIndicatorError "倒车雷达开关指示灯故障";
CM_ SG_ 736 RRS_ctrlModulErrFlag "EEPROM错误标志位";
CM_ SG_ 736 RRS_BattVoltErrFlag "IGN电压错误标志位";
CM_ SG_ 736 RRS_RRMidSnsErrFlag "右后中sensor错误标志位";
CM_ SG_ 736 RRS_LRMidSnsErrFlag "左后中sensor错误标志位";
CM_ SG_ 736 RRS_RRCSnsErrFlag "右后sensor错误标志位";
CM_ SG_ 736 RRS_LRCSnsErrFlag "左后sensor错误标志位";
CM_ SG_ 736 RRS_RFCSnsErrFlag "右前sensor错误标志位";
CM_ SG_ 736 RRS_LFCSnsErrFlag "左前sensor错误标志位";
CM_ SG_ 736 RRS_WarningFrequency "前后角识别";
CM_ SG_ 736 RRS_FrontRadarActiveStatus "前雷达激活设置反馈";
CM_ SG_ 736 RRS_WarningType "报警方式识别";
CM_ SG_ 736 RRS_PDC_Status "倒车雷达的工作模式";
CM_ SG_ 736 RRS_RFMDistance "右前中sensor障碍物距离";
CM_ SG_ 736 RRS_LFMDistance "左前中sensor障碍物距离";
CM_ SG_ 736 RRS_LFCDistance "左前sensor障碍物距离";
CM_ SG_ 736 RRS_RFCDistance "右前sensor障碍物距离";
CM_ SG_ 736 RRS_LRCDistance "左后角sensor障碍物距离";
CM_ SG_ 736 RRS_RRCDistance "右后角sensor障碍物距离";
CM_ SG_ 736 RRS_LRMDistance "后左中sensor障碍物距离";
CM_ SG_ 736 RRS_RRMDistance "后右中sensor障碍物距离";
CM_ SG_ 651 BCM_CRCCheck_28B "BCM_28B校验和";
CM_ SG_ 651 BCM_RollingCounter_28B "BCM_28B计数器";
CM_ SG_ 651 BCM_KeyAlarmStatus "警戒状态信息";
CM_ SG_ 651 PEPS_ShiftForbidReq "换挡禁止请求";
CM_ SG_ 651 BCM_RearDefrosterstatus "后除霜工作状态";
CM_ SG_ 651 BCM_PowerStatusFeedback "电源状态反馈";
CM_ SG_ 651 BCM_emergencylightstatus "紧急报警灯状态";
CM_ SG_ 651 PEPS_RemoteStartReq "遥控或远程起动请求";
CM_ SG_ 651 LCM_LASSwitch "LAS开关信号";
CM_ SG_ 651 PEPS_StartControlsignal "启动控制信号";
CM_ SG_ 651 BCM_HoodStatus "发动机舱盖状态";
CM_ SG_ 651 BCM_TurnIndicatorRight "右转向灯信号";
CM_ SG_ 651 BCM_TurnIndicatorLeft "左转向灯信号";
CM_ SG_ 651 BCM_DriverDoorStatus "左前门状态";
CM_ SG_ 651 BCM_HU_LampHeightLevFeedback "大灯高度设置反馈";
CM_ SG_ 651 BCM_ReversePosition "倒档信号状态";
CM_ SG_ 651 PEPS_EngineStallReq "发动机熄火请求";
CM_ SG_ 651 BCM_TurnLightSwitchSts "转向灯开关状态信号";
CM_ SG_ 651 BCM_HighBeamStatus "远光灯工作状态";
CM_ SG_ 651 BCM_LowBeamStatus "近光灯工作状态";
CM_ SG_ 610 PEPS_CRCCheck_262 "PEPS_262较验和";
CM_ SG_ 610 BCM_PEPS_BlueTooth "蓝牙有效标记位";
CM_ SG_ 610 PEPS_RollingCounter_262 "PEPS_262计数器";
CM_ SG_ 610 PEPS_APARemoteParkingOff "遥控泊车一键关闭";
CM_ SG_ 610 PEPS_KeyStandbyPositionIndicator "钥匙备用启动位置提示";
CM_ SG_ 610 PEPS_PEPSFailStatus "PEPS系统故障";
CM_ SG_ 610 PEPS_IMMOFeedback "IMMO认证反馈";
CM_ SG_ 610 PEPS_EngineStartupInhibitFB "启动禁止状态反馈结果";
CM_ SG_ 610 PEPS_PowerDistributionFaultBit "电源分配故障";
CM_ SG_ 610 PEPS_TBOX_RemoteIGNOnOffFeedback "远程上下电请求反馈";
CM_ SG_ 610 PEPS_FRCameraStart "人脸识别控制器请求信号";
CM_ SG_ 610 PEPS_PowerOff_NotPN_AlarmSignal "下电档位报警信号";
CM_ SG_ 610 PEPS_EngineStartupInhibitSts "启动禁止状态信号";
CM_ SG_ 610 PEPS_APA_PowerMirrorFoldFeedback "泊车过程外后视镜折叠状态反馈";
CM_ SG_ 610 PEPS_RemoteStartFeedback "遥控及远程启动反馈";
CM_ SG_ 610 PEPS_StartupButtonSignal "启动按钮状态信号";
CM_ SG_ 610 PEPS_IMMOFailedAlarmsignal "IMMO认证失败报警信号";
CM_ SG_ 610 PEPS_UnallowStartSignal_Not_PN "启动时档位报警信号";
CM_ SG_ 610 PEPS_EngineRuningWarning "怠速未熄火报警";
CM_ SG_ 610 PEPS_UnallowStart_ESCL_LOCK "启动电子转向锁未解锁报警";
CM_ SG_ 610 PEPS_PowerDistributionStatus "电源分配状态信号";
CM_ SG_ 610 PEPS_RemoteControlACReq "遥控控制空调请求";
CM_ SG_ 610 PEPS_APA_CloseWinFeedback "遥控泊车完成关窗请求反馈";
CM_ SG_ 610 PEPS_UnallowStart_ESCL_Error "启动时电子转向锁故障报警";
CM_ SG_ 610 PEPS_APARemoteParkingSwitch "遥控泊车一键启动";
CM_ SG_ 610 PEPS_APA_LockFeedback "遥控泊车完成闭锁请求反馈";
CM_ SG_ 610 PEPS_APA_Engine0ffFeedback "遥控泊车完成熄火请求反馈";
CM_ SG_ 610 PEPS_RemoteAPADoneKeyOffReq "遥控APA后钥匙熄火请求";
CM_ SG_ 610 PEPS_StartIndicatorSignal "启动方式提示信号";
CM_ SG_ 1607 FIS_ResourceID "录入人脸图片存储位置标识";
CM_ SG_ 1607 FIS_InCarCameraCoDriverIDSignal "车内摄像头副驾ID信息";
CM_ SG_ 1607 FIS_LoggingDataStatus "人脸录入状态信号";
CM_ SG_ 1607 FIS_LoggingDataErrorFeedBack "人脸录入条件不满足反馈";
CM_ SG_ 1606 FIS_ID_Name_FISame3 "用户ID名字第三个字";
CM_ SG_ 1606 FIS_ID_Name_FISame2 "用户ID名字第二个字";
CM_ SG_ 1606 FIS_ID_Name_FISame1 "用户ID名字第一个字";
CM_ SG_ 1606 FIS_Name_Length "用户名字长度";
CM_ SG_ 1606 FIS_ID_Name_FrameNumber "用户名字序列号";
CM_ SG_ 1606 FIS_Out_CarCameraIDSignal "车外摄像头用户ID信息";
CM_ SG_ 1606 FIS_InCarCaMasDriverIDSignal "车内摄像头主驾ID信息";
CM_ SG_ 1605 FIS_BoundStatus "人脸识别绑定状态";
CM_ SG_ 1605 FIS_USBDiagnosis "USB诊断信号";
CM_ SG_ 1605 FIS_InCarSensorDiagnosis "车内摄像头诊断信号";
CM_ SG_ 1605 FIS_OutCarSensorDiagnosis "车外摄像头诊断信号";
CM_ SG_ 1605 FIS_GRSSubSetFeedback8 "GRS手势识别食指旋转手势设置反馈";
CM_ SG_ 1605 FIS_GRSSubSetFeedback9 "GRS手势识别拳头手势设置反馈";
CM_ SG_ 1605 FIS_GRSSubSetFeedback6 "GRS手势识别手掌滑动手势设置反馈";
CM_ SG_ 1605 FIS_ID_DeleteRequestFeedback "人脸识别ID删除请求反馈";
CM_ SG_ 1605 FIS_GRSSubSetFeedback7 "GRS手势识别比心手势设置反馈";
CM_ SG_ 1605 FIS_GRSSubSetFeedback5 "GRS手势识别车外拜拜手势设置反馈";
CM_ SG_ 1605 FIS_GRSSubSetFeedback4 "GRS手势识别胜利手势设置反馈";
CM_ SG_ 1605 FIS_GRSSubSetFeedback3 "GRS手势识别点赞手势设置反馈";
CM_ SG_ 1605 FIS_GRSSubSetFeedback2 "GRS手势识别伸手掌手势设置反馈";
CM_ SG_ 1605 FIS_GRSSubSetFeedback1 "GRS手势识别OK手势设置反馈";
CM_ SG_ 1605 FIS_GRSsetFeedback "GRS功能设置反馈";
CM_ SG_ 1605 FIS_Gesture_recognition_Request "手势识别功能请求";
CM_ SG_ 1605 FIS_FISDMSSubSetFeedback4 "疲劳驾驶提醒设置反馈";
CM_ SG_ 1605 FIS_FISDMSSubSetFeedback3 "手持电话提醒设置反馈";
CM_ SG_ 1605 FIS_FISDMSSubSetFeedback2 "抽烟提醒设置反馈";
CM_ SG_ 1605 FIS_FISDMSSubSetFeedback1 "注意力分散提醒设置反馈";
CM_ SG_ 1605 FIS_SpeedLimit "车速限制信号";
CM_ SG_ 1605 FIS_FirePermit "FaceID匹配允许点火";
CM_ SG_ 1605 FIS_UnLockPermit "FaceID匹配允许解锁";
CM_ SG_ 1605 FIS_Certificate_failed_reasons "人脸识别认证失败原因";
CM_ SG_ 1605 FIS_Certificate_failed_times "人脸识别认证失败次数";
CM_ SG_ 1605 FIS_DMSStatus "DMS报警状态";
CM_ SG_ 1605 FIS_Status "人脸识别状态";
CM_ SG_ 1605 FIS_InCarCameracoveredRemind "车内摄像头遮挡提醒";
CM_ SG_ 1605 FIS_AuthenAgainPrompt "人脸识别提示重新认证";
CM_ SG_ 1605 FIS_DistinguishFlag_InCar "车内人脸识别有效标记位";
CM_ SG_ 1605 FIS_VINReq "VIN码查询请求";
CM_ SG_ 1605 FIS_GameStartStst "游戏开始状态";
CM_ SG_ 1605 FIS_CertificateSignal "人脸识别控制器认证信号";
CM_ SG_ 1605 FIS_GameCount "游戏计数";
CM_ SG_ 935 FIS_CRCCheck_3A7 "FIS_3A7校验和";
CM_ SG_ 935 FIS_RollingCounter_3A7 "FIS_3A7计数器";
CM_ SG_ 935 FIS_UserStature "用户身高";
CM_ SG_ 935 FIS_PassengerDrowsinessStatus "FIS副驾疲劳状态";
CM_ SG_ 864 FIS_CRCCheck_360 "FIS_360校验和";
CM_ SG_ 864 FIS_RollingCounter_360 "FIS_360计数器";
CM_ SG_ 864 FIS_JawOffset_Value "覆盖下超差";
CM_ SG_ 864 FIS_BrowOffsetValue "覆盖上超差";
CM_ SG_ 864 FIS_HeadDetectSts_Yaw "头部首摇状态";
CM_ SG_ 864 FIS_HeadDetectSts_Roll "头部横摇状态";
CM_ SG_ 864 FIS_HeadDetectSts_Pitch "头部纵摇状态";
CM_ SG_ 854 FIS_CRCCheck_356 "FIS_356校验和";
CM_ SG_ 854 FIS_DriverEyeConfidence "眼部置信度";
CM_ SG_ 854 FIS_RollingCounter_356 "FIS_356计数器";
CM_ SG_ 854 FIS_DriverEyesFovArea "驾驶员视线所在区域";
CM_ SG_ 854 FIS_AttributeStatus "属性状态";
CM_ SG_ 854 FIS_EmotionStatus "情绪状态";
CM_ SG_ 854 FIS_EyeGazeStatus "视线追踪状态（YAW）";
CM_ SG_ 854 FIS_DriverEyeDetect "眼部检测功能状态";
CM_ SG_ 854 FIS_PassengerSmokeCallSts "副驾抽烟状态";
CM_ SG_ 854 FIS_DriverSmokeSts "驾驶员抽烟状态";
CM_ SG_ 854 FIS_PassengerPhoneCallSts "副驾打电话状态";
CM_ SG_ 854 FIS_DriverPhoneCallSts "驾驶员打电话状态";
CM_ SG_ 854 FIS_EyeDetectSatus "眼部检测状态";
CM_ SG_ 854 FIS_FISStatus "FIS系统状态";
CM_ SG_ 854 FIS_DrowsinessStatus "FIS疲劳状态";
CM_ SG_ 854 FIS_DistractionStatus "FIS注意力分散状态";
CM_ SG_ 1554 AVM_FormatFAT32Req "TF卡格式化FAT32请求";
CM_ SG_ 1554 AVM_CurrentVideo_counts "当前页视频/图片数量";
CM_ SG_ 1554 AVM_DVRDeleteStatus "删除状态反馈";
CM_ SG_ 1554 DVR_PrintScreenFeedback "DVR截图确认";
CM_ SG_ 1554 AVM_DVRReplaySpeedStatus "视频回放指令反馈";
CM_ SG_ 1554 AVM_DVRReplayCommandStatus "视频回放指令";
CM_ SG_ 1554 DVR_StorageStatus "DVR存储介质信息";
CM_ SG_ 1554 DVR_NormalToEmergency "DVR循环录制转紧急录制";
CM_ SG_ 1554 DVR_StoragePercent "存储占用百分比";
CM_ SG_ 1554 DVR_DistortCorrection "DVR畸变校正";
CM_ SG_ 1554 AVM_DVRModeFeedback "DVR模式反馈";
CM_ SG_ 1554 DVR_ReplayMode "DVR回放模式";
CM_ SG_ 1554 AVM_DVREditFeedback "DVR编辑状态反馈";
CM_ SG_ 1554 DVR_FormatStatus "格式化状态反馈";
CM_ SG_ 1554 DVR_EmergencyRecordStatus "一键紧急录制反馈信号";
CM_ SG_ 1554 DVR_DVRErrorRecordStatus "故障记录信息查询反馈信号";
CM_ SG_ 1554 DVR_PhotographResult "照相结果";
CM_ SG_ 1554 DVR_DisplayVison "全景DVR显示角度";
CM_ SG_ 1554 DVR_Error "DVR系统故障";
CM_ SG_ 1554 DVR_RecordingCycleSetStatus "DVR录制时长设置状态";
CM_ SG_ 1554 DVR_DVRTapeSetStatus "DVR录音设置状态";
CM_ SG_ 1554 DVR_DVREnableSetStatus "DVR使能设置状态";
CM_ SG_ 941 DVR_SystemVersion "DVR系统版本";
CM_ SG_ 941 DVR_UpdateResult "DVR升级结果";
CM_ SG_ 941 DVR_SdcardFullStatus "DVR__SD卡满状态";
CM_ SG_ 941 DVR_SdcardErrorStatus "DVR_SD卡错误状态";
CM_ SG_ 992 AVM_StartOpenAvmSts "起步开全景设置状态";
CM_ SG_ 992 DVR_UploadFeedback "DVR上传反馈信号";
CM_ SG_ 992 AVM_AVMOffSpeedStatus "退出车速限制状态反馈";
CM_ SG_ 992 AVM_TransparentCarFeedback "透明车身反馈信号";
CM_ SG_ 992 AVM_DVRVideoPlayTime "当前视频已播放时间";
CM_ SG_ 992 AVM_DVRVideoTimeLength "当前播放视频时间长度";
CM_ SG_ 992 AVM_TurnlightFeedback "转向灯触发全景反馈信号";
CM_ SG_ 992 AVM_RadarAVMFeedback "雷达触发全景反馈信号";
CM_ SG_ 992 AVM_CalibrationComfirm "标定确认反馈";
CM_ SG_ 992 AVM_CalibrationStatus "自动标定状态";
CM_ SG_ 992 AVM_MODAlert_Sound "移动物体检测声音报警信号";
CM_ SG_ 992 AVM_MODFeedback "移动物体检测反馈信号";
CM_ SG_ 992 AVM_3DFeedback "3D显示反馈信号";
CM_ SG_ 992 AVM_TopLookDownFeedback "自动俯视大图反馈信号";
CM_ SG_ 992 AVM_RecordFeedback "录制完成反馈信号";
CM_ SG_ 992 AVM_VisionAngle "AVM_显示角度";
CM_ SG_ 992 AVM_LineOnOff "辅助线开启关闭";
CM_ SG_ 992 AVM_OverspeedWarning "AVM速度过快禁止显示提醒";
CM_ SG_ 992 AVM_DisplayReq "AVM显示请求";
CM_ SG_ 992 AVM_DisplayForm "AVM显示形式";
CM_ SG_ 1365 TBOX_CRCCheck_555 "TBOX_555校验和";
CM_ SG_ 1365 TBOX_TUIDNumber "TUID数字";
CM_ SG_ 1365 TBOX_TUIDFrameNumber "TUID帧序号";
CM_ SG_ 1343 TBOX_RmoteRoof "天窗及遮阳帘开关状态";
CM_ SG_ 1343 TBOX_RmoteTrunk "远程行李箱控制";
CM_ SG_ 1343 TBOX_RmoteWindows "远程车窗控制";
CM_ SG_ 1343 TBOX_SunroofControlReq "远程天窗控制（天窗起翘）";
CM_ SG_ 719 TBOX_BLEDataFlow "数据流报文";
CM_ SG_ 909 TBOX_RemoteDrVentilatieReq "远程主驾座椅通风请求";
CM_ SG_ 909 TBOX_RemotePaVentilatieReq "远程副驾座椅通风请求";
CM_ SG_ 909 TBOX_RemoteInstallReq "远程安装请求";
CM_ SG_ 909 TBOX_RemoteDetectReq "远程监控请求信号";
CM_ SG_ 909 TBOX_RemoteAirCleanReq "远程空气净化请求";
CM_ SG_ 909 TBOX_CirculationModeReq "循环模式设定请求信号";
CM_ SG_ 909 TBOX_RemoteAirQualityInquire "远程车内空气质量查询";
CM_ SG_ 909 TBOX_RemoteSteerWheelHotReq "远程方向盘加热请求";
CM_ SG_ 909 TBOX_RemoteDriverSeatHotReq "远程主驾座椅加热请求";
CM_ SG_ 909 TBOX_RemotePassangerSeatHotReq "远程副驾座椅加热请求";
CM_ SG_ 909 TBOX_SearchCarReq "远程寻车";
CM_ SG_ 909 TBOX_ACFanAdjustValueReq "风量设定请求信号";
CM_ SG_ 909 TBOX_RemoteACStartupReq "远程控制空调请求";
CM_ SG_ 909 TBOX_VehicleStatusDemandReq "车辆信息查询信号";
CM_ SG_ 909 TBOX_RemoteStartRunTime "远程启动运行时间";
CM_ SG_ 909 TBOX_VINMatchStatus "VIN码匹配状态";
CM_ SG_ 909 TBOX_VINReq "VIN码查询请求";
CM_ SG_ 909 TBOX_BCallStatus "一键呼通话状态";
CM_ SG_ 909 TBOX_ACTempValueReq "主驾温度请求信号";
CM_ SG_ 909 TBOX_CarRemind "停车位置提示";
CM_ SG_ 909 TBOX_AudioRequest "扬声器请求";
CM_ SG_ 909 TBOX_ChangePartStatus "TBOX换件状态";
CM_ SG_ 909 TBOX_CallStatus "通话状态";
CM_ SG_ 909 TBOX_RemoteEngineStartupReq "远程启动发动机请求";
CM_ SG_ 909 TBOX_EngineStartupInhibit "禁止发动机启动";
CM_ SG_ 909 TBOX_LockCommand "远程解闭锁请求";
CM_ SG_ 909 TBOX_VehicleVedioDetectReq "全车视频监控请求";
CM_ SG_ 908 TBOX_RemoteWindowSignalReq "远程遥控车窗请求";
CM_ SG_ 908 TBOX_MaintainMessageReq "保养提示信息查询请求";
CM_ SG_ 908 TBOX_TrunkReq "远程行李箱请求";
CM_ SG_ 908 TBOX_PositionLampReq "远程位置灯请求";
CM_ SG_ 908 TBOX_RemoteSunroofSignalReq "远程遥控天窗请求";
CM_ SG_ 908 TBOX_FaceIDupdate "人脸识别用户ID更新";
CM_ SG_ 908 TBOX_RemotedefrostingReq "远程除霜请求";
CM_ SG_ 908 TBOX_activateStatus "TBOX激活状态";
CM_ SG_ 623 BM_BLEConnectSts "手机与蓝牙的连接状态";
CM_ SG_ 623 VIN_VeritfyResult "VIN码认证结果";
CM_ SG_ 623 BM_BTKeyNumber "蓝牙钥匙编号";
CM_ SG_ 623 BM_MPPosition "手机的当前位置";
CM_ SG_ 623 BM_ConnectSts "手机与蓝牙模块的连接状态";
CM_ SG_ 622 BM_OneTouchDirectionSelect "一键召唤方向选择";
CM_ SG_ 622 BM_OneTouchResponseSwitch "一键召唤功能手机开关";
CM_ SG_ 622 BM_RPASwitch "遥控泊车开关";
CM_ SG_ 622 BM_APAFunctionmoduleEnable "APA功能模式使能";
CM_ SG_ 622 BM_AllWindowCommand "所有车窗控制";
CM_ SG_ 622 BM_APAManeuverStart "APA手动开启";
CM_ SG_ 622 BM__StartControlsignal "遥控钥匙启动控制信号";
CM_ SG_ 622 BM_APAManeuverCancel "APA手动取消";
CM_ SG_ 622 BM_APAManeuverSuspend "APA手动暂停";
CM_ SG_ 622 BM_All_WindowClose "关车窗";
CM_ SG_ 622 BM_All_WindowOpen "开车窗";
CM_ SG_ 622 BM_APAPOCModeSelect "泊出方向模式选择";
CM_ SG_ 622 BM_SearchCarSignal "寻车信号";
CM_ SG_ 622 BM_LuggageUnlockSignal "行李箱解锁信号";
CM_ SG_ 622 BM_LuggagelockSignal "行李箱闭锁信号";
CM_ SG_ 622 BM_SunroofClose "关天窗";
CM_ SG_ 622 BM_SunroofOpen "开天窗";
CM_ SG_ 622 BM_LockSignal "闭锁信号";
CM_ SG_ 622 BM_UnlockSignal "解锁信号";
CM_ SG_ 652 HU_FIS_DIST_switch_signal "多功能方向盘巡航时距调节";
CM_ SG_ 652 HU_FIS_IACCenable_switch_signal "多功能方向盘IACC使能";
CM_ SG_ 652 HU_FIS_Crusie_switch_signal "多功能方向盘巡航开启";
CM_ SG_ 652 HU_FIS_RESPlus_switch_signal "多功能方向盘巡航速度加/恢复";
CM_ SG_ 652 HU_FIS_SETReduce_switch_signal "多功能方向盘巡航速度减/设置";
CM_ SG_ 1603 OpenIDCharsValid "人脸识别图片OpenID字符有效位";
CM_ SG_ 1602 OpenIDChars31 "人脸识别图片OpenID字符31";
CM_ SG_ 1602 OpenIDChars30 "人脸识别图片OpenID字符30";
CM_ SG_ 1602 OpenIDChars29 "人脸识别图片OpenID字符29";
CM_ SG_ 1602 OpenIDChars28 "人脸识别图片OpenID字符28";
CM_ SG_ 1602 OpenIDChars27 "人脸识别图片OpenID字符27";
CM_ SG_ 1602 OpenIDChars26 "人脸识别图片OpenID字符26";
CM_ SG_ 1602 OpenIDChars25 "人脸识别图片OpenID字符25";
CM_ SG_ 1602 OpenIDChars24 "人脸识别图片OpenID字符24";
CM_ SG_ 1602 OpenIDChars23 "人脸识别图片OpenID字符23";
CM_ SG_ 1602 OpenIDChars22 "人脸识别图片OpenID字符22";
CM_ SG_ 1602 OpenIDChars21 "人脸识别图片OpenID字符21";
CM_ SG_ 1602 OpenIDChars20 "人脸识别图片OpenID字符20";
CM_ SG_ 1602 OpenIDChars19 "人脸识别图片OpenID字符19";
CM_ SG_ 1602 OpenIDChars18 "人脸识别图片OpenID字符18";
CM_ SG_ 1602 OpenIDChars17 "人脸识别图片OpenID字符17";
CM_ SG_ 1602 OpenIDChars16 "人脸识别图片OpenID字符16";
CM_ SG_ 1601 OpenIDChars15 "人脸识别图片OpenID字符15";
CM_ SG_ 1601 OpenIDChars14 "人脸识别图片OpenID字符14";
CM_ SG_ 1601 OpenIDChars13 "人脸识别图片OpenID字符13";
CM_ SG_ 1601 OpenIDChars12 "人脸识别图片OpenID字符12";
CM_ SG_ 1601 OpenIDChars11 "人脸识别图片OpenID字符11";
CM_ SG_ 1601 OpenIDChars10 "人脸识别图片OpenID字符10";
CM_ SG_ 1601 OpenIDChars9 "人脸识别图片OpenID字符9";
CM_ SG_ 1601 OpenIDChars8 "人脸识别图片OpenID字符8";
CM_ SG_ 1601 OpenIDChars7 "人脸识别图片OpenID字符7";
CM_ SG_ 1601 OpenIDChars6 "人脸识别图片OpenID字符6";
CM_ SG_ 1601 OpenIDChars5 "人脸识别图片OpenID字符5";
CM_ SG_ 1601 OpenIDChars4 "人脸识别图片OpenID字符4";
CM_ SG_ 1601 OpenIDChars3 "人脸识别图片OpenID字符3";
CM_ SG_ 1601 OpenIDChars2 "人脸识别图片OpenID字符2";
CM_ SG_ 1601 OpenIDChars1 "人脸识别图片OpenID字符1";
CM_ SG_ 1601 OpenIDChars0 "人脸识别图片OpenID字符0";
CM_ SG_ 1598 HU_DSMPassengerOneKeyForwordReq "副驾一键向前请求";
CM_ SG_ 1598 HU_DSMPassengerBackAngleRequest "副驾倾斜角度请求";
CM_ SG_ 1598 HU_DSMPassengerFrontRearPositionRequest "副驾前后位置请求";
CM_ SG_ 1598 HU_DSMPassengerHighLowPositionRequest "副驾座椅高低位置请求";
CM_ SG_ 1550 HU_MirrorPositionSaved_Reques "后视镜保存到某位置请求";
CM_ SG_ 1550 HU_DSMComity_SwitchSet "座椅礼让位置设置开关";
CM_ SG_ 1550 HU_DSMRighttMirrorYPositionRequest "右后视镜Y轴位置请求";
CM_ SG_ 1550 HU_DSMRightMirrorXPositionRequest "右后视镜X轴位置请求";
CM_ SG_ 1550 HU_DSMLeftMirrorYPositionRequest "左后视镜Y轴位置请求";
CM_ SG_ 1550 HU_DSMLeftMirrorXPositionRequest "左后视镜X轴位置请求";
CM_ SG_ 1550 HU_DSMDriverBackAngleRequest "主驾倾斜角度请求";
CM_ SG_ 1550 HU_DSMDriverFrontRearPositionRequest "主驾前后位置请求";
CM_ SG_ 1550 HU_Current_position "HU页面当前状态";
CM_ SG_ 1550 HU_DSMDriverHighLowPositionRequest "座椅高低位置请求";
CM_ SG_ 1550 HU_PaDSMPositionRequest "车机请求副驾到某位置";
CM_ SG_ 1550 HU_DrDSMPositionRequest "车机请求主驾到某位置";
CM_ SG_ 1550 HU_PaDSMPositionSavedRequest "副驾座椅保存到某位置";
CM_ SG_ 1550 HU_DrDSMPositionSavedRequest "主驾座椅保存到某位置";
CM_ SG_ 1550 HU_DSMComitySet "座椅礼让设置";
CM_ SG_ 1550 HU_FRFuntionSet "人脸识别功能设置";
CM_ SG_ 1550 HU_MirrorTurnSet "挂倒挡后视镜自动翻转设置";
CM_ SG_ 1550 HU_DSM_PositionSaved_Feedback "座椅位置保存反馈";
CM_ SG_ 1546 HU_NavNextName_FISame3 "下个导航路口名字第三个字";
CM_ SG_ 1546 HU_NavNextName_FISame2 "下个导航路口名字二个字";
CM_ SG_ 1546 HU_NavNextName_FISame1 "下个导航路口名字第一个字";
CM_ SG_ 1546 HU_NavNextName_Length "下个导航路口名字名字长度";
CM_ SG_ 1546 HU_NavNextName_FrameNumber "下个导航路口名字序列号";
CM_ SG_ 1549 HU_GameStartRuest "游戏开始请求";
CM_ SG_ 1549 HU_GRSSubSet9 "GRS手势识别拳头手势设置";
CM_ SG_ 1549 HU_GRSSubSet8 "GRS手势识别食指旋转手势设置";
CM_ SG_ 1549 HU_GRSSubSet7 "GRS手势识别比心手势设置";
CM_ SG_ 1549 HU_GRSSubSet6 "GRS手势识别手掌滑动手势设置";
CM_ SG_ 1549 HU_LoggingDataReq "人脸录入请求信号";
CM_ SG_ 1549 HU_GRSSubSet5 "GRS手势识别车外拜拜手势设置";
CM_ SG_ 1549 HU_GRSSubSet4 "GRS手势识别胜利手势设置";
CM_ SG_ 1549 HU_GRSSubSet3 "GRS手势识别点赞手势设置";
CM_ SG_ 1549 HU_GRSSubSet2 "GRS手势识别伸手掌手势设置";
CM_ SG_ 1549 HU_GRSSubSet1 "GRS手势识别OK手势设置";
CM_ SG_ 1549 HU_GRSset "GRS功能设置";
CM_ SG_ 1549 HU_DSMUserIDDelete "删除记忆位置ID信号";
CM_ SG_ 1545 IP_HUHeartbeat "仪表车机心跳信号";
CM_ SG_ 1544 HU_IPHeartbeat "车机仪表心跳信号";
CM_ SG_ 1543 HU_IpInformatTtransSts "车机仪表信息传输状态";
CM_ SG_ 1543 HU_FlyingScreen_Request "三指飞屏请求";
CM_ SG_ 1543 HU_IPConnection_acknowledge "仪表车机连接请求";
CM_ SG_ 1542 CheckSum "校验码";
CM_ SG_ 1542 LiteralEncoding "文字编码";
CM_ SG_ 1542 SongsAbsoluteID "歌曲绝对ID";
CM_ SG_ 1542 UpdateAttibute "更新属性";
CM_ SG_ 1542 ListMode "列表类型";
CM_ SG_ 1542 LenthOFMultipleFrame "数据长度";
CM_ SG_ 1542 FrameType "帧类型";
CM_ SG_ 1552 ListStatus "列表状态";
CM_ SG_ 1552 NumbersOfCallingRecord "通话记录总数量（计算滚动条位置）";
CM_ SG_ 1552 CurrentPhoneID "当前电话滚动ID";
CM_ SG_ 1552 CallingStatus "通话状态";
CM_ SG_ 1552 ListTyp "列表类型";
CM_ SG_ 1540 FifteenthPhoneID "第15个电话滚动ID";
CM_ SG_ 1540 FourteenthPhoneID "第14个电话滚动ID";
CM_ SG_ 1540 ThirteenthPhoneID "第13个电话滚动ID";
CM_ SG_ 1540 TwelfthPhoneID "第12个电话滚动ID";
CM_ SG_ 1540 EleventhPhoneID "第11个电话滚动ID";
CM_ SG_ 1540 TenthPhoneID "第10个电话滚动ID";
CM_ SG_ 1540 NinthPhoneID "第9个电话滚动ID";
CM_ SG_ 1540 EighthPhoneID "第8个电话滚动ID";
CM_ SG_ 1540 SeventhPhoneID "第7个电话滚动ID";
CM_ SG_ 1540 SixthPhoneID "第6个电话滚动ID";
CM_ SG_ 1540 FifthPhoneID "第5个电话滚动ID";
CM_ SG_ 1540 ForthPhoneID "第4个电话滚动ID";
CM_ SG_ 1540 ThirdPhoneID "第3个电话滚动ID";
CM_ SG_ 1540 SecondPhoneID "第2个电话滚动ID";
CM_ SG_ 1540 FirstPhoneID "第1个电话滚动ID";
CM_ SG_ 1539 CurrentSongID "当前歌曲绝对ID";
CM_ SG_ 1539 PlayStatus "歌曲状态";
CM_ SG_ 1539 ListType "列表类型";
CM_ SG_ 1538 CheckSumReversed "预留校验码";
CM_ SG_ 1538 NumbersOfSong "歌曲总数量（计算滚动条位置）";
CM_ SG_ 1538 ICCursorPositionID "IC光标位置的绝对ID";
CM_ SG_ 1538 ICFirstLineDisplayID "IC首行显示的绝对ID";
CM_ SG_ 1538 HU_ListStatus "列表状态";
CM_ SG_ 1538 ListMod "列表类型";
CM_ SG_ 1537 HU_DMS_Broadcast_Feedback "DMS语音播报反馈";
CM_ SG_ 1537 HU_DVRReplay_Video_Command "视频回放操作";
CM_ SG_ 1537 HU_FISDMSSubSet4 "疲劳驾驶提醒设置";
CM_ SG_ 1537 HU_FISDMSSubSet3 "手持电话提醒设置";
CM_ SG_ 1537 HU_FISDMSSubSet2 "抽烟提醒设置";
CM_ SG_ 1537 HU_FISDMSSubSet1 "注意力分散提醒设置";
CM_ SG_ 1537 HU_FRDMSset "驾驶员智能关怀系统设置";
CM_ SG_ 1537 HU_CarWashModel "洗车模式信号";
CM_ SG_ 1537 HU_ODEnable "目标检测开关信号";
CM_ SG_ 1537 HU_ValetModel "朋友模式信号";
CM_ SG_ 1537 HU_WiperServiceReq "雨刮维修模式信号";
CM_ SG_ 1537 HU_BreathingLightSet "迎宾灯开关设置";
CM_ SG_ 1537 HU_LockAutoClsSunroofSet "闭锁关天窗设置";
CM_ SG_ 1537 HU_HUDBrightAdjust "HUD亮度调节";
CM_ SG_ 1537 HU_CarWashMirrorFoldSet "洗车模式后视镜折叠设置";
CM_ SG_ 1537 HU_AutoTurnOnOffSwitch "自动转向灯开启关闭";
CM_ SG_ 1537 HU_HUDPosAdjust "HUD高度调节";
CM_ SG_ 1537 HU_FCWSensitivity "FCW灵敏度";
CM_ SG_ 1408 HU_LeaveMaintainMileage "剩余保养里程";
CM_ SG_ 1408 HU_LeaveMaintainDay "剩余保养时间";
CM_ SG_ 1408 HU_MaintainRemindReq "保养提示请求信号";
CM_ SG_ 1405 HU_SunroofControlReq2 "天窗控制命令2";
CM_ SG_ 1405 HU_DSMMemoryPositionFeedback "座椅位置记忆反馈";
CM_ SG_ 1405 HU_FanComfortableModeSet "空调风量舒适模式设置";
CM_ SG_ 1405 HU_AutoDeFoggingSet "自动除雾设置信号";
CM_ SG_ 1405 HU_TunnelAutoRecycleSet "隧道内循环设置信号";
CM_ SG_ 1405 HU_VC_AtmosphereLightReq "语音开关氛围灯";
CM_ SG_ 1405 HU_BlueTooth_Reduce_WindSpeedSet "蓝牙通话降风速设置信号";
CM_ SG_ 1405 HU_ReserveGearAutoRecycleSet "倒车自动内循环设置信号";
CM_ SG_ 1405 HU_AutowindSet1 "钥匙开锁通风设置";
CM_ SG_ 1405 HU_RemoteControlSunroofSet "遥控控制天窗设置";
CM_ SG_ 1405 HU_AutowindSet3 "空调自干燥设置";
CM_ SG_ 1405 HU_AutowindSet2 "钥匙长按通风设置";
CM_ SG_ 1405 HU_VC_ShadingCurtainReq "语音开关遮阳帘";
CM_ SG_ 1370 HU_DVRUpdateReq "DVR升级请求";
CM_ SG_ 1370 HU__LicenseNumberCheckSum "车牌号值校验和";
CM_ SG_ 1370 HU_LicenseNumber "车牌号值";
CM_ SG_ 1370 HU_WheelHubSet "轮毂样式设置";
CM_ SG_ 1370 HU_AVMDVRReplayModeReq "全景行车记录回放模式请求";
CM_ SG_ 1370 HU_BodyColourSet "车身颜色设置";
CM_ SG_ 1363 HU_AlarmSoundSet "报警声音设置";
CM_ SG_ 1363 HU_BuzzingAlarmStatus "HU蜂鸣报警状态";
CM_ SG_ 1363 HU_HUDDisplayLDW "HUD是否显示LDW";
CM_ SG_ 1363 HU_HUDDisplayACC "HUD是否显示ACC";
CM_ SG_ 1363 HU_HUDDisplayNav "HUD是否显示导航";
CM_ SG_ 1363 HU_MessageAlertSoundSet "信息提示声音设置";
CM_ SG_ 1363 HU_WelcomeSoundSet "迎宾声音设置";
CM_ SG_ 1363 HU_RearSeatbeltWarningEnable "后排安全带未系报警使能";
CM_ SG_ 1363 HU_IPWarningVolumeSetting "仪表提示音音量设置";
CM_ SG_ 1363 HU_ACCPush "ACC推送";
CM_ SG_ 1363 HU_RADMWaringEnable "多功能后视摄像头报警使能";
CM_ SG_ 1363 HU_HUDDimAdjust "HUD背光调节";
CM_ SG_ 1362 HU_StartOpenAvmSet "车辆起步打开全景设置";
CM_ SG_ 1362 HU_AVMOffSpeedSet "全景退出车速限制设置";
CM_ SG_ 1362 HU_BSDLCASetting "盲点检测/换道辅助设置";
CM_ SG_ 1362 HU_FCWSetting "前碰撞预警设置";
CM_ SG_ 1362 HU_APAActive2 "泊车辅助功能激活";
CM_ SG_ 1362 HU_FrontRadarActive "前雷达功能激活";
CM_ SG_ 1362 HU_VC_CruiseSetSpeed "语音设置巡航车速";
CM_ SG_ 1362 HU_VC_CruiseControl "语音巡航控制";
CM_ SG_ 1362 HU_VC_CruiseSetDistance "语音设置巡航跟车距离";
CM_ SG_ 1362 HU_ACCObjEnable "车辆识别声音提示使能开关";
CM_ SG_ 1362 HU_AutoBrakeEnable "自动制动使能开关";
CM_ SG_ 1362 HU_CruiseControlSet "巡航状态设置";
CM_ SG_ 1341 HU_DriverWindowCommand "主驾车窗控制";
CM_ SG_ 1341 HU_PassengerWindowCommand "副驾车窗控制";
CM_ SG_ 1341 HU_LeftRearWindowCommand "左后车窗控制";
CM_ SG_ 1341 HU_RightRearWindowCommand "右后车窗控制";
CM_ SG_ 1341 HU_AllWindowCommand "所有车窗控制";
CM_ SG_ 1341 HU_SystemVolumeMute "娱乐系统静音";
CM_ SG_ 1341 HU_MultiMediaVolumeStatus "多媒体音量状态";
CM_ SG_ 1341 HU_TTSVolumeStatus "TTS音量状态";
CM_ SG_ 1341 HU_TeleTBOXVolumeStatus "电话/TBOX音量状态";
CM_ SG_ 1341 HU_NavVolumeStatus "导航声音音量状态";
CM_ SG_ 1338 HU_TrunkOpenLevSet "行李箱开启程度设置";
CM_ SG_ 1338 HU_BCM_LampHeightLevSet "大灯高度设置";
CM_ SG_ 1338 HU_MusicLightModeSelect "音乐灯光模式信号";
CM_ SG_ 1338 HU_OutLightFlashCtr "外灯控制信号";
CM_ SG_ 1338 HU_WelcomeLightModeSet "迎宾模式设置";
CM_ SG_ 1338 HU_MusicLightRequest "音乐灯光请求信号";
CM_ SG_ 1338 HU_MusicPlaySetBackSignal "音乐播放反馈信号";
CM_ SG_ 1338 HU_WelcomeAtmoLightEnable "开门氛围灯迎宾使能";
CM_ SG_ 1338 HU_WirelessChargingSet "无线充电设置";
CM_ SG_ 1338 HU_AtmoLightLinkDoorEnable "车门未关氛围灯提醒使能";
CM_ SG_ 1338 HU_AtmoLightLinkTopLightEnable "前顶灯氛围灯联动使能";
CM_ SG_ 1338 HU_AtmoLightLinkOverspeedEnable "超速氛围灯预警使能";
CM_ SG_ 1338 HU_AtmoLightLinkStartRequest "科技点火请求";
CM_ SG_ 1335 HU_RKEUnlockDoorTypeSet "遥控钥匙解锁模式设置";
CM_ SG_ 1335 HU_AutoIGNOFFUnlockSet "熄火自动解锁设置";
CM_ SG_ 1335 HU_RemoteControlWindowSet "遥控控制车窗设置";
CM_ SG_ 1335 HU_DrEasyEntrySet "主驾座椅礼让设置状态信号";
CM_ SG_ 1335 HU_PaEasyEntrySet "副驾座椅礼让设置状态信号";
CM_ SG_ 1335 HU_LaneChangeTurnLightSet "变道闪光设置信号";
CM_ SG_ 1335 HU_FollowMeHomeLightSet "跟随回家灯光设置信号";
CM_ SG_ 1335 HU_AtmoLightAAEnable "氛围灯自动调节使能设置";
CM_ SG_ 1335 HU_AutoFlashlightovertakeSet "超车模式自动闪灯设置";
CM_ SG_ 1335 HU_TwiceLockDoorSet "二次落锁设置";
CM_ SG_ 1335 HU_AutoLeaveLockSet "离车自动闭锁设置";
CM_ SG_ 1335 HU_HonkovertakeSet "超车模式自动鸣笛设置";
CM_ SG_ 1335 HU_RearWiperSet "倒档后雨刮自动刮刷设置";
CM_ SG_ 1335 HU_LockAutoClsWinSet "闭锁关窗设置";
CM_ SG_ 1335 HU_MirrorSetStatus "后视镜倒车辅助设置";
CM_ SG_ 1335 HU_AutoSpeedLockSet "行车自动落锁设置";
CM_ SG_ 1335 HU_MirrorAutoFoldSet "后视镜自动折叠设置信号";
CM_ SG_ 1335 HU_SmartUnlockSet "靠近解锁设置";
CM_ SG_ 1335 HU_SmartLockSet "离开闭锁设置";
CM_ SG_ 1335 HU_DriverSeatAdjust "座椅位置调整";
CM_ SG_ 1335 HU_RemoteControlWindowUpSet "遥控升窗设置";
CM_ SG_ 1335 HU_RainCtrlSunRoofSet "雨量感应天窗设置（设置开启关闭）";
CM_ SG_ 1335 HU_Autoturnlightovertakemodeset "超车模式自动转向灯设置";
CM_ SG_ 1335 HU_WelcomeLightMode "迎宾灯光模式";
CM_ SG_ 1335 HU_RainOpenLightSet "雨雾天开灯设置";

CM_ SG_ 1327 HU_ACScenarioReq "空调场景请求信号";
CM_ SG_ 1327 HU_ACComfortAdjustment "空调舒适性调节";
CM_ SG_ 1325 HU_ACControlMode "空调控制模式";
CM_ SG_ 1325 HU_FrontAUTOACOnReq "前排空调自动模式开启请求信号";
CM_ SG_ 1325 HU_FrontACOffReq "前排空调关闭请求信号";
CM_ SG_ 1325 HU_ACDEFAdjustReq "前除霜模式设定请求信号";
CM_ SG_ 1325 HU_ACRDEFAdjustReq "后除霜模式设定请求信号";
CM_ SG_ 1325 HU_IonizerReq "离子发生器控制请求";
CM_ SG_ 1325 HU_CirculationModeReq "循环模式设定请求信号";
CM_ SG_ 1325 HU_MaxDefrost_Switch "Max除雾按键信号";
CM_ SG_ 1325 HU_ACreq "AC设定请求信号";
CM_ SG_ 1325 HU_SyncReq "温区设定请求信号";
CM_ SG_ 1325 HU_VentilationSetEvening "定时通风设定晚上";
CM_ SG_ 1325 HU_VentilationOn "定时通风开启";
CM_ SG_ 1325 HU_ACFanAdjustValueReq "风量设定请求信号";
CM_ SG_ 1325 HU_VentilationSetAfternoon "定时通风设定下午";
CM_ SG_ 1325 HU_VentilationSetMorning "定时通风设定上午";
CM_ SG_ 1325 HU_ACFrontModeAdjustReq "前排出风模式设定请求信号";
CM_ SG_ 1325 HU_AQSReq "AQS开启请求";
CM_ SG_ 1325 HU_MaxACReq "最大制冷开启请求";
CM_ SG_ 1319 HU_DVRBrowseCommand "DVR浏览控制";
CM_ SG_ 1319 HU_ShootControl "拍照请求信号";
CM_ SG_ 1319 HU_TransparentCarSwitch "透明车身开关信号";
CM_ SG_ 1319 HU_AVMCalibrationSwitch "自动标定开关";
CM_ SG_ 1319 HU_MODEnable "MOD移动物体检测使能开关信号";
CM_ SG_ 1319 HU_DVREmergencyRecord "一键紧急录制开关";
CM_ SG_ 1319 HU_VibrationWarningStatus "车辆振动标准值反馈";
CM_ SG_ 1319 HU_DVRVideoPlayUserTime "用户拖动进度条时间";
CM_ SG_ 1319 HU_DVRReplayMode "全景DVR回放模式";
CM_ SG_ 1319 HU_ResolutionSet "DVR分辨率设置信号";
CM_ SG_ 1319 HU_DVRDistortCorrectSwitch "DVR畸变校正开关";
CM_ SG_ 1319 HU_LanguageSet "DVR语言设置信号";
CM_ SG_ 1319 HU_TurnLightAVMSwitch "转向灯触发全景开关信号";
CM_ SG_ 1319 HU_RadarAVMSwitch "雷达触发全景开关信号";
CM_ SG_ 1319 HU_DVRPrintScreen "DVR截图";
CM_ SG_ 1319 HU_DVRReplaySpeed "播放速度控制";
CM_ SG_ 1319 HU_DVREnableSet "DVR使能设置信号";
CM_ SG_ 1319 HU_DVRTapeSet "DVR录音功能设置信号";
CM_ SG_ 1319 HU_DVRVedioSeek "DVR视频+-";
CM_ SG_ 1319 HU_DVRDisplayVision "全景DVR显示视角";
CM_ SG_ 1319 HU_AVMCalibrationConfirm "标定确认";
CM_ SG_ 1319 HU_DVRReplayCommand "视频播放指令";
CM_ SG_ 1319 HU_RecordingcycleSetting "录影循环设置";
CM_ SG_ 1319 HU_DVRFormatReq "DVR格式化请求";
CM_ SG_ 1319 HU_TopLookDownSwitch "自动俯视大图开关";
CM_ SG_ 1311 HU_LightingDoorOpenWarningSet "照明开门预警设置";
CM_ SG_ 1311 HU_LightingBackwardWarningSet "照明倒车提醒设置";
CM_ SG_ 1311 HU_ALCVoiceWakeAssociation "氛围灯语音唤醒关联";
CM_ SG_ 1311 HU_ALCACTemperatureAssociation "氛围灯空调温度关联";
CM_ SG_ 1311 HU_ALCRhythmSet "氛围灯音乐律动设置";
CM_ SG_ 1311 HU_ALCDrivingModeAssociation "氛围灯驾驶模式关联";
CM_ SG_ 1311 HU_RefreshModeEnable "清醒提神模式设置信号";
CM_ SG_ 1311 HU_SceneModeAct "情景模式执行信号";
CM_ SG_ 1311 HU_SenseAQIEnable "感知空气质量使能";
CM_ SG_ 1311 HU_SceneModeReq "情景模式请求信号";
CM_ SG_ 1311 HU_AtmosphereLightColorBarSet "氛围灯颜色条设置";
CM_ SG_ 1306 HU_VoiceWelcometSet "车外语音迎宾设置";
CM_ SG_ 1306 HU_IPNavigationDisplay "仪表导航界面切换显示";
CM_ SG_ 1306 HU_RemoteControlSwtichSet "解闭锁反馈方式设置（灯光+声音，仅灯光、仅声音）";
CM_ SG_ 1306 HU_ShemeColorsSwitchSet "仪表主题设置信号";
CM_ SG_ 1306 HU_ScreenPowerOn "显示屏状态信号";
CM_ SG_ 1306 HU_EPSTorqueModeSet "驾驶模式转向助力设置";
CM_ SG_ 1300 HU_ObstacleSafeDistanceSet "遥控泊车距障碍物停止距离设置";
CM_ SG_ 1300 HU_SlotVoiceSelect "语音选择第几个车位";
CM_ SG_ 1300 HU_TJPEnable "TJP开关";
CM_ SG_ 1300 HU_RemoteDistanceSet "遥控泊车行驶距离设置";
CM_ SG_ 1300 HU_ParkingConfirm "HU确认开始泊车";
CM_ SG_ 1300 HU_Uls_BSD_Activation "超声波变道辅助设置";
CM_ SG_ 1300 HU_FCTBEnable "前侧横向制动开关";
CM_ SG_ 1300 HU_Uls_FKP_Activation "倒车横向预警使能";
CM_ SG_ 1300 HU_ParkingResume "HU确认恢复泊车";
CM_ SG_ 1300 HU_OverspeedWarningEnable "超速预警使能开关";
CM_ SG_ 1300 HU_OverspeedWarningOffset "超速预警偏差设置";
CM_ SG_ 1300 HU_AudioWarningEnable "语音警示开关";
CM_ SG_ 1300 HU_LockCtrlEnable "闭锁保护开关";
CM_ SG_ 1300 HU_IACCEnable "IACC使能开关";
CM_ SG_ 1300 HU_OverspeedSoundWarEnable "超速报警声音提醒开关";
CM_ SG_ 1300 HU_SEAEnable "开门预警开关";
CM_ SG_ 1300 HU_RCTBEnable "后侧横向制动开关";
CM_ SG_ 1300 HU_LDWShakeLev "LAS震动强度";
CM_ SG_ 1300 HU_FatigueDectionEnable "疲劳检测开关";
CM_ SG_ 1300 HU_LASWarningModeSelection "LAS警告方式";
CM_ SG_ 1300 HU_TSRSwitch "交通标志识别使能";
CM_ SG_ 1300 HU_HMAEnable "智能远光功能开启";
CM_ SG_ 1300 HU_RCWEnable "后追尾预警使能";
CM_ SG_ 1300 HU_RCTAEnable "后侧横向预警开关";
CM_ SG_ 1300 HU_FCTAEnable "HU_LdwSensitivity";
CM_ SG_ 1300 HU_LASModeSelection "LAS模式选择信号";
CM_ SG_ 1300 HU_ParkingModeSelect "用户选择泊车模式";
CM_ SG_ 1299 HU_VisionAngleReq "AVM_显示角度";
CM_ SG_ 1299 HU_DVREditSelected "视频/照片选择";
CM_ SG_ 1299 HU_RealTimeReq "DVR实时显示请求";
CM_ SG_ 1299 HU_360AVMdetectionRequest "360全景检测请求";
CM_ SG_ 1299 HU_InterfaceChangeSingnal "界面操作信号";
CM_ SG_ 1299 HU_RebroadcastReq "DVR回放请求";
CM_ SG_ 1299 HU_DVRMode "DVR模式请求";
CM_ SG_ 1299 HU_3DAVMReq "AVM3D请求";
CM_ SG_ 1299 HU_AVMswitch "全景切换开关";
CM_ SG_ 1299 HU_Ylevel "Y坐标";
CM_ SG_ 1299 HU_Xlevel "X坐标";
CM_ SG_ 1293 HU_InstrumentPanel_MiddleALCColourControl "仪表板中控氛围灯颜色控制";
CM_ SG_ 1293 HU_RFDOORALCColourControl "右前门板氛围灯颜色控制";
CM_ SG_ 1293 HU_LFDOORALCColourControl "左前门板氛围灯颜色控制";
CM_ SG_ 1293 HU_InstrumentPanel_RightALCColourControl "仪表板右氛围灯颜色控制";
CM_ SG_ 1293 HU_InstrumentPanel_LeftALCColourControl "仪表板左氛围灯颜色控制";
CM_ SG_ 1293 HU_InstrumentPanel_MiddleALCBrightnessControl "仪表板中控氛围灯亮度控制";
CM_ SG_ 1293 HU_RFDOORALCBrightnessControl "右前门板氛围灯亮度控制";
CM_ SG_ 1293 HU_LFDOORALCBrightnessControl "左前门板氛围灯亮度控制";
CM_ SG_ 1293 HU_InstrumentPanel_RightALCBrightnessControl "仪表板右氛围灯亮度控制";
CM_ SG_ 1293 HU_InstrumentPanel_LeftALCBrightnessControl "仪表板左氛围灯亮度控制";
CM_ SG_ 1293 HU_ALCBreathingCycle "氛围灯呼吸周期";
CM_ SG_ 1293 HU_ALCEnable "氛围灯使能";
CM_ SG_ 1293 HU_ALCswitchset "氛围灯开关设置";
CM_ SG_ 1286 HU_UserSet "用户状态设置";
CM_ SG_ 1286 HU_DriverSeatMemorySet "座椅记忆设置";
CM_ SG_ 1286 HU_SunroofControlReq "语音控制天窗";
CM_ SG_ 1286 HU_ACDriverTempAdjustValueReq "主驾温度设定请求信号";
CM_ SG_ 1286 HU_ACPassengerTempAdjustValueReq "副驾温度设定请求信号";
CM_ SG_ 1286 HU_ACPassengerHeatReq "副驾座椅加热";
CM_ SG_ 1286 HU_ACPassengerVentilateReq "副驾座椅通风";
CM_ SG_ 1286 HU_ACDriverHeatReq "主驾座椅加热";
CM_ SG_ 1286 HU_UserIDReceiveFb "用户ID收到反馈";
CM_ SG_ 1286 HU_ACDriverVentilateReq "主驾座椅通风";
CM_ SG_ 1281 HU_LocalTimeYear "本地时间年";
CM_ SG_ 1281 HU_LocalTimeSecond "本地时间秒";
CM_ SG_ 1281 HU_LocalTimeSystem "本地时间制式";
CM_ SG_ 1281 HU_LocalTimeMinute "本地时间分";
CM_ SG_ 1281 HU_LocalTimeHour "本地时间时";
CM_ SG_ 1281 HU_AirHumidityValid "空气湿度信号有效";
CM_ SG_ 1281 HU_LocalTimeDate "本地时间日";
CM_ SG_ 1281 HU_LocalTimeMonth "本地时间月";
CM_ SG_ 1281 HU_LocalTimeValid "本地时间有效位";
CM_ SG_ 1281 HU_AirHumidity "当前位置的空气湿度信号";
CM_ SG_ 1280 HU_CurrentLocationLatitude "当前位置纬度";
CM_ SG_ 1280 HU_CurrentLocationLongitude "当前位置经度";
CM_ SG_ 1280 HU_CurrentLocationValid "当前位置信息有效";
CM_ SG_ 974 HU_NavTimeRemainingHours "导航剩余小时数";
CM_ SG_ 974 HU_NavTimeRemainingMinutes "导航剩余分钟数";
CM_ SG_ 974 HU_NavTimeRemainingDays "导航剩余天数";
CM_ SG_ 974 HU_NavTotalMileageRemaining "导航剩余总里程";
CM_ SG_ 974 HU_FinishDistancePercent "导航已行驶里程百分比";
CM_ SG_ 962 HU_TollDis "当前位置与收费站距离";
CM_ SG_ 962 HU_TollInfo "收费站信息";
CM_ SG_ 962 HU_FallingRockInfo "前方落石信息";
CM_ SG_ 962 HU_LaneCnt "车道数量";
CM_ SG_ 962 HU_RampSide "匝道位置";
CM_ SG_ 955 HU_SpeedLimitDistance "当前位置与限速点距离";
CM_ SG_ 952 HU_CRCCheck_3B8 "HU_3B8校验和";
CM_ SG_ 952 HU_RollingCounter_3B8 "HU_3B8计数器";
CM_ SG_ 952 HU_NavGuiganceStatus "导航路径引导状态";
CM_ SG_ 952 HU_TunnelLength "隧道长度";
CM_ SG_ 952 HU_Byroad "车辆与隧道间岔路信号";
CM_ SG_ 952 HU_TunnelDistance "当前位置与隧道距离";
CM_ SG_ 952 HU_EnterTunnelInfo "隧道信息";
CM_ SG_ 943 HU_CRCCheck_3AF "HU_3AF校验和";
CM_ SG_ 943 HU_RollingCounter_3AF "HU_3AF计数器";
CM_ SG_ 943 HU_StartupStatus "DVD启动状态";
CM_ SG_ 943 HU_Power_OnOff_Req "整车上下电请求";
CM_ SG_ 943 HU_RampDistance "当前位置与匝道距离";
CM_ SG_ 943 HU_CurveDistance "HU蜂鸣报警状态";
CM_ SG_ 943 HU_NavSpeedLimitType "限速类型";
CM_ SG_ 943 HU_NavCurrentRoadType "道路类型";
CM_ SG_ 943 HU_EnterCurveInfo "弯道信息";
CM_ SG_ 943 HU_NavStatus "导航状态";
CM_ SG_ 943 HU_RampInfo "匝道信息";
CM_ SG_ 943 HU_NavSpeedLimitStatus "限速状态";
CM_ SG_ 943 HU_NavSpeedLimitUnits "单位";
CM_ SG_ 943 HU_EnterRampInfo "进出匝道";
CM_ SG_ 943 HU_NavSpeedLimit "限速值";
CM_ SG_ 943 HU_NavCountryCode "国家代码";
CM_ SG_ 939 HU_HornStatus "电喇叭工作状态";
CM_ SG_ 939 HU_ExhaustValEnable "排气声浪使能信号";
CM_ SG_ 939 HU_BackDoorSwitch "尾门开关";
CM_ SG_ 939 HU_SetDoorLight "Door挡开关";
CM_ SG_ 939 HU_SetAFS "大灯自适应调节开关";
CM_ SG_ 939 HU_EPSModeSet "转向助力模式设置";
CM_ SG_ 939 HU_STTEnable "STT使能信号";
CM_ SG_ 939 HU_AVHStatusSetReq "AVH功能状态设置";
CM_ SG_ 939 HU_ESPStatusSetReq "ESP功能状态设置";
CM_ SG_ 939 HU_HDCStatusSetReq "HDC功能状态设置";
CM_ SG_ 910 HU_APAModeSelect "APA模式选择";
CM_ SG_ 910 HU_CrossParkingModeSet "垂直泊车进入模式设置";
CM_ SG_ 910 HU_ASPSwitch "ASP开关";
CM_ SG_ 910 HU_ASPModeSelect "ASP模式选择";
CM_ SG_ 910 HU_EXT_RemoteDetectUploadStatus "车外远程监控上传状态";
CM_ SG_ 910 HU_PACModeSelect "泊车轨迹模式";
CM_ SG_ 910 HU_ASPRemindEnable "ASP主动提示使能";
CM_ SG_ 910 HU_LanguageSync "语言同步";
CM_ SG_ 910 HU_SlotUserSelected "用户选择的车位";
CM_ SG_ 910 HU_LAEBEnable "LAEB使能";
CM_ SG_ 910 HU_APAActive "语音控制APA开启";
CM_ SG_ 840 HU_FollowTargetDisplay_Set "跟随目标显示设置";
CM_ SG_ 840 HU_HUDBiasLightSet "HUD背景光设置";
CM_ SG_ 840 HU_HUDOnOffReq "HUD开关请求";
CM_ SG_ 840 CallingStatus "通话状态";
CM_ SG_ 840 HU_HUDRearIncomingVehicleSet "后方来车提醒设置";
CM_ SG_ 840 HU_HUDMovingTargetDetect_Set "移动目标检测设置";
CM_ SG_ 840 HU_NaviDistance "导航路口距离";
CM_ SG_ 840 HU_DVRSystemImprint "系统版本信息查询";
CM_ SG_ 840 HU_DVRErrorRecord "故障信息显示";
CM_ SG_ 840 HU_BcallReq "一键呼请求";
CM_ SG_ 840 HU_SurrondingMonitorDone "周边影像监控反馈";
CM_ SG_ 840 HU_RegisterStatus "注册状态";
CM_ SG_ 840 HU_TUIDReq "TUID请求";
CM_ SG_ 840 HU_Seeoffanimation "送宾动画信号";
CM_ SG_ 840 HU_SDCapacity "容量查询";
CM_ SG_ 840 HU_AutoViewSet "自动后视设置";
CM_ SG_ 840 HU_NaviIconNumber "导航标识编码";
CM_ SG_ 763 HU_UltravioletRadiatorControlCommand "语音控制紫外线灯信号";
CM_ SG_ 763 HU_WindowControlCommand "语音控制车窗信号";
CM_ SG_ 763 HU_HighBeamLampReq "语音控制远光灯信号";
CM_ SG_ 763 HU_LowBeamLampReq "语音控制近光灯信号";
CM_ SG_ 763 HU_PositionLampReq "语音控制位置灯信号";
CM_ SG_ 763 HU_AutoLightReq "语音控制自动灯光信号";
CM_ SG_ 763 HU_WiperSpReq "语音控制雨刮信号";
CM_ SG_ 763 HU_R_WiperReq "语音控制后雨刮信号";
CM_ SG_ 763 HU_PLG_Remote_commandReq "语音控制后背门信号";
CM_ SG_ 763 HU_LockUnlockControlSignal "语音控制解闭锁信号";
CM_ SG_ 763 HU_FollowMeHomeReq "语音控制跟随回家信号";
CM_ SG_ 729 LAS_VoiceWarning "声音报警";
CM_ SG_ 729 LAS_CRCCheck_30A "LAS_30A校验和";
CM_ SG_ 729 LAS_RollingCounter_30A "LAS_30A计数器";
CM_ SG_ 729 LAS_LLaneMarkerType "左侧车道线类型";
CM_ SG_ 729 LAS_HostLaneLeftStatus "本车道左侧车道线状态";
CM_ SG_ 729 LAS_HostLaneRightStatus "本车道右侧车道线状态";
CM_ SG_ 729 LAS_LASWarningModeSelectionSts "LAS警告方式状态";
CM_ SG_ 729 LAS_LDWShakeLevStatus "LDW震动强度状态";
CM_ SG_ 729 LAS_LASModeSelectionStatus "LAS模式选择信号状态";
CM_ SG_ 729 LAS_RLaneMarkerType "右侧车道线类型";
CM_ SG_ 728 LAS_CRCCheck_24E "LAS_24E校验和";
CM_ SG_ 728 LAS_RollingCounter_24E "LAS_24E计数器";
CM_ SG_ 728 LAS_LASModeSelectionFeedback "LAS模式选择反馈信号";
CM_ SG_ 728 LAS_LASFailure "系统故障报警";
CM_ SG_ 728 LAS_LDWStatus "LDW状态";
CM_ SG_ 728 LDW_VibrationWarning "振动报警请求";
CM_ SG_ 727 HU_ScreenOperateStatus "屏幕操作状态信号";
CM_ SG_ 727 HU_3DHorAngleReq "3D视图水平角度请求";
CM_ SG_ 1600 IP_ACCInterfaceDisplaySts "仪表ACC界面显示";
CM_ SG_ 1600 IP_ImformationTransmissionStatus "信息传输状态";
CM_ SG_ 1600 IP_ShemeColorsSwitchStatus "仪表主题状态信号";
CM_ SG_ 1600 IP_NightBiasLightStatus "黑夜背景光状态信号";
CM_ SG_ 1600 IP_DayBiasLightStatus "白天背景光状态信号";
CM_ SG_ 1600 IP_HUBuzzerWarning "蜂鸣报警信号";
CM_ SG_ 1328 IP_AfeAfterIgnOn "启动后的平均油耗";
CM_ SG_ 1328 IP_AllAvgFuelConsumption "平均油耗信号";
CM_ SG_ 1328 IP_FuelGageType "燃油表种类";
CM_ SG_ 1328 IP_FuelLevel "燃油表指示状态信号";
CM_ SG_ 1328 IP_TotalOdometer "总里程信号";
CM_ SG_ 1328 IP_EngineOffTime "发动机停机时间";
CM_ SG_ 1326 IP_HUConnection_acknowledge "仪表车机连接响应";
CM_ SG_ 1326 IP_ImformationTransmission_Request "信息传输请求";
CM_ SG_ 1326 IP_IndirectTPMSReset "间接式胎压监测系统复位请求";
CM_ SG_ 1326 IP_SunroofControlReq "天窗控制命令";
CM_ SG_ 1303 IP_DisAddByBRS "48v节油增加里程";
CM_ SG_ 1290 IP_FuelLevelPercent "油量百分比";
CM_ SG_ 1290 IP_DTE "余油可行驶里程";
CM_ SG_ 1290 IP_DisAfterIgnOn "启动后的行驶里程";
CM_ SG_ 1290 IP_FuelLeftoverVD "油量信息有效";
CM_ SG_ 1290 IP_FuelLeftover_AD "实时油量信息";
CM_ SG_ 1290 IP_FuelLeftover "油量信息";
CM_ SG_ 901 IP_VehicleSpeedIndicatorOutput "车速信号指示输出";
CM_ SG_ 901 IP_FuelLow "燃油低信号";
CM_ SG_ 901 IP_EngineOilPressureLowSts "机油压力状态";
CM_ SG_ 901 IP_EngineCoolanTemperatureHigh "水温高状态信号";
CM_ SG_ 901 IP_WelcomeSoundSetStatus "迎宾声音设置状态";
CM_ SG_ 901 IP_ECnsAvgReset "平均能耗重置";
CM_ SG_ 901 IP_BrakeFluidState "制动液状态";
CM_ SG_ 901 IP_AlarmSoundStatus "仪表报警状态是否需要主机降音";
CM_ SG_ 901 IP_SoundStyleSetStatus "仪表声音类型反馈状态";
CM_ SG_ 901 IP_DimmingModeSetStatus "仪表亮度调节模式设置反馈";
CM_ SG_ 901 IP_Adaptivedimminglevel "自适应调光亮度等级";
CM_ SG_ 901 IP_AlarmSoundSetStatus "报警声音设置状态";
CM_ SG_ 901 IP_WarningVolumeSettingFB "仪表提示音量设置反馈";
CM_ SG_ 901 IP_RearSeatbeltWarningEnableFB "后排安全带未系报警使能反馈";
CM_ SG_ 901 IP_MaintainReset "保养信息重置";
CM_ SG_ 901 IP_DimmingSetStatus "仪表亮度设置反馈";
CM_ SG_ 901 IP_MessageAlertSoundSetStatus "信息提示声音设置状态";
CM_ SG_ 734 IP_CRCCheck_2DE "IP_2DE校验和";
CM_ SG_ 734 IP_RollingCounter_2DE "IP_2DE计数器";
CM_ SG_ 734 IP_FuelLeftover "油量信息";
CM_ SG_ 734 IP_Odometer "小计里程，需要手动清零";
CM_ SG_ 734 IP_QDashACCFail "仪表检测到ACC发出的信息有误（例如timeout）";
CM_ SG_ 734 IP_DISFail "仪表故障";
CM_ SG_ 734 IP_PassengerLCDALEDSts "乘员侧警告灯状态";
CM_ SG_ 734 IP_DriverLCDALEDSts "驾驶侧警告灯状态";
CM_ SG_ 1662 AC_DTC2_Status "AC的DTC2状态";
CM_ SG_ 1662 AC_DTC2_LowByte "AC的DTC2低字节";
CM_ SG_ 1662 AC_DTC2_MiddByte "AC的DTC2中字节";
CM_ SG_ 1662 AC_DTC2_HighByte "AC的DTC2高字节";
CM_ SG_ 1662 AC_DTC1_Status "AC的DTC1状态";
CM_ SG_ 1662 AC_DTC1_LowByte "AC的DTC1低字节";
CM_ SG_ 1662 AC_DTC1_MiddByte "AC的DTC1中字节";
CM_ SG_ 1662 AC_DTC1_HighByte "AC的DTC1高字节";
CM_ SG_ 650 IP_VoicePlay_CycleReq "音源播放周期";
CM_ SG_ 650 IP_RRReq "右后方位请求信号";
CM_ SG_ 650 IP_VoicePlayIntervalReq "音源播放间隔";
CM_ SG_ 650 IP_LRReq "左后方位请求信号";
CM_ SG_ 650 IP_TypeOfCutSoundShort "音源打断类型";
CM_ SG_ 650 IP_SeatBeltWarningReq "安全带未系声音请求提示信号";
CM_ SG_ 650 IP_TurnWarningReq "转向声音请求提示信号";
CM_ SG_ 650 IP_RadarWarningReq "雷达声音请求提示信号";
CM_ SG_ 650 IP_RFReq "右前方位请求信号";
CM_ SG_ 650 IP_MsgWarningReq "信息提示音请求信号";
CM_ SG_ 650 IP_VoicePlayTimesReq "音源播放次数";
CM_ SG_ 650 IP_HandBrakeSwitch "手刹开关状态信号";
CM_ SG_ 650 IP_LFReq "左前方位请求信号";
CM_ SG_ 650 IP_VoiceReq "警示类声音请求提示信号";
CM_ SG_ 1297 AC_EnvironmentalTempSensorDiagnosis "车外温度传感器诊断信号";
CM_ SG_ 1297 AC_ThreeStateSwitchDiagnosis "三态压力开关诊断信号";
CM_ SG_ 1297 AC_CarInTempSensorDiagnosis "车内温度传感器诊断信号";
CM_ SG_ 1297 AC_LightSensorDiagnosis "光照传感器诊断信号";
CM_ SG_ 1297 AC_EvaporatorSurfaceTemp_Reserve "蒸发器表面温度信号";
CM_ SG_ 1297 AC_Actual_pre_blow_mode "实际前吹风模式";
CM_ SG_ 1296 AC_PM25OutCar "车外PM2.5浓度";
CM_ SG_ 1296 AC_AirQualityInCarLevel "车内空气质量等级";
CM_ SG_ 1296 AC_PM25InCarValid "车内PM2.5浓度有效";
CM_ SG_ 1296 AC_CO2Density "车内CO2浓度";
CM_ SG_ 1296 AC_PM25InCar "车内PM2.5浓度";
CM_ SG_ 1296 AC_InternalTemp "车内温度信号";
CM_ SG_ 923 AC_EnvironmentalTemp_RAW "原始车外温度信号";
CM_ SG_ 923 AC_RrpanelLock_St "后排空调锁状态";
CM_ SG_ 923 AC_RearSt "后空调状态";
CM_ SG_ 923 AC_PlasmaSt "等离子发生器状态";
CM_ SG_ 923 AC_AQSSt "AQS状态";
CM_ SG_ 923 AC_ACEcoSt "压缩机ECO状态";
CM_ SG_ 923 AC_RecycleType "内外循环模式";
CM_ SG_ 923 AC_VentilationOnMode "定时通风开启模式";
CM_ SG_ 923 AC_ClimateDisplayReq "空调显示请求";
CM_ SG_ 923 AC_TunnelAutoRecycleWork "隧道内循环工作状态";
CM_ SG_ 923 AC_PaReqTemp "副驾驶侧温度调节_自动";
CM_ SG_ 923 AC_RearReqTemp "后排温度调节_自动";
CM_ SG_ 923 AC_RemoteStartFeedback "空调远程启动反馈";
CM_ SG_ 923 AC_DriverReqTemp "驾驶员温度调节_自动";
CM_ SG_ 923 AC_RearAutoSts "后排自动模式状态显示";
CM_ SG_ 923 AC_RrBlowType "后吹风模式";
CM_ SG_ 923 AC_AutoWorkStatus "自动空调温区切换显示";
CM_ SG_ 923 AC_FrAutoSts "前排自动手动切换显示";
CM_ SG_ 923 AC_ACSt "压缩机状态显示";
CM_ SG_ 870 AC_AC_ReqValid "A/C请求有效";
CM_ SG_ 870 AC_AC_Req "A/C请求信号";
CM_ SG_ 870 AC_SolenoidCurrent "电磁阀电流";
CM_ SG_ 870 AC_ACPre "冷媒压力";
CM_ SG_ 870 AC_EnvironmentalTemp "车外温度信号";
CM_ SG_ 870 AC_PTCStatus "PTC状态信号";
CM_ SG_ 870 AC_FrReqWindLevel "前排风量调节";
CM_ SG_ 870 AC_PressureSwitch "压力开关状态";
CM_ SG_ 870 AC_CompressorStatus "压缩机状态";
CM_ SG_ 848 AC_RefreshModeEnableSts "清醒提神模式使能状态反馈";
CM_ SG_ 848 AC_ACSceneMode_FeedBack "空调情景模式反馈信号";
CM_ SG_ 848 AC_ComFort_FeedBack "车内温度达到舒适事件反馈";
CM_ SG_ 848 AC_ScenarioSts "空调场景状态信号";
CM_ SG_ 848 AC_FanComFort_ModeSts "空调风量舒适模式状态";
CM_ SG_ 848 AC_AutomaticdeFoggingStatus "自动除雾状态信号";
CM_ SG_ 848 AC_RemoteAirPurificatio_Feedback "远程空气净化请求反馈";
CM_ SG_ 848 AC_Remotedefronstingfeedback "远程除霜请求反馈";
CM_ SG_ 848 AC_Intelligentdetectionofspecialeventsignals "智能检测特殊事件信号";
CM_ SG_ 832 AC_Rmote_Hot_Feedback "远程空调制热反馈";
CM_ SG_ 832 AC_Rmote_Cool_Feedback "远程空调制冷反馈";
CM_ SG_ 832 AC_ACOnOff "空调工作状态";
CM_ SG_ 832 AC_DrAirMergePortOpeningRatioVD "驾驶侧冷暖/混合风门开度有效";
CM_ SG_ 832 AC_DrAirMergePortOpeningRatio "驾驶侧冷暖/混合风门开度";
CM_ SG_ 832 AC_RrReqWindLevelVD "后鼓风机风量调节有效";
CM_ SG_ 832 AC_RrAirMergePortOpeningRatio "后冷暖/混合风门开度";
CM_ SG_ 832 AC_RrReqWindLevel "后鼓风机风量调节";
CM_ SG_ 832 AC_PrAirMergePortOpeningRatio "乘员侧冷暖/混合风门开度";
CM_ SG_ 832 AC_FrBlowType "前吹风模式";
CM_ SG_ 816 AC_AutoDeFoggingStatus "自动除雾设置状态";
CM_ SG_ 816 AC_TunnelAutoRecycleStatus "隧道内循环设置状态";
CM_ SG_ 816 AC_BlueTooth_Reduce_WindSpeedSetStatus "蓝牙通话降风速设置状态信号";
CM_ SG_ 816 AC_ReserveGearAutoRecycleStatus "倒车自动内循环设置状态";
CM_ SG_ 816 AC_PanelTouchConcussFB "触摸面板震动强度反馈";
CM_ SG_ 816 AC_AutowindSet1Status "钥匙开锁通风设置状态";
CM_ SG_ 816 AC_AutowindSet2Status "钥匙长按通风设置状态";
CM_ SG_ 816 AC_AutowindSet3Status "空调自干燥设置状态(钥匙闭锁通风设置状态)";
CM_ SG_ 816 AC_FanComfort_ModeSts "空调风量舒适模式状态";
CM_ SG_ 816 AC_MaxAC_Status "最大制冷状态";
CM_ SG_ 816 AC_TouchCtrsoundReq "触屏控制声音请求";
CM_ SG_ 816 AC_ACType "AC类型";
CM_ SG_ 816 AC_MaxDefrostIndicator "MAX除霜指示";
CM_ SG_ 816 AC_Sleep "AC待机信号";
CM_ SG_ 816 AC_FrontDefrosterSwitch "前除霜信号";
CM_ SG_ 816 AC_SystemFailureFlag "AC系统故障";
CM_ SG_ 769 FP_ACDriverTempAdjustValueReq "主驾温度设定请求信号";
CM_ SG_ 769 FP_AVHStatusSetReq "AVH功能状态设置";
CM_ SG_ 769 FP_MaxDefrost_Switch "MAX除霜开关";
CM_ SG_ 769 AC_HardwireDriveModeChange "驾驶模式硬开关切换";
CM_ SG_ 769 FP_Temp_Dec_Switch "温度减信号";
CM_ SG_ 769 FP_Temp_Inc_Switch "温度加信号";
CM_ SG_ 769 FP_Fan_dec_Swich "风量减信号";
CM_ SG_ 769 FP_Fan_Inc_Swich "风量加信号";
CM_ SG_ 769 FP_MaxAC_Switch "MaxAC按键信号";
CM_ SG_ 769 FP_OFF "空调OFF按键";
CM_ SG_ 769 FP_AirFlowMode_CW "吹风模式顺时针切换";
CM_ SG_ 769 FP_CyclingMode "内外循环按键";
CM_ SG_ 769 FP_TempLongPress_Botton "温度按键长按信号";
CM_ SG_ 769 FP_FanLongPress_Botton "风量按键长按信号";
CM_ SG_ 769 FP_Front_AUTO_Switch "前排空调自动模式开关";
CM_ SG_ 769 FP_AC_Swtich "AC按键信号";
CM_ SG_ 769 FP_Front_Defrost_Switch "前除霜开关";
CM_ SG_ 769 FP_RearDefrosterSwitch "后除霜开关";
BA_DEF_ BO_  "GenMsgILSupport" ENUM  "No","Yes";
BA_DEF_ SG_  "GenSigSendType" ENUM  "Cyclic","OnWrite","OnWriteWithRepetition","OnChange","OnChangeWithRepetition","NotUsed","NotUsed","NoSigSendType";

BA_DEF_ SG_  "GenSigEnvVarType" ENUM  "int","float","undef";
BA_DEF_ BO_ "NmMessage" ENUM "No","Yes";
BA_DEF_ BO_  "GenMsgCycleTime" INT 0 65535;
BA_DEF_ BO_  "GenMsgSendType" ENUM  "cyclic","event","spontaneous","cyclicIOnEvent","spontaneousWithDelay","cyclicAndEvent","cyclicAndSpontaneousWithDelay","spontaneousWithRepetition","cyclicIfActiveAndSpontaneousWD","FixedPeriodic";
BA_DEF_DEF_  "GenMsgILSupport" "Yes";
BA_DEF_DEF_  "GenSigSendType" "Cyclic";
BA_DEF_DEF_ "NmMessage" "Yes";

BA_DEF_DEF_  "GenSigEnvVarType" "undef";
BA_DEF_DEF_  "GenMsgCycleTime" 2;
BA_DEF_DEF_  "GenMsgSendType" "cyclic";
BA_ "GenMsgCycleTime" BO_ 1568 100;
BA_ "GenMsgCycleTime" BO_ 773 100;
BA_ "GenMsgCycleTime" BO_ 604 1000;
BA_ "GenMsgCycleTime" BO_ 613 100;
BA_ "GenMsgCycleTime" BO_ 651 40;
BA_ "GenMsgCycleTime" BO_ 610 40;
BA_ "GenMsgCycleTime" BO_ 1606 100;
BA_ "GenMsgCycleTime" BO_ 1605 100;
BA_ "GenMsgCycleTime" BO_ 935 100;
BA_ "GenMsgCycleTime" BO_ 854 100;
BA_ "GenMsgCycleTime" BO_ 1554 100;
BA_ "GenMsgCycleTime" BO_ 941 100;
BA_ "GenMsgCycleTime" BO_ 992 50;
BA_ "GenMsgCycleTime" BO_ 1365 0;
BA_ "GenMsgCycleTime" BO_ 1343 0;
BA_ "GenMsgCycleTime" BO_ 719 0;
BA_ "GenMsgCycleTime" BO_ 909 100;
BA_ "GenMsgCycleTime" BO_ 908 100;
BA_ "GenMsgCycleTime" BO_ 623 100;
BA_ "GenMsgCycleTime" BO_ 622 100;
BA_ "GenMsgCycleTime" BO_ 652 40;
BA_ "GenMsgCycleTime" BO_ 1598 200;
BA_ "GenMsgCycleTime" BO_ 1550 200;
BA_ "GenMsgCycleTime" BO_ 1546 0;
BA_ "GenMsgCycleTime" BO_ 1549 0;
BA_ "GenMsgCycleTime" BO_ 1552 100;
BA_ "GenMsgCycleTime" BO_ 1537 0;
BA_ "GenMsgCycleTime" BO_ 1405 0;
BA_ "GenMsgCycleTime" BO_ 1370 200;
BA_ "GenMsgCycleTime" BO_ 1363 0;
BA_ "GenMsgCycleTime" BO_ 1362 0;
BA_ "GenMsgCycleTime" BO_ 1341 100;
BA_ "GenMsgCycleTime" BO_ 1338 0;
BA_ "GenMsgCycleTime" BO_ 1335 0;
BA_ "GenMsgCycleTime" BO_ 1327 100;
BA_ "GenMsgCycleTime" BO_ 1325 100;
BA_ "GenMsgCycleTime" BO_ 1319 0;
BA_ "GenMsgCycleTime" BO_ 1311 40;
BA_ "GenMsgCycleTime" BO_ 1306 100;
BA_ "GenMsgCycleTime" BO_ 1300 0;
BA_ "GenMsgCycleTime" BO_ 1299 100;
BA_ "GenMsgCycleTime" BO_ 1293 20;
BA_ "GenMsgCycleTime" BO_ 1286 100;
BA_ "GenMsgCycleTime" BO_ 1281 1000;
BA_ "GenMsgCycleTime" BO_ 1280 1000;
BA_ "GenMsgCycleTime" BO_ 962 100;
BA_ "GenMsgCycleTime" BO_ 955 100;
BA_ "GenMsgCycleTime" BO_ 952 100;
BA_ "GenMsgCycleTime" BO_ 943 100;
BA_ "GenMsgCycleTime" BO_ 939 100;
BA_ "GenMsgCycleTime" BO_ 910 100;
BA_ "GenMsgCycleTime" BO_ 840 100;
BA_ "GenMsgCycleTime" BO_ 763 0;
BA_ "GenMsgCycleTime" BO_ 729 100;
BA_ "GenMsgCycleTime" BO_ 728 100;
BA_ "GenMsgCycleTime" BO_ 727 50;
BA_ "GenMsgCycleTime" BO_ 1328 500;
BA_ "GenMsgCycleTime" BO_ 1290 100;
BA_ "GenMsgCycleTime" BO_ 901 100;
BA_ "GenMsgCycleTime" BO_ 734 50;
BA_ "GenMsgCycleTime" BO_ 1662 500;
BA_ "GenMsgCycleTime" BO_ 1297 1000;
BA_ "GenMsgCycleTime" BO_ 1296 1000;
BA_ "GenMsgCycleTime" BO_ 923 100;
BA_ "GenMsgCycleTime" BO_ 870 100;
BA_ "GenMsgCycleTime" BO_ 848 100;
BA_ "GenMsgCycleTime" BO_ 832 100;
BA_ "GenMsgCycleTime" BO_ 816 100;
BA_ "GenMsgCycleTime" BO_ 769 100;
BA_ "GenMsgCycleTime" BO_ 916 100;

BA_ "NmMessage" BO_ 1568 0;
BA_ "NmMessage" BO_ 773 0;
BA_ "NmMessage" BO_ 604 0;
BA_ "NmMessage" BO_ 613 0;
BA_ "NmMessage" BO_ 651 0;
BA_ "NmMessage" BO_ 610 0;
BA_ "NmMessage" BO_ 1606 0;
BA_ "NmMessage" BO_ 1605 0;
BA_ "NmMessage" BO_ 935 0;
BA_ "NmMessage" BO_ 854 0;
BA_ "NmMessage" BO_ 1554 0;
BA_ "NmMessage" BO_ 941 0;
BA_ "NmMessage" BO_ 992 0;
BA_ "NmMessage" BO_ 1365 0;
BA_ "NmMessage" BO_ 1343 0;
BA_ "NmMessage" BO_ 719 0;
BA_ "NmMessage" BO_ 909 0;
BA_ "NmMessage" BO_ 908 0;
BA_ "NmMessage" BO_ 623 0;
BA_ "NmMessage" BO_ 622 0;
BA_ "NmMessage" BO_ 652 0;
BA_ "NmMessage" BO_ 1598 0;
BA_ "NmMessage" BO_ 1550 0;
BA_ "NmMessage" BO_ 1546 0;
BA_ "NmMessage" BO_ 1549 0;
BA_ "NmMessage" BO_ 1552 0;
BA_ "NmMessage" BO_ 1537 0;
BA_ "NmMessage" BO_ 1405 0;
BA_ "NmMessage" BO_ 1370 0;
BA_ "NmMessage" BO_ 1363 0;
BA_ "NmMessage" BO_ 1362 0;
BA_ "NmMessage" BO_ 1341 0;
BA_ "NmMessage" BO_ 1338 0;
BA_ "NmMessage" BO_ 1335 0;
BA_ "NmMessage" BO_ 1327 0;
BA_ "NmMessage" BO_ 1325 0;
BA_ "NmMessage" BO_ 1319 0;
BA_ "NmMessage" BO_ 1311 0;
BA_ "NmMessage" BO_ 1306 0;
BA_ "NmMessage" BO_ 1300 0;
BA_ "NmMessage" BO_ 1299 0;
BA_ "NmMessage" BO_ 1293 0;
BA_ "NmMessage" BO_ 1286 0;
BA_ "NmMessage" BO_ 1281 0;
BA_ "NmMessage" BO_ 1280 0;
BA_ "NmMessage" BO_ 962 0;
BA_ "NmMessage" BO_ 955 0;
BA_ "NmMessage" BO_ 952 0;
BA_ "NmMessage" BO_ 943 0;
BA_ "NmMessage" BO_ 939 0;
BA_ "NmMessage" BO_ 910 0;
BA_ "NmMessage" BO_ 840 0;
BA_ "NmMessage" BO_ 763 0;
BA_ "NmMessage" BO_ 729 0;
BA_ "NmMessage" BO_ 728 0;
BA_ "NmMessage" BO_ 727 0;
BA_ "NmMessage" BO_ 1328 0;
BA_ "NmMessage" BO_ 1290 0;
BA_ "NmMessage" BO_ 901 0;
BA_ "NmMessage" BO_ 734 0;
BA_ "NmMessage" BO_ 1662 0;
BA_ "NmMessage" BO_ 1297 0;
BA_ "NmMessage" BO_ 1296 0;
BA_ "NmMessage" BO_ 923 0;
BA_ "NmMessage" BO_ 870 0;
BA_ "NmMessage" BO_ 848 0;
BA_ "NmMessage" BO_ 832 0;
BA_ "NmMessage" BO_ 816 0;
BA_ "NmMessage" BO_ 769 0;
BA_ "NmMessage" BO_ 916 0;
BA_ "GenMsgSendType" BO_ 1365 1;
BA_ "GenMsgSendType" BO_ 1343 1;
BA_ "GenMsgSendType" BO_ 719 1;
BA_ "GenMsgSendType" BO_ 1546 1;
BA_ "GenMsgSendType" BO_ 1549 1;
BA_ "GenMsgSendType" BO_ 1537 1;
BA_ "GenMsgSendType" BO_ 1405 1;
BA_ "GenMsgSendType" BO_ 1363 1;
BA_ "GenMsgSendType" BO_ 1362 1;
BA_ "GenMsgSendType" BO_ 1338 1;
BA_ "GenMsgSendType" BO_ 1335 1;
BA_ "GenMsgSendType" BO_ 1319 1;
BA_ "GenMsgSendType" BO_ 1300 1;
BA_ "GenMsgSendType" BO_ 763 1;

BA_ "GenMsgCycleTime" BO_ 1352 100;
BA_ "GenMsgCycleTime" BO_ 924 100;
BA_ "GenMsgCycleTime" BO_ 866 100;
BA_ "GenMsgCycleTime" BO_ 706 100;
BA_ "GenMsgCycleTime" BO_ 459 100;
BA_ "GenMsgCycleTime" BO_ 977 100;
BA_ "GenMsgCycleTime" BO_ 913 100;
BA_ "GenMsgCycleTime" BO_ 916 100;
BA_ "GenMsgCycleTime" BO_ 1016 100;
BA_ "GenMsgCycleTime" BO_ 852 100;
BA_ "GenMsgCycleTime" BO_ 773 100;
BA_ "NmMessage" BO_ 1352 0;
BA_ "NmMessage" BO_ 924 0;
BA_ "NmMessage" BO_ 866 0;
BA_ "NmMessage" BO_ 706 0;
BA_ "NmMessage" BO_ 459 0;
BA_ "NmMessage" BO_ 977 0;
BA_ "NmMessage" BO_ 913 0;
BA_ "NmMessage" BO_ 916 0;
BA_ "NmMessage" BO_ 1016 0;
BA_ "NmMessage" BO_ 852 0;
BA_ "NmMessage" BO_ 773 0;

VAL_ 773 ETC_Packing_Information 0 "Inactive " 1 "停车场进口 " 2 "停车场出口 " 3 "Reserve " ;
VAL_ 773 ETC_Highway_information 0 "Inactive " 1 "收费站进口 " 2 "收费站出口 " 3 "高速路中 " ;
VAL_ 773 ETC_FaultStatus 0 "Inactive " 1 "无故障 " 2 "故障 " 3 "Reserved " ;
VAL_ 773 ETC_ActiveStatus 0 "Inactive " 1 "未激活 " 2 "激活 " 3 "Reserved " ;
VAL_ 613 APA_ParkNotice_4 0 "IDLE " 1 "'SearchSlot " 2 "Stopthecar " 3 "ParkingModeselection " 4 "Fastenseatbeltsfordriverparkin " 5 "Closethedoorparkin " 6 "NoStandstillBrakeparkin " 7 "PMOchoseELSautomode " 8 "BrakeandLongButton " 9 "ReleBraPark " 10 "Parkingin " 11 "ParkinsuspendACCpedalpressed " 12 "ParkinsuspendHandleGearshift " 13 "parkinsuspendDriverseatbeltunfastened " 14 "ParkinsuspendDooropen " 15 "ParkinsuspendEPBON " 16 "Parkinsuspendresume " 17 "Parkingsystemerror " 18 "SuccessfulParkin " 19 "PMOslottoobig " 20 "PMOslottoosmall " 21 "PMOsideselection " 22 "PMOsuspendHandleGearShift " 23 "Fastenseatbeltsparkout " 24 "Closethedoorparkout " 25 "PMOchoseELSautomode " 26 "FP4Ubuttonlongpressedandbrakingcheck " 27 "StartPMOReleaseBrake " 28 "Parkingout " 29 "PMOsuspendACCpadelpressed " 30 "PMOsuspendGearchange " 31 "PMOsuspenddriverseatbeltunfastened " 32 "PMOsuspenddooropen " 33 "PMOsuspendEPBON " 34 "Parkoutresume " 35 "Parkingcanceled " 36 "Parkoffspeedtoofast " 37 "successfulPMO " 38 "Speedtoohighpleaseslowdown " 39 "Slotsearchoffspeedtoohigh " 40 "RemoteParkingactive " 41 "forwardremoteparking " 42 "backwardremoteparking " 43 "remoteParkingfinish " 48 "SpeedtoohighParkingQuit " 49 "stop " 50 "GearR " 51 "GearD " 52 "Slopetoohighfunctioncancel " 53 "vehiclenotstandstill " 54 "GearnotP " 55 "EPBnotclamp " 56 "GuidenceWaitforsteeringcomplete " 57 "AbortHandondetect " 58 "Abortmaxnumberofmaneouvres " 59 "AbortGuidanceTimeout " 60 "AbortOtherreasons " 61 "CancleACCMode " 62 "ShiftGeartoD " ;
VAL_ 613 APA_ParkNotice 0 "IDLE " 1 "pPSCSearchR " 2 "pPSCSearchL " 3 "cPSCSearchR " 4 "cPSCSearchL " 5 "pPSCPSOKPosNOKR " 6 "pPSCPSOKPosNOKL " 7 "cPSCPSOKPosNOKR " 8 "cPSCPSOKPosNOKL " 9 "pPSCPSOKStopR " 10 "pPSCPSOKStopL " 11 "cPSCPSOKStopR " 12 "cPSCPSOKStopL " 13 "pPSCPSOKRGearR " 14 "pPSCPSOKRGearL " 15 "cPSCPSOKRGearR " 16 "cPSCPSOKRGearL " 17 "PSCPSOKReactive " 18 "ePSCPSOKRGearR " 19 "POCOKR " 20 "ePSCPSOKRGearL " 21 "POCTurnONIndicator " 22 "pPSCmovebwdR " 23 "pPSCmovebwdL " 24 "cPSCmovebwdR " 25 "cPSCmovebwdL " 26 "POCmovebwdR " 27 "POCmovebwdL " 28 "pPSCmovefwdR " 29 "pPSCmovefwdL " 30 "cPSCmovefwdR " 31 "cPSCmovefwdL " 32 "POCmovefwdR " 33 "POCmovefwdL " 34 "GuidanceInsertDGear " 35 "GuidanceInsertRGear " 36 "GuidanceStop " 37 "GuidenceWaitforsteeringcomplete " 38 "GuidenceSlowDown " 39 "Parkingmaneuvercompleted " 40 "reserved " 41 "AbortESPIntervention " 42 "AbortSpeedtoohigh " 43 "AbortHandondetect " 44 "Abortmaxnumberofmaneouvresreached " 45 "AbortTrailorattached " 46 "AbortUserdeactivated " 47 "FailureSensorsBlinded " 48 "APAinternalFailure " 49 "APAexternalFailure " 50 "SearchingSlowDown " 51 "AbortGuidanceTimeout " 52 "AbortOffTrack " 53 "AbortPStoosmall " 54 "AbortOtherreasons " 55 "POCNofrontobstacle " 56 "SearchingforPakingSlotRightEchelon " 57 "SearchingforPakingSlotLeftEchelon " 58 "ParkingSpaceFoundRightEchelon " 59 "ParkingSpaceFoundLeftEchelon " ;
VAL_ 613 APA_RemoteOnOff 0 "OFF " 1 "On " 2 "Notused " 3 "Invalid " ;
VAL_ 613 APA_ButtonPress 0 "PSCbuttonidle " 1 "PSCbuttonpressed " ;
VAL_ 613 APA_IncreasePressureReq 0 "Notrequest " 1 "Request " ;
VAL_ 613 APA_TurnLightsCommand 0 "NoRequest " 1 "LeftLightOn " 2 "RightLightOn " 3 "DoubleLightsOn " ;
VAL_ 613 APA_SteeringAngleReqProtection 0 "NoRequest " 1 "RequestEPScontrol " 2 "EPScontrolactive " ;
VAL_ 613 APA_ErrorStatus 0 "NoError " 1 "Error " ;
VAL_ 613 APA_indication 0 "Nofunctionisactive " 1 "pPSCisactive " 2 "cPSCisactive " 3 "POCisactive " 4 "ePSCisactive " 5 "Invalid " ;
VAL_ 613 APA_APAOnOff 0 "OFF " 1 "ON " ;
VAL_ 613 APA_EmergenceBrake 0 "Notrequest " 1 "Request " ;
VAL_ 784 AMP_AllAlarmFailureStatus 0 "NoFailure " 1 "Failure " ;
VAL_ 784 AMP_IPEnableAlarmFailureStatus 0 "NoFailure " 1 "Failure " ;
VAL_ 784 AMP_MUTESETStatus 0 "Inactive " 1 "非静音 " 2 "静音 " 3 "reserved " ;
VAL_ 784 AMP_LRHeadSPKBalanceSETStatus 0 "Inactive " 1 "15（最左面） " 2 "14 " 17 "0（中间位置） " 31 "14 " 32 "15（最右面） " ;
VAL_ 784 AMP_AlarmVolSETStatus 0 "Inactive " 1 "低 " 2 "中 " 3 "高 " ;
VAL_ 784 AMP_HeadSPKMediaSETStatus 0 "Inactive " 1 "OFF " 2 "ON " 3 "reserved " ;
VAL_ 784 AMP_HeadSPKTelSETStatus 0 "Inactive " 1 "OFF " 2 "ON " 3 "reserved " ;
VAL_ 784 AMP_HeadSPKNIVISETStatus 0 "Inactive " 1 "OFF " 2 "ON " 3 "reserved " ;
VAL_ 782 AMP_LRBalanceSETStatus 0 "Inactive " 1 "127（最左面） " 2 "126 " 128 "0（中间位置） " 254 "126 " 255 "127（最右面） " ;
VAL_ 782 AMP_FRBalanceSETStatus 0 "Inactive " 1 "127（最前面） " 2 "126 " 128 "0（中间位置） " 254 "126 " 255 "127（最后面） " ;
VAL_ 782 AMP_CustomBassSETStatus 0 "Inactive " 1 "7 " 2 "6 " 8 "0 " 14 "6 " 15 "7 " ;
VAL_ 782 AMP_CustomMidrangeSETStatus 0 "Inactive " 1 "7 " 2 "6 " 8 "0 " 14 "6 " 15 "7 " ;
VAL_ 782 AMP_CustomTrebleSETStatus 0 "Inactive " 1 "7 " 2 "6 " 8 "0 " 14 "6 " 15 "7 " ;
VAL_ 1368 WLCM_WirelessChargingSetStatus 0 "inactive " 1 "off " 2 "on " 3 "Reserved " ;
VAL_ 738 RRS_RRMSensorDiagnosis 0 "Normal " 1 "Abnormal " 2 "Reserved " 3 "Invalid " ;
VAL_ 738 RRS_LRMSensorDiagnosis 0 "Normal " 1 "Abnormal " 2 "Reserved " 3 "Invalid " ;
VAL_ 738 RRS_RRCSensorDiagnosis 0 "Normal " 1 "Abnormal " 2 "Reserved " 3 "Invalid " ;
VAL_ 738 RRS_LRCSensorDiagnosis 0 "Normal " 1 "Abnormal " 2 "Reserved " 3 "Invalid " ;
VAL_ 738 RRS_RFMSensorDiagnosis 0 "Normal " 1 "Abnormal " 2 "Reserved " 3 "Invalid " ;
VAL_ 738 RRS_LFMSensorDiagnosis 0 "Normal " 1 "Abnormal " 2 "Reserved " 3 "Invalid " ;
VAL_ 738 RRS_RFCSensorDiagnosis 0 "Normal " 1 "Abnormal " 2 "Reserved " 3 "Invalid " ;
VAL_ 738 RRS_LFCSensorDiagnosis 0 "Normal " 1 "Abnormal " 2 "Reserved " 3 "Invalid " ;
VAL_ 736 RRS_SpkErrFlag 0 "NotFault " 1 "Fault " ;
VAL_ 736 RRS_RFMSnsErrFlag 0 "NotFault " 1 "Fault " ;
VAL_ 736 RRS_LFMSnsErrFlag 0 "NotFault " 1 "Fault " ;
VAL_ 736 RRS_SystemFailureFlag 0 "NotFailure " 1 "Failure " ;
VAL_ 736 RRS_SwitchIndicatorError 0 "NoError " 1 "Error " ;
VAL_ 736 RRS_ctrlModulErrFlag 0 "NotFault " 1 "Fault " ;
VAL_ 736 RRS_BattVoltErrFlag 0 "NotFault " 1 "Fault " ;
VAL_ 736 RRS_RRMidSnsErrFlag 0 "NotFault " 1 "Fault " ;
VAL_ 736 RRS_LRMidSnsErrFlag 0 "NotFault " 1 "Fault " ;
VAL_ 736 RRS_RRCSnsErrFlag 0 "NotFault " 1 "Fault " ;
VAL_ 736 RRS_LRCSnsErrFlag 0 "NotFault " 1 "Fault " ;
VAL_ 736 RRS_RFCSnsErrFlag 0 "NotFault " 1 "Fault " ;
VAL_ 736 RRS_LFCSnsErrFlag 0 "NotFault " 1 "Fault " ;
VAL_ 736 RRS_WarningFrequency 0 "不报警 " 1 "前角（940Hz） " 2 "后角（750Hz） " 3 "错误报警（1500Hz） " ;
VAL_ 736 RRS_FrontRadarActiveStatus 0 "Invalid " 1 "Activated " 2 "Deactivated " 3 "Reserved " ;
VAL_ 651 BCM_KeyAlarmStatus 0 "Disarmed " 1 "Prearmed " 2 "Armed " 3 "Activated " ;
VAL_ 651 PEPS_ShiftForbidReq 0 "AllowShift " 1 "ForbidShift " ;
VAL_ 651 BCM_RearDefrosterstatus 0 "OFF " 1 "ON " 2 "Notused " 3 "Reserved " ;
VAL_ 651 BCM_PowerStatusFeedback 0 "OFF " 1 "ACC " 2 "ON " 3 "Start " ;
VAL_ 651 BCM_emergencylightstatus 0 "OFF " 1 "ON " 2 "Notused " 3 "Error（故障） " ;
VAL_ 651 PEPS_RemoteStartReq 0 "NotRemoteStart " 1 "RemoteStart " 2 "Reserved " 3 "invalid " ;
VAL_ 651 LCM_LASSwitch 0 "NotPush未按下 " 1 "Push按下 " 2 "Reserved预留 " 3 "Fault " ;
VAL_ 651 PEPS_StartControlsignal 0 "NoRequest " 1 "StartupStart " 2 "StartupStop " 3 "Invalid " ;
VAL_ 651 BCM_HoodStatus 0 "Close " 1 "Open " ;
VAL_ 651 BCM_TurnIndicatorRight 0 "OFF " 1 "ON " 2 "Notused " 3 "Error " ;
VAL_ 651 BCM_TurnIndicatorLeft 0 "OFF " 1 "ON " 2 "Notused " 3 "Error " ;
VAL_ 651 BCM_DriverDoorStatus 0 "Close " 1 "Open " ;
VAL_ 651 BCM_ReversePosition 0 "NOTINReverse " 1 "INReverse " ;
VAL_ 651 PEPS_EngineStallReq 0 "NoRequest " 1 "StallRequest " ;
VAL_ 651 BCM_TurnLightSwitchSts 0 "NotActived " 1 "LeftActived " 2 "RightActived " 3 "Invalid " ;
VAL_ 651 BCM_HighBeamStatus 0 "OFF " 1 "ON " 2 "Notused " 3 "Reserved " ;
VAL_ 651 BCM_LowBeamStatus 0 "OFF " 1 "ON " 2 "Notused " 3 "Reserved " ;
VAL_ 610 BCM_PEPS_BlueTooth 0 "Invalid " 1 "Valid " 2 "Reserved " 3 "Reserved " ;
VAL_ 610 PEPS_APARemoteParkingOff 0 "NotPressed " 1 "Pressed " ;
VAL_ 610 PEPS_KeyStandbyPositionIndicator 0 "Inactive " 1 "ON " ;
VAL_ 610 PEPS_PEPSFailStatus 0 "NoError " 1 "Error " ;
VAL_ 610 PEPS_IMMOFeedback 0 "Inactive非认证状态 " 1 "Authenticating认证中 " 2 "Success成功 " 3 "Failed失败 " ;
VAL_ 610 PEPS_EngineStartupInhibitFB 0 "inactive " 1 "Inhibitsucces " ;
VAL_ 610 PEPS_PowerDistributionFaultBit 0 "NoError " 1 "Error " ;
VAL_ 610 PEPS_TBOX_RemoteIGNOnOffFeedback 0 "OFF " 1 "ON " 2 "Reserved " 3 "Invalid " ;
VAL_ 610 PEPS_FRCameraStart 0 "NoRequest " 1 "车外ON " 2 "车内ON " 3 "Invalid " ;
VAL_ 610 PEPS_PowerOff_NotPN_AlarmSignal 0 "Inactive " 1 "NOTPN " ;
VAL_ 610 PEPS_EngineStartupInhibitSts 0 "Notinhibit " 1 "Inhibit " ;
VAL_ 610 PEPS_APA_PowerMirrorFoldFeedback 0 "InActive " 1 "Fold " 2 "Open " 3 "Reserved " ;
VAL_ 610 PEPS_StartupButtonSignal 0 "OFF " 1 "ON " 2 "Error " 3 "不可用 " ;
VAL_ 610 PEPS_IMMOFailedAlarmsignal 0 "Inactive " 1 "IMMO与EMS认证失败 " ;
VAL_ 610 PEPS_UnallowStartSignal_Not_PN 0 "Inactive " 1 "未在P/N档 " ;
VAL_ 610 PEPS_EngineRuningWarning 0 "Inactive " 1 "ON " ;
VAL_ 610 PEPS_UnallowStart_ESCL_LOCK 0 "Inactive " 1 "ESCL未解锁 " ;
VAL_ 610 PEPS_PowerDistributionStatus 0 "OFF " 1 "ACC " 2 "ON " 3 "Start " ;
VAL_ 610 PEPS_APA_CloseWinFeedback 0 "InActive " 1 "Success " 2 "Failed " 3 "Reserved " ;
VAL_ 610 PEPS_UnallowStart_ESCL_Error 0 "Inactive " 1 "ESCL故障 " ;
VAL_ 610 PEPS_APARemoteParkingSwitch 0 "NotPressed " 1 "Pressed " ;
VAL_ 610 PEPS_APA_LockFeedback 0 "InActive " 1 "Success " 2 "Failed " 3 "Reserved " ;
VAL_ 610 PEPS_APA_Engine0ffFeedback 0 "InActive " 1 "Success " 2 "Failed " 3 "Reserved " ;
VAL_ 610 PEPS_RemoteAPADoneKeyOffReq 0 "invalid " 1 "request " 2 "notrequest " 3 "reserved " ;
VAL_ 610 PEPS_StartIndicatorSignal 0 "Inactive " 1 "请踩下制动踏板提示 " ;
VAL_ 1607 FIS_LoggingDataStatus 0 "Inactive " 1 "开始录入人脸 " 2 "人脸录入中 " 3 "人脸录入成功 " 4 "人脸录入失败 " 5 "人脸控制器同步数据成功 " 6 "人脸控制器同步数据失败 " 7 "Reserved " ;
VAL_ 1607 FIS_LoggingDataErrorFeedBack 0 "Inactive " 1 "车辆不静止 " 2 "非点火状态 " 3 "非P/N档 " ;
VAL_ 1605 FIS_BoundStatus 0 "Bound " 1 "Unbound " ;
VAL_ 1605 FIS_USBDiagnosis 0 "Normal " 1 "Abnormal " 2 "Reserved " 3 "Invalid " ;
VAL_ 1605 FIS_InCarSensorDiagnosis 0 "Normal " 1 "Abnormal " 2 "Reserved " 3 "Invalid " ;
VAL_ 1605 FIS_OutCarSensorDiagnosis 0 "Normal " 1 "Abnormal " 2 "Reserved " 3 "Invalid " ;
VAL_ 1605 FIS_GRSSubSetFeedback8 0 "OFF " 1 "ON " ;
VAL_ 1605 FIS_GRSSubSetFeedback9 0 "OFF " 1 "ON " ;
VAL_ 1605 FIS_GRSSubSetFeedback6 0 "OFF " 1 "ON " ;
VAL_ 1605 FIS_GRSSubSetFeedback7 0 "OFF " 1 "ON " ;
VAL_ 1605 FIS_GRSSubSetFeedback5 0 "OFF " 1 "ON " ;
VAL_ 1605 FIS_GRSSubSetFeedback4 0 "OFF " 1 "ON " ;
VAL_ 1605 FIS_GRSSubSetFeedback3 0 "OFF " 1 "ON " ;
VAL_ 1605 FIS_GRSSubSetFeedback2 0 "OFF " 1 "ON " ;
VAL_ 1605 FIS_GRSSubSetFeedback1 0 "OFF " 1 "ON " ;
VAL_ 1605 FIS_GRSsetFeedback 0 "NoFeedback " 1 "GRS开启成功 " 2 "GRS开启失败 " 3 "Reserved " ;
VAL_ 1605 FIS_FISDMSSubSetFeedback4 0 "OFF " 1 "ON " ;
VAL_ 1605 FIS_FISDMSSubSetFeedback3 0 "OFF " 1 "ON " ;
VAL_ 1605 FIS_FISDMSSubSetFeedback2 0 "OFF " 1 "ON " ;
VAL_ 1605 FIS_FISDMSSubSetFeedback1 0 "OFF " 1 "ON " ;
VAL_ 1605 FIS_SpeedLimit 0 "30 " 1 "40 " 2 "50 " 3 "60 " 4 "70 " 5 "80 " 6 "90 " 7 "100 " 8 "110 " 9 "120 " 10 "Reserved " 11 "Reserved " 12 "Reserved " 13 "Reserved " 14 "Reserved " 15 "NOlimit " ;
VAL_ 1605 FIS_FirePermit 0 "invalid " 1 "Deny " 2 "Permit " 3 "Reserved " ;
VAL_ 1605 FIS_UnLockPermit 0 "invalid " 1 "Deny " 2 "Permit " 3 "Reserved " ;
VAL_ 1605 FIS_Certificate_failed_reasons 0 "Invalid " 1 "未授权含未注册及ID过期 " 2 "未正视摄像头识别失败 " 3 "识别超时其他原因 " 4 "戴口罩识别失败 " 5 "光线不良识别失败 " 6 "戴墨镜识别失败 " 7 "Reserved " ;
VAL_ 1605 FIS_Certificate_failed_times 0 "0次 " 1 "1次 " 2 "2次 " 3 "3次 " 4 "4次 " 5 "5次 " 6 "6次 " 7 "7次 " ;
VAL_ 1605 FIS_DMSStatus 0 "NoFeedback " 1 "DMS报警开启 " 2 "DMS报警关闭 " 3 "Reserved " ;
VAL_ 1605 FIS_Status 0 "NoFeedback " 1 "人脸识别系统开启 " 2 "人脸识别系统关闭 " 3 "Reserved " ;
VAL_ 1605 FIS_InCarCameracoveredRemind 0 "Invalid " 1 "OFF " 2 "ON " 3 "Reserved " ;
VAL_ 1605 FIS_AuthenAgainPrompt 0 "OFF " 1 "ON（提示车主按一键启动开关） " ;
VAL_ 1605 FIS_DistinguishFlag_InCar 0 "Invalid " 1 "valid " ;
VAL_ 1605 FIS_VINReq 0 "NoRequest " 1 "Request " 2 "Reserved " 3 "Invalid " ;
VAL_ 1605 FIS_GameStartStst 0 "invalid " 1 "off " 2 "on " 3 "Reserved " ;
VAL_ 1605 FIS_CertificateSignal 0 "NoRequest " 1 "车外success " 2 "车内success " 3 "车外failed " 4 "车内failed " 5 "认证中 " 6 "系统功能关闭 " ;
VAL_ 1605 FIS_GameCount 0 "NoRequest " 1 "加1 " ;
VAL_ 935 FIS_PassengerDrowsinessStatus 0 "Awake " 1 "SlightlyDrowsy " 2 "Drowsy " 3 "Microsleep " 4 "Reserved " 5 "Unavailable " 6 "Unknown " 7 "Invalid " ;
VAL_ 854 FIS_DriverEyeDetect 0 "Invalid " 1 "Notdetected " 2 "detected " 3 "Reserved " ;
VAL_ 854 FIS_DriverPhoneCallSts 0 "NotInPhoneCall " 1 "InPhoneCall " ;
VAL_ 854 FIS_DrowsinessStatus 0 "Awake " 1 "SlightlyDrowsy " 2 "Drowsy " 3 "Microsleep " 4 "Reserved " 5 "Unavailable " 6 "Unknown " 7 "Invalid " ;
VAL_ 1554 AVM_FormatFAT32Req 0 "NoRequest " 1 "Request " ;
VAL_ 1554 AVM_DVRDeleteStatus 0 "norequest " 1 "deleting " 2 "deleted " 3 "failed " ;
VAL_ 1554 DVR_PrintScreenFeedback 0 "inactive " 1 "successful " 2 "failure " 3 "invalid " ;
VAL_ 1554 AVM_DVRReplaySpeedStatus 0 "NoRequest " 1 "forwardplay " 2 "rewindplay " 3 "invalid " ;
VAL_ 1554 AVM_DVRReplayCommandStatus 0 "NoRequest " 1 "Play " 2 "Pause " 3 "invalid " ;
VAL_ 1554 DVR_StorageStatus 0 "normal " 1 "error " 2 "full " 3 "lowspeed " ;
VAL_ 1554 DVR_NormalToEmergency 0 "off " 1 "reasuretoconvert " 2 "saving " 3 "saved " 4 "failed " 5 "reseved " 6 "reseved " 7 "invalid " ;
VAL_ 1554 DVR_DistortCorrection 0 "off " 1 "on " ;
VAL_ 1554 AVM_DVRModeFeedback 0 "Inactive " 1 "RealTimeMode " 2 "ReplayMode " 3 "SettingMode " ;
VAL_ 1554 DVR_ReplayMode 0 "norequest " 1 "cyclemodebrowse " 2 "emergencymodebrowse " 3 "photomodebrowse " 4 "cyclemodereplay " 5 "emergencymodereplay " 6 "photomodereplay " 7 "invalid " ;
VAL_ 1554 AVM_DVREditFeedback 0 "off " 1 "on " ;
VAL_ 1554 DVR_FormatStatus 0 "invalid " 1 "normal " 2 "ReadyFormat " 3 "Formatting " 4 "FormatComplete " 5 "Formatfailure " 6 "Can'tFormat " 7 "Reserved " ;
VAL_ 1554 DVR_EmergencyRecordStatus 0 "invalid " 1 "Unsuccessful " 2 "Success " 3 "Saving " ;
VAL_ 1554 DVR_DVRErrorRecordStatus 0 "Invalid " 1 "EnterDisplay " 2 "QuitDisplay " 3 "Reserved " ;
VAL_ 1554 DVR_PhotographResult 0 "invalid " 1 "success " 2 "fail " 3 "Reserved " ;
VAL_ 1554 DVR_DisplayVison 0 "norequest " 1 "front " 2 "rear " 3 "left " 4 "right " 5 "all " 6 "reserved " 7 "invalid " ;
VAL_ 1554 DVR_Error 0 "normal " 1 "error " ;
VAL_ 1554 DVR_RecordingCycleSetStatus 0 "invalid " 1 "1min " 2 "3min " 3 "5min " ;
VAL_ 1554 DVR_DVRTapeSetStatus 0 "invalid " 1 "off " 2 "on " 3 "Reserved " ;
VAL_ 1554 DVR_DVREnableSetStatus 0 "invalid " 1 "off " 2 "on " 3 "especially " ;
VAL_ 941 DVR_UpdateResult 0 "noaction（无升级操作） " 1 "updating（升级中） " 2 "updatesuccess（升级成功） " 3 "updatefail（升级失败） " ;
VAL_ 941 DVR_SdcardFullStatus 0 "notfull（空间未满） " 1 "emergencyspacefull（紧急空间满） " 2 "photospacefull（照片空间满） " 3 "emergencyspaceandphotospacefull " ;
VAL_ 941 DVR_SdcardErrorStatus 0 "noerror（Sd卡无错误） " 1 "nosdcard（Sd卡未挂载） " 2 "sdcarderror（Sd卡写错误） " 3 "sdcardformaterror（Sd卡格式错误） " 4 "sdcardinsufficient（Sd卡容量不足） " 5 "sdcardspeedlow（Sd卡速度过低） " 6 "sdcardrestoringreserved（Sd卡正在恢复文件） " 7 "sdcardtoolargeSd卡容量过大 " ;
VAL_ 992 AVM_StartOpenAvmSts 0 "Invalid " 1 "OFF " 2 "ON " 3 "Reserved " ;
VAL_ 992 AVM_TransparentCarFeedback 0 "Inactive " 1 "Off " 2 "50 " 3 "100 " ;
VAL_ 992 AVM_TurnlightFeedback 0 "Inactive " 1 "Off " 2 "On " 3 "Reserved " ;
VAL_ 992 AVM_RadarAVMFeedback 0 "OFF " 1 "TurnLightSwitch " 2 "SteeringAngle " 3 "Both " ;
VAL_ 992 AVM_CalibrationComfirm 0 "inactive " 1 "yes " 2 "no " 3 "invalid " ;
VAL_ 992 AVM_CalibrationStatus 0 "OFF " 1 "Calibrating " 2 "Success " 3 "Failed " 4 "overspeed " 5 "Findnoline " 6 "reserved " 7 "invalid " ;
VAL_ 992 AVM_MODAlert_Sound 0 "Off " 1 "Level1 " 2 "Reserved " 3 "Reserved " ;
VAL_ 992 AVM_MODFeedback 0 "Inactive " 1 "Off " 2 "On " 3 "Reserved " ;
VAL_ 992 AVM_3DFeedback 0 "disable " 1 "enable " 2 "Reserved " 3 "invalid " ;
VAL_ 992 AVM_TopLookDownFeedback 0 "Inactive " 1 "Off " 2 "On " 3 "Reserved " ;
VAL_ 992 AVM_RecordFeedback 0 "inactive " 1 "recording " 2 "recordfinished " 3 "invalid " ;
VAL_ 992 AVM_VisionAngle 0 "NoRequest " 1 "120° " 2 "180° " 3 "Invalid " ;
VAL_ 992 AVM_LineOnOff 0 "NotActive " 1 "Open " 2 "Close " 3 "Invalid " ;
VAL_ 992 AVM_OverspeedWarning 0 "NoRequest " 1 "Request " ;
VAL_ 992 AVM_DisplayReq 0 "NoRequest " 1 "Request " 2 "Reserved " 3 "notused " ;
VAL_ 1365 TBOX_TUIDFrameNumber 0 "0 " 1 "1 " 2 "2 " 3 "Invalid " ;
VAL_ 1343 TBOX_RmoteRoof 0 "NoRequest " 1 "Close " 2 "Open " 3 "Reserved " ;
VAL_ 1343 TBOX_RmoteTrunk 0 "NoRequest " 1 "Close " 2 "Open " 3 "Reserved " ;
VAL_ 909 TBOX_RemoteInstallReq 0 "无请求 " 1 "预约刷写 " 2 "远程刷写 " 3 "Invalid " ;
VAL_ 909 TBOX_RemoteDetectReq 0 "InActive " 1 "Active " 2 "Reserved " 3 "Invalid " ;
VAL_ 909 TBOX_RemoteAirCleanReq 0 "NoRequest " 1 "ACcleanopen " 2 "ACcleanclose " 3 "Invalid " ;
VAL_ 909 TBOX_CirculationModeReq 0 "NoReq " 1 "recycle " 2 "fresh " 3 "invalid " ;
VAL_ 909 TBOX_RemoteAirQualityInquire 0 "NoRequest " 1 "Request " 2 "Reserved " 3 "Invalid " ;
VAL_ 909 TBOX_RemoteSteerWheelHotReq 0 "NoRequest " 1 "HotRequest " 2 "close " 3 "Reserved " ;
VAL_ 909 TBOX_RemoteDriverSeatHotReq 0 "NoRequest " 1 "Hotlevel1 " 2 "Hotlevel2 " 3 "Hotlevel3 " 4 "AutoMode " 5 "Reserved " 6 "close " 7 "Reserved " ;
VAL_ 909 TBOX_RemotePassangerSeatHotReq 0 "NoRequest " 1 "Hotlevel1 " 2 "Hotlevel2 " 3 "Hotlevel3 " 4 "AutoMode " 5 "Reserved " 6 "close " 7 "Reserved " ;
VAL_ 909 TBOX_SearchCarReq 0 "NoRequest " 1 "Light " 2 "Horn " 3 "LightAndHorn " ;
VAL_ 909 TBOX_ACFanAdjustValueReq 0 "NoReq " 1 "Level1 " 8 "Level8 " 9 "UPReq " 10 "DOWNReq " 11 "reserve " 15 "reserve " ;
VAL_ 909 TBOX_RemoteACStartupReq 0 "NoRequest " 1 "ACStart " 2 "ACStop " 3 "Invalid " ;
VAL_ 909 TBOX_VehicleStatusDemandReq 0 "NoRequest " 1 "Request " ;
VAL_ 909 TBOX_RemoteStartRunTime 0 "NoReq " 1 "10min " 2 "15min " 3 "20min " 4 "25min " 5 "30min " 6 "Reserved " 7 "Invalid " ;
VAL_ 909 TBOX_VINMatchStatus 0 "Notmatched " 1 "matched " 2 "matchedunsuccess " 3 "Invalid " ;
VAL_ 909 TBOX_VINReq 0 "NoRequest " 1 "Request " 2 "Reserved " 3 "Invalid " ;
VAL_ 909 TBOX_CarRemind 0 "inactive " 1 "active " ;
VAL_ 909 TBOX_AudioRequest 0 "NoRequest " 1 "Ecallrequest " 2 "Becallrequest " 3 "Invalid " ;
VAL_ 909 TBOX_ChangePartStatus 0 "NotChange " 1 "Changed " ;
VAL_ 909 TBOX_RemoteEngineStartupReq 0 "NoRequest " 1 "EngineStart " 2 "EngineStop " 3 "Invalid " ;
VAL_ 909 TBOX_EngineStartupInhibit 0 "NoInhibit " 1 "InhibitEngineStart " 2 "Reserved " 3 "Invalid " ;
VAL_ 909 TBOX_LockCommand 0 "NoRequest " 1 "RemoteLock " 2 "RemoteUnlock " 3 "Invalid " ;
VAL_ 909 TBOX_VehicleVedioDetectReq 0 "NoRequest " 1 "Request " 2 "Reserved " 3 "Invalid " ;
VAL_ 908 TBOX_RemoteWindowSignalReq 0 "NoRequest " 1 "RemoteClose " 2 "RemoteOpen " 3 "Invalid " ;
VAL_ 908 TBOX_TrunkReq 0 "NoRequest " 1 "Remotelock " 2 "RemoteUnlock " 3 "Invalid " ;
VAL_ 908 TBOX_PositionLampReq 0 "NoRequest " 1 "RemoteClose " 2 "RemoteOpen " 3 "Invalid " ;
VAL_ 908 TBOX_RemoteSunroofSignalReq 0 "NoRequest " 1 "RemoteClose " 2 "RemoteOpen " 3 "Invalid " ;
VAL_ 908 TBOX_FaceIDupdate 0 "Inactive " 1 "Active " ;
VAL_ 908 TBOX_RemotedefrostingReq 0 "NoRequest " 1 "open " 2 "close " 3 "Invalid " ;
VAL_ 908 TBOX_activateStatus 0 "Notactivated " 1 "activated " ;
VAL_ 623 BM_BLEConnectSts 0 "OFF " 1 "Invalid " 2 "BroadCast " 3 "Connection " ;
VAL_ 623 BM_BTKeyNumber 0 "编号1 " 1 "编号2 " 2 "编号3 " 3 "编号4 " 4 "编号5 " 5 "编号6 " 6 "编号7 " 7 "编号8 " ;
VAL_ 623 BM_MPPosition 0 "位置无效 " 1 "PS " 2 "PE " 3 "PEPS " ;
VAL_ 623 BM_ConnectSts 0 "connect " 1 "disonnect " ;
VAL_ 622 BM_OneTouchDirectionSelect 0 "Inactive " 1 "Forward " 2 "Backward " 3 "Reserved " ;
VAL_ 622 BM_OneTouchResponseSwitch 0 "Invalid " 1 "OFF " 2 "ON " 3 "Reserved " ;
VAL_ 622 BM_RPASwitch 0 "Invalid " 1 "OFF " 2 "ON " 3 "Reserved " ;
VAL_ 622 BM_APAFunctionmoduleEnable 0 "inactive " 1 "OFF " 2 "ON " 3 "Invalid " ;
VAL_ 622 BM_APAManeuverStart 0 "NotPresse " 1 "Presse " ;
VAL_ 622 BM__StartControlsignal 0 "NoRequest " 1 "StartupStart " 2 "StartupStop " 3 "Invalid " ;
VAL_ 622 BM_APAManeuverCancel 0 "NotPressed " 1 "Pressed " ;
VAL_ 622 BM_APAManeuverSuspend 0 "NotPressed " 1 "Pressed " ;
VAL_ 622 BM_All_WindowClose 0 "Inactive " 1 "关车窗 " ;
VAL_ 622 BM_All_WindowOpen 0 "Inactive " 1 "开车窗 " ;
VAL_ 622 BM_APAPOCModeSelect 0 "Invalid " 1 "LeftParkOut " 2 "RightParkOut " 3 "Reserved " ;
VAL_ 622 BM_SearchCarSignal 0 "NoRequest " 1 "灯光 " 2 "灯声 " 3 "声音 " ;
VAL_ 622 BM_LuggageUnlockSignal 0 "Inactive " 1 "遥控行李箱解锁 " ;
VAL_ 622 BM_LuggagelockSignal 0 "Inactive " 1 "遥控行李箱闭锁 " ;
VAL_ 622 BM_SunroofClose 0 "Inactive " 1 "关天窗 " ;
VAL_ 622 BM_SunroofOpen 0 "Inactive " 1 "开天窗 " ;
VAL_ 622 BM_LockSignal 0 "Inactive " 1 "闭锁 " ;
VAL_ 622 BM_UnlockSignal 0 "Inactive " 1 "解锁 " ;
VAL_ 652 HU_FIS_DIST_switch_signal 0 "按键未按下 " 1 "按键按下 " 2 "假按键 " 3 "Error " ;
VAL_ 652 HU_FIS_IACCenable_switch_signal 0 "按键未按下 " 1 "按键按下 " 2 "假按键 " 3 "Error " ;
VAL_ 652 HU_FIS_Crusie_switch_signal 0 "按键未按下 " 1 "按键按下 " 2 "假按键 " 3 "Error " ;
VAL_ 652 HU_FIS_RESPlus_switch_signal 0 "按键未按下 " 1 "按键按下 " 2 "假按键 " 3 "Error " ;
VAL_ 652 HU_FIS_SETReduce_switch_signal 0 "按键未按下 " 1 "按键按下 " 2 "假按键 " 3 "Error " ;
VAL_ 1603 OpenIDCharsValid 0 "字符0有效 " 1 "字符01有效 " 31 "所有字符有效 " ;
VAL_ 1598 HU_DSMPassengerOneKeyForwordReq 0 "NoRequest " 1 "Requet " ;
VAL_ 1550 HU_MirrorPositionSaved_Reques 0 "NoRequet " 1 "驾驶位置 " 3 "Reserved " ;
VAL_ 1550 HU_DSMComity_SwitchSet 0 "OFF " 1 "OPEN " 2 "Reserved " 3 "invailid " ;
VAL_ 1550 HU_DSMRighttMirrorYPositionRequest 15 "invalid " ;
VAL_ 1550 HU_DSMRightMirrorXPositionRequest 15 "invalid " ;
VAL_ 1550 HU_DSMLeftMirrorYPositionRequest 15 "invalid " ;
VAL_ 1550 HU_DSMLeftMirrorXPositionRequest 15 "invalid " ;
VAL_ 1550 HU_Current_position 0 "NoSetPosition " 1 "SetPosition " ;
VAL_ 1550 HU_PaDSMPositionRequest 0 "NoRequet " 1 "驾驶位置 " 2 "休息位置 " 3 "Reserved " ;
VAL_ 1550 HU_DrDSMPositionRequest 0 "NoRequet " 1 "驾驶位置 " 2 "休息位置 " 3 "Reserved " ;
VAL_ 1550 HU_PaDSMPositionSavedRequest 0 "NoRequet " 1 "驾驶位置 " 2 "休息位置 " 3 "Reserved " ;
VAL_ 1550 HU_DrDSMPositionSavedRequest 0 "NoRequet " 1 "驾驶位置 " 2 "休息位置 " 3 "Reserved " ;
VAL_ 1550 HU_DSMComitySet 0 "无效 " 1 "前 " 2 "中 " 3 "后 " ;
VAL_ 1550 HU_FRFuntionSet 0 "invalid " 1 "off " 2 "on " 3 "Reserved " ;
VAL_ 1550 HU_MirrorTurnSet 0 "invalid " 1 "off " 2 "on " 3 "Reserved " ;
VAL_ 1550 HU_DSM_PositionSaved_Feedback 0 "invalid " 1 "Yes " 2 "No " 3 "Reserved " ;
VAL_ 1549 HU_GameStartRuest 0 "invalid " 1 "off " 2 "on " 3 "Reserved " ;
VAL_ 1549 HU_GRSSubSet9 0 "invalid " 1 "off " 2 "on " 3 "Reserved " ;
VAL_ 1549 HU_GRSSubSet8 0 "invalid " 1 "off " 2 "on " 3 "Reserved " ;
VAL_ 1549 HU_GRSSubSet7 0 "invalid " 1 "off " 2 "on " 3 "Reserved " ;
VAL_ 1549 HU_GRSSubSet6 0 "invalid " 1 "off " 2 "on " 3 "Reserved " ;
VAL_ 1549 HU_LoggingDataReq 0 "NoRequst " 1 "主驾人脸录入请求 " 2 "SyncRequst数据同步请求 " 3 "副驾人脸录入请求 " ;
VAL_ 1549 HU_GRSSubSet5 0 "invalid " 1 "off " 2 "on " 3 "Reserved " ;
VAL_ 1549 HU_GRSSubSet4 0 "invalid " 1 "off " 2 "on " 3 "Reserved " ;
VAL_ 1549 HU_GRSSubSet3 0 "invalid " 1 "off " 2 "on " 3 "Reserved " ;
VAL_ 1549 HU_GRSSubSet2 0 "invalid " 1 "off " 2 "on " 3 "Reserved " ;
VAL_ 1549 HU_GRSSubSet1 0 "invalid " 1 "off " 2 "on " 3 "Reserved " ;
VAL_ 1549 HU_GRSset 0 "invalid " 1 "off " 2 "on " 3 "Reserved " ;
VAL_ 1545 IP_HUHeartbeat 0 "Inactive " 1 "OFF " 2 "ON " 3 "Reserved " ;
VAL_ 1544 HU_IPHeartbeat 0 "Inactive " 1 "OFF " 2 "ON " 3 "Reserved " ;
VAL_ 1543 HU_IpInformatTtransSts 0 "Norequest " 1 "传输中 " 2 "传输完成 " 3 "Reserved " ;
VAL_ 1543 HU_FlyingScreen_Request 0 "Norequest " 1 "Request " ;
VAL_ 1543 HU_IPConnection_acknowledge 0 "Inactive " 1 "OFF " 2 "ON " 3 "Reserved " ;
VAL_ 1537 HU_DMS_Broadcast_Feedback 0 "Inactive " 1 "end " 2 "Reserved " 3 "invalid " ;
VAL_ 1537 HU_DVRReplay_Video_Command 0 "inactive " 1 "LastVideo " 2 "NextVideo " 3 "DeleteVideo " 4 "Play " 5 "Pause " 6 "Reserved " 7 "Reserved " ;
VAL_ 1537 HU_FISDMSSubSet4 0 "invalid " 1 "off " 2 "on " 3 "Reserved " ;
VAL_ 1537 HU_FISDMSSubSet3 0 "invalid " 1 "off " 2 "on " 3 "Reserved " ;
VAL_ 1537 HU_FISDMSSubSet2 0 "invalid " 1 "off " 2 "on " 3 "Reserved " ;
VAL_ 1537 HU_FISDMSSubSet1 0 "invalid " 1 "off " 2 "on " 3 "Reserved " ;
VAL_ 1537 HU_FRDMSset 0 "invalid " 1 "off " 2 "on " 3 "Reserved " ;
VAL_ 1537 HU_CarWashModel 0 "invalid " 1 "off " 2 "on " 3 "车速过高退出 " ;
VAL_ 1537 HU_ODEnable 0 "Inactive " 1 "Off " 2 "On " 3 "Reserved " ;
VAL_ 1537 HU_WiperServiceReq 0 "Inactive " 1 "Acitve " ;
VAL_ 1537 HU_LockAutoClsSunroofSet 0 "Inactive " 1 "On " 2 "Off " 3 "Reserved " ;
VAL_ 1537 HU_CarWashMirrorFoldSet 0 "Invalid " 1 "OFF " 2 "ON " 3 "Reserved " ;
VAL_ 1537 HU_AutoTurnOnOffSwitch 0 "off " 1 "leftlighton " 2 "rightlighton " 3 "Invalid " ;
VAL_ 1537 HU_FCWSensitivity 0 "earlyearlyaktiv " 1 "earlylateaktiv正常灵敏 " 2 "latelateaktiv " 3 "Fault " ;
VAL_ 1408 HU_MaintainRemindReq 0 "无请求 " 1 "保养预警请求 " 2 "保养到期提示请求 " 3 "Invalid " ;
VAL_ 1405 HU_DSMMemoryPositionFeedback 0 "Inactive " 1 "Yes " 2 "No " 3 "Reserved " ;
VAL_ 1405 HU_FanComfortableModeSet 0 "NoReq " 1 "NormalSpeed " 2 "SlowSpeed " 3 "Reserved " ;
VAL_ 1405 HU_AutoDeFoggingSet 0 "Inactive " 1 "Off " 2 "On " 3 "Reserved " ;
VAL_ 1405 HU_TunnelAutoRecycleSet 0 "Inactive " 1 "Off " 2 "On " 3 "Reserved " ;
VAL_ 1405 HU_VC_AtmosphereLightReq 0 "Inactive " 1 "Off " 2 "On " 3 "Reserved " ;
VAL_ 1405 HU_BlueTooth_Reduce_WindSpeedSet 0 "invalid " 1 "off " 2 "on " 3 "Reserved " ;
VAL_ 1405 HU_ReserveGearAutoRecycleSet 0 "invalid " 1 "off " 2 "on " 3 "Reserved " ;
VAL_ 1405 HU_AutowindSet1 0 "notset " 1 "on " 2 "off " 3 "Reserved " ;
VAL_ 1405 HU_RemoteControlSunroofSet 0 "Inactive " 1 "Off " 2 "On " 3 "Reserved " ;
VAL_ 1405 HU_AutowindSet3 0 "notset " 1 "on " 2 "off " 3 "Reserved " ;
VAL_ 1405 HU_AutowindSet2 0 "notset " 1 "on " 2 "off " 3 "Reserved " ;
VAL_ 1405 HU_VC_ShadingCurtainReq 0 "Inactive " 1 "Off " 2 "On " 3 "Reserved " ;
VAL_ 1370 HU_DVRUpdateReq 0 "noaction（无操作） " 1 "UpdateReq（升级请求） " 2 "reserved（预留） " 3 "reserved（预留） " ;
VAL_ 1370 HU_AVMDVRReplayModeReq 0 "norequest " 1 "entercyclemodebrowse " 2 "enteremergencymodebrowse " 3 "enterphotomodebrowse " 4 "enterDASmodebrowse " 5 "Reserved " 6 "Reserved " 7 "Reserved " ;
VAL_ 1370 HU_BodyColourSet 0 "Inactive " 1 "colour1 " 2 "colour2 " 3 "colour3 " 4 "colour4 " 5 "colour5 " 6 "colour6 " 7 "colour7 " 8 "colour8 " 9 "colour9 " 10 "colour10 " 11 "colour11 " 12 "colour12 " 13 "colour13 " 14 "colour14 " 15 "Reserved " ;
VAL_ 1363 HU_BuzzingAlarmStatus 0 "Nowarning " 1 "warning " 2 "warned " 3 "invalid " ;
VAL_ 1363 HU_HUDDisplayLDW 0 "notactive " 1 "display " 2 "nodisplay " 5 "Reserved " ;
VAL_ 1363 HU_HUDDisplayACC 0 "notactive " 1 "display " 2 "nodisplay " 4 "Reserved " ;
VAL_ 1363 HU_HUDDisplayNav 0 "notactive " 1 "display " 2 "nodisplay " 3 "Reserved " ;
VAL_ 1363 HU_RearSeatbeltWarningEnable 0 "NoReq " 1 "Off " 2 "On " 3 "Reserved " ;
VAL_ 1363 HU_ACCPush 0 "NoPush " 1 "Push " ;
VAL_ 1363 HU_RADMWaringEnable 0 "Off " 1 "On " ;
VAL_ 1363 HU_HUDDimAdjust 0 "notactive " 1 "level1 " 2 "level2 " 3 "level3 " 4 "level4 " 5 "level5 " ;
VAL_ 1362 HU_StartOpenAvmSet 0 "Invalid " 1 "OFF " 2 "ON " 3 "Reserved " ;
VAL_ 1362 HU_BSDLCASetting 0 "early " 1 "normal " 2 "late " 3 "Off " ;
VAL_ 1362 HU_APAActive2 0 "Invalid " 1 "Activate " 2 "Deactivate " 3 "Reserved " ;
VAL_ 1362 HU_FrontRadarActive 0 "Invalid " 1 "Activate " 2 "Deactivate " 3 "Reserved " ;
VAL_ 1362 HU_VC_CruiseControl 0 "NoRequest " 1 "ACCActivate " 2 "ACCResume " 3 "IACCActivate " 4 "IACCResume " 5 "Cancel " 6 "Reserved " 7 "Invalid " ;
VAL_ 1362 HU_VC_CruiseSetDistance 0 "NoRequest " 1 "Level1 " 2 "Level2 " 3 "Level3 " 4 "Level4 " 5 "ForwardReq " 6 "BackwardReq " 7 "Invalid " ;
VAL_ 1362 HU_AutoBrakeEnable 0 "off " 1 "on " ;
VAL_ 1341 HU_SystemVolumeMute 0 "NoReq " 1 "Mute " 2 "NotMute " 3 "Reserved " ;
VAL_ 1338 HU_MusicLightModeSelect 0 "Inactive " 1 "LightMode1 " 2 "LightMode2 " 3 "LightMode3 " 4 "LightMode4 " 5 "LightMode5 " 6 "LightMode6 " 7 "LightMode7 " ;
VAL_ 1338 HU_MusicLightRequest 0 "inactive " 1 "enter " 2 "exit " 3 "Reserved " ;
VAL_ 1338 HU_MusicPlaySetBackSignal 0 "inactive " 1 "start " 2 "end " 3 "Reserved " ;
VAL_ 1338 HU_WelcomeAtmoLightEnable 0 "Inactive " 1 "Off " 2 "On " 3 "Reserved " ;
VAL_ 1338 HU_WirelessChargingSet 0 "Inactive " 1 "Off " 2 "On " 3 "Reserved " ;
VAL_ 1338 HU_AtmoLightLinkDoorEnable 0 "Inactive " 1 "Off " 2 "On " 3 "Reserved " ;
VAL_ 1338 HU_AtmoLightLinkTopLightEnable 0 "Inactive " 1 "Off " 2 "On " 3 "Reserved " ;
VAL_ 1338 HU_AtmoLightLinkOverspeedEnable 0 "Inactive " 1 "Off " 2 "On " 3 "Reserved " ;
VAL_ 1338 HU_AtmoLightLinkStartRequest 0 "Inactive " 1 "Off " 2 "On " 3 "Reserved " ;
VAL_ 1335 HU_RKEUnlockDoorTypeSet 0 "inactive " 1 "Unlockfourdoor " 2 "UnlockDriverdoor " 3 "Reserved " ;
VAL_ 1335 HU_AutoIGNOFFUnlockSet 0 "inactive " 1 "off " 2 "on " 3 "Reserved " ;
VAL_ 1335 HU_RemoteControlWindowSet 0 "Inactive " 1 "Off " 2 "On " 3 "Reserved " ;
VAL_ 1335 HU_DrEasyEntrySet 0 "Inactive " 1 "Off " 2 "On " 3 "Reserved " ;
VAL_ 1335 HU_PaEasyEntrySet 0 "Inactive " 1 "Off " 2 "On " 3 "Reserved " ;
VAL_ 1335 HU_FollowMeHomeLightSet 0 "inactive " 1 "OFF " 2 "15s " 3 "30s " 4 "60s " 5 "120s " 6 "Reserved " 7 "Reserved " ;
VAL_ 1335 HU_AtmoLightAAEnable 0 "inactive " 1 "On " 2 "Off " 3 "Reserved " ;
VAL_ 1335 HU_AutoFlashlightovertakeSet 0 "inactive " 1 "On " 2 "Off " 3 "Reserved " ;
VAL_ 1335 HU_TwiceLockDoorSet 0 "inactive " 1 "On " 2 "Off " 3 "Reserved " ;
VAL_ 1335 HU_AutoLeaveLockSet 0 "Inactive " 1 "Close " 2 "30s " 3 "60s " 4 "120s " 5 "180s " 6 "240s " 7 "300s " ;
VAL_ 1335 HU_HonkovertakeSet 0 "Inactive " 1 "Off " 2 "On " 3 "Reserved " ;
VAL_ 1335 HU_RearWiperSet 0 "Inactive " 1 "Off " 2 "On " 3 "Reserved " ;
VAL_ 1335 HU_LockAutoClsWinSet 0 "Inactive " 1 "On " 2 "Off " 3 "Reserved " ;
VAL_ 1335 HU_MirrorSetStatus 0 "Inactive " 1 "Off " 2 "On " 3 "Reserved " ;
VAL_ 1335 HU_AutoSpeedLockSet 0 "inactive " 1 "off " 2 "on " 3 "Reserved " ;
VAL_ 1335 HU_MirrorAutoFoldSet 0 "Inactive " 1 "Off " 2 "On " 3 "Reserved " ;
VAL_ 1335 HU_SmartUnlockSet 0 "invalid " 1 "off " 2 "on " 3 "Reserved " ;
VAL_ 1335 HU_SmartLockSet 0 "invalid " 1 "off " 2 "on " 3 "Reserved " ;
VAL_ 1335 HU_DriverSeatAdjust 0 "Inactive " 1 "Position1 " 2 "Position2 " 3 "Position3 " ;
VAL_ 1335 HU_RemoteControlWindowUpSet 0 "Inactive " 1 "Off " 2 "On " 3 "Reserved " ;
VAL_ 1335 HU_RainCtrlSunRoofSet 0 "Inactive " 1 "Off " 2 "On " 3 "Reserved " ;
VAL_ 1335 HU_Autoturnlightovertakemodeset 0 "Inactive " 1 "Off " 2 "On " 3 "Reserved " ;
VAL_ 1335 HU_RainOpenLightSet 0 "Inactive " 1 "Off " 2 "On " 3 "Reserved " ;

VAL_ 1327 HU_ACScenarioReq 0 "NoReq " 1 "急速降温 " 2 "舒适 " 3 "快速制热 " 4 "智能通风 " 5 "自定义 " ;
VAL_ 1327 HU_ACComfortAdjustment 0 "NoReq " 1 "轻柔 " 2 "适中 " 3 "强劲 " ;
VAL_ 1325 HU_ACControlMode 0 "NoReq " 1 "TouchControl " 2 "VoiceControl " 3 "Invalid " ;
VAL_ 1325 HU_FrontAUTOACOnReq 0 "NoReq " 1 "Req " 2 "reserved " 3 "invalid " ;
VAL_ 1325 HU_FrontACOffReq 0 "NoReq " 1 "Req " 2 "ON语音打开空调 " 3 "invalid " ;
VAL_ 1325 HU_ACDEFAdjustReq 0 "NoReq " 1 "OFF " 2 "ON " 3 "DEF " ;
VAL_ 1325 HU_ACRDEFAdjustReq 0 "NoReq " 1 "OFF " 2 "ON " 3 "DEF " ;
VAL_ 1325 HU_IonizerReq 0 "NoReq " 1 "IonizerOn " 2 "IonizerOff " 3 "IonizerReq " ;
VAL_ 1325 HU_MaxDefrost_Switch 0 "Inactive " 1 "Active " ;
VAL_ 1325 HU_ACreq 0 "NoReq " 1 "Req " 2 "reserved " 3 "Invalid " ;
VAL_ 1325 HU_SyncReq 0 "NoReq " 1 "Req " 2 "reserved " 3 "Invalid " ;
VAL_ 1325 HU_VentilationOn 0 "Inactive " 1 "Off " 2 "Default " 3 "UserDefined " ;
VAL_ 1325 HU_AQSReq 0 "NoReq " 1 "Off " 2 "On " 3 "Press " ;
VAL_ 1325 HU_MaxACReq 0 "NoReq " 1 "Off " 2 "On " 3 "Press " ;
VAL_ 1319 HU_ShootControl 0 "Inactive " 1 "ShootReq " 2 "Reserved " 3 "Reserved " ;
VAL_ 1319 HU_TransparentCarSwitch 0 "Inactive " 1 "Off " 2 "50 " 3 "100 " ;
VAL_ 1319 HU_AVMCalibrationSwitch 0 "Inactive " 1 "Calibrate " 2 "EditCalibrate " 3 "Reset " ;
VAL_ 1319 HU_MODEnable 0 "Inactive " 1 "Off " 2 "On " 3 "Reserved " ;
VAL_ 1319 HU_DVREmergencyRecord 0 "Inactive " 1 "Record " 2 "Reserved " 3 "Invalid " ;
VAL_ 1319 HU_VibrationWarningStatus 0 "Inactive " 1 "Acitve " ;
VAL_ 1319 HU_DVRReplayMode 0 "NoRequest " 1 "EnterCycleModeBrowse " 2 "EnterEmergencyModeBrowse " 3 "EnterPhotoModeBrowse " ;
VAL_ 1319 HU_ResolutionSet 0 "Inactive " 1 "1080P " 2 "720P " 3 "Reserved " ;
VAL_ 1319 HU_DVRDistortCorrectSwitch 0 "Inactive " 1 "Off " 2 "On " 3 "Reserved " ;
VAL_ 1319 HU_TurnLightAVMSwitch 0 "OFF " 1 "TurnLightSwitch " 2 "SteeringAngle " 3 "Both " ;
VAL_ 1319 HU_RadarAVMSwitch 0 "Inactive " 1 "Off " 2 "On " 4 "Reserved " ;
VAL_ 1319 HU_DVRPrintScreen 0 "Inactive " 1 "PrintScreen " 2 "Reserved " 3 "Reserved " ;
VAL_ 1319 HU_DVRReplaySpeed 0 "NoRequest " 1 "ForwardPlay " 2 "RewindPlay " 3 "Reserved " ;
VAL_ 1319 HU_DVREnableSet 0 "Inactive " 1 "Off " 2 "On " 3 "Reserved " ;
VAL_ 1319 HU_DVRTapeSet 0 "Inactive " 1 "Off " 2 "On " 3 "Reserved " ;
VAL_ 1319 HU_DVRVedioSeek 0 "NoRequest " 1 "Prev " 2 "Next " 3 "Exit " ;
VAL_ 1319 HU_DVRDisplayVision 0 "NoRequest " 1 "Front " 2 "Rear " 3 "Left " 4 "Right " 5 "All " 6 "Reserved " 7 "Invalid " ;
VAL_ 1319 HU_AVMCalibrationConfirm 0 "Inactive " 1 "Yes " 2 "No " 3 "Reserved " ;
VAL_ 1319 HU_DVRReplayCommand 0 "NoRequest " 1 "Play " 2 "Pause " 3 "Reserved " ;
VAL_ 1319 HU_RecordingcycleSetting 0 "inactive " 1 "1min " 2 "3min " 3 "5min " ;
VAL_ 1319 HU_DVRFormatReq 0 "inactive " 1 "Formatcancel " 2 "Format " 3 "Reserved " ;
VAL_ 1319 HU_TopLookDownSwitch 0 "Inactive " 1 "Off " 2 "On " 3 "Reserved " ;
VAL_ 1311 HU_LightingDoorOpenWarningSet 0 "Invalid " 1 "OFF " 3 "Reserved " ;
VAL_ 1311 HU_LightingBackwardWarningSet 0 "Invalid " 1 "OFF " 3 "Reserved " ;
VAL_ 1311 HU_ALCVoiceWakeAssociation 0 "Invalid " 1 "OFF " 3 "Reserved " ;
VAL_ 1311 HU_ALCACTemperatureAssociation 0 "Invalid " 1 "OFF " 3 "Reserved " ;
VAL_ 1311 HU_ALCRhythmSet 0 "Invalid " 1 "OFF " 3 "Reserved " ;
VAL_ 1311 HU_ALCDrivingModeAssociation 0 "Invalid " 1 "OFF " 3 "Reserved " ;
VAL_ 1311 HU_RefreshModeEnable 0 "Inactive " 1 "主驾清新提神 " 2 "副驾清新提神 " 3 "前排清新提神 " ;
VAL_ 1311 HU_SenseAQIEnable 0 "Inactive " 1 "Off " 2 "On " 3 "Reserved " ;
VAL_ 1306 HU_VoiceWelcometSet 0 "Inactive " 1 "Off " 2 "On " 3 "Reserved " ;
VAL_ 1306 HU_RemoteControlSwtichSet 0 "invalid " 1 "LightandSound " 2 "onlyLight " 3 "onlySound " 4 "车外语音拟声加闪灯 " 5 "仅车外语音拟声 " 6 "Reserved " 7 "Reserved " ;
VAL_ 1306 HU_ShemeColorsSwitchSet 0 "NoRequest " 1 "主题1 " 2 "主题2 " 3 "主题3 " 4 "主题模式联动 " 5 "主题4 " 6 "Reserved " 7 "Reserved " ;
VAL_ 1306 HU_ScreenPowerOn 0 "Off " 1 "On " ;
VAL_ 1300 HU_ObstacleSafeDistanceSet 0 "Inactive " 1 "30 " 2 "40 " 3 "50 " 4 "60 " 5 "70 " 6 "80 " 7 "Reserved " ;
VAL_ 1300 HU_TJPEnable 0 "Inactive " 1 "Off " 2 "On " 3 "Reserved " ;
VAL_ 1300 HU_ParkingConfirm 0 "NoRequest " 1 "Request " ;
VAL_ 1300 HU_Uls_BSD_Activation 0 "inactive " 1 "On " 2 "Off " 3 "Reserved " ;
VAL_ 1300 HU_FCTBEnable 0 "Inactive " 1 "Off " 2 "On " 3 "Reserved " ;
VAL_ 1300 HU_Uls_FKP_Activation 0 "inactive " 1 "On " 2 "Off " 3 "Reserved " ;
VAL_ 1300 HU_ParkingResume 0 "NoRequest " 1 "Request " ;
VAL_ 1300 HU_OverspeedWarningEnable 0 "Inactive " 1 "OFF " 2 "ON " 3 "Reserved " ;
VAL_ 1300 HU_AudioWarningEnable 0 "inactive " 1 "Off " 2 "On " 3 "Reserved " ;
VAL_ 1300 HU_LockCtrlEnable 0 "Inactive " 1 "Off " 2 "On " 3 "Reserved " ;
VAL_ 1300 HU_IACCEnable 0 "Inactive " 1 "Off " 2 "On " 3 "Reserved " ;
VAL_ 1300 HU_OverspeedSoundWarEnable 0 "Inactive " 1 "Off " 2 "On " 3 "Reserved " ;
VAL_ 1300 HU_SEAEnable 0 "inactive " 1 "Off " 2 "On " 3 "Reserved " ;
VAL_ 1300 HU_RCTBEnable 0 "Inactive " 1 "Off " 2 "On " 3 "Reserved " ;
VAL_ 1300 HU_LDWShakeLev 0 "inactive " 1 "low " 2 "normal " 3 "high " ;
VAL_ 1300 HU_FatigueDectionEnable 0 "Invalid " 1 "OFF " 2 "ON " 3 "Reserved " ;
VAL_ 1300 HU_TSRSwitch 0 "off " 1 "on " ;
VAL_ 1300 HU_HMAEnable 0 "off " 1 "on " ;
VAL_ 1300 HU_RCWEnable 0 "Inactive " 1 "Off " 2 "On " 3 "Reserved " ;
VAL_ 1300 HU_RCTAEnable 0 "inactive " 1 "Off " 2 "On " 3 "Reserved " ;
VAL_ 1300 HU_FCTAEnable 0 "Inactive " 1 "Off " 2 "On " 3 "Reserved " ;
VAL_ 1300 HU_ParkingModeSelect 0 "Inactive " 1 "InteriorParking " 2 "RemoteParking " 3 "ParkingResume " ;
VAL_ 1299 HU_VisionAngleReq 0 "NoRequest " 1 "120°请求 " 2 "180°请求 " 3 "Invalid " ;
VAL_ 1299 HU_DVREditSelected 0 "NotSelected " 1 "Selected " ;
VAL_ 1299 HU_RealTimeReq 0 "Inactive " 1 "Quit " 2 "Enter " 3 "Reserved " ;
VAL_ 1299 HU_InterfaceChangeSingnal 0 "Still " 1 "Press " 2 "Left " 3 "Right " 4 "Up " 5 "Down " 6 "TwoSides " 7 "reserved " ;
VAL_ 1299 HU_RebroadcastReq 0 "Inactive " 1 "Quit " 2 "Enter " 3 "Reserved " ;
VAL_ 1299 HU_DVRMode 0 "Inactive " 1 "RealTimeMode " 2 "ReplayMode " 3 "SettingMode " ;
VAL_ 1299 HU_3DAVMReq 0 "Disable " 1 "Enable " 2 "Reserved " 3 "Invalid " ;
VAL_ 1299 HU_AVMswitch 0 "norequest " 1 "request " ;
VAL_ 1293 HU_ALCEnable 0 "Invalid " 1 "OFF " 2 "ON " 3 "Reserved " ;
VAL_ 1293 HU_ALCswitchset 0 "Invalid " 1 "OFF " 2 "ON " 3 "Auto " ;
VAL_ 1286 HU_DriverSeatMemorySet 0 "Inactive " 1 "SeatPosition1 " 2 "SeatPosition2 " 3 "SeatPosition3 " ;
VAL_ 1286 HU_SunroofControlReq 0 "NoReq " 1 "RoofClose " 2 "RoofOpen " 3 "Invalid " ;
VAL_ 1286 HU_ACPassengerHeatReq 0 "NoReq " 1 "Level1 " 2 "Level2 " 3 "Level3 " 4 "AutoMode " 5 "Reserved " 6 "Off " 7 "Reserved " ;
VAL_ 1286 HU_ACDriverHeatReq 0 "NoReq " 1 "Level1 " 2 "Level2 " 3 "Level3 " 4 "AutoMode " 5 "Reserved " 6 "Off " 7 "Reserved " ;
VAL_ 1286 HU_UserIDReceiveFb 0 "无效 " 1 "收用户ID " 2 "接收用户ID错误 " 3 "Reserved " ;
VAL_ 1281 HU_LocalTimeSystem 0 "24h " 1 "12h " 2 "Reserved " 3 "Invalid " ;
VAL_ 1281 HU_AirHumidityValid 0 "Valid " 1 "Invalid " ;
VAL_ 1281 HU_LocalTimeValid 0 "Valid " 1 "NotValid " ;
VAL_ 1280 HU_CurrentLocationValid 0 "Valid " 1 "NotValid " ;
VAL_ 962 HU_TollInfo 0 "路径无收费站 " 1 "路径有收费站 " 2 "预留 " 3 "invalid " ;
VAL_ 962 HU_FallingRockInfo 0 "路径无落石 " 1 "路径有落石 " 2 "预留 " 3 "invalid " ;
VAL_ 962 HU_RampSide 0 "Unknown " 1 "道路左边 " 2 "道路右边 " 3 "无效 " ;
VAL_ 952 HU_NavGuiganceStatus 0 "没有导航引导路径 " 1 "有导航引导路径 " 2 "Reserved " 3 "Reserved " ;
VAL_ 952 HU_Byroad 0 "unknown " 1 "有岔路 " 2 "无岔路 " 3 "reserved " ;
VAL_ 952 HU_EnterTunnelInfo 0 "unknown " 1 "隧道入口 " 2 "隧道中 " 3 "隧道出口 " ;
VAL_ 943 HU_StartupStatus 0 "Startuping " 1 "Startuped " 2 "OFF " 3 "Reserve " ;
VAL_ 943 HU_Power_OnOff_Req 0 "NoReq " 1 "OFF " 2 "ACC " 3 "ON " ;
VAL_ 943 HU_NavSpeedLimitType 0 "Unknown " 1 "SpeedLimitSign " 2 "RoadCamera " 3 "Reserved " ;
VAL_ 943 HU_EnterCurveInfo 0 "unknown " 1 "弯道进口 " 2 "弯道中 " 3 "弯道出口 " ;
VAL_ 943 HU_NavStatus 0 "Normal " 1 "Error " ;
VAL_ 943 HU_RampInfo 0 "Unknown " 1 "有匝道但本车不出高速 " 2 "本车通过匝道进入高速 " 3 "本车通过匝道出高速 " ;
VAL_ 943 HU_NavSpeedLimitStatus 0 "valid " 1 "invalid " 2 "reserved " 3 "reserved " ;
VAL_ 943 HU_NavSpeedLimitUnits 3 "reserved " 2 "unitmph " 1 "unitkph " 0 "unknown " ;
VAL_ 943 HU_EnterRampInfo 0 "Unknown " 1 "匝道进口 " 2 "匝道中 " 3 "匝道出口 " ;
VAL_ 943 HU_NavSpeedLimit 0 "Unlimited " 1 "SL5 " 2 "SL10 " 32 "SL160 " 254 "Unknown " 255 "Invalid " ;
VAL_ 939 HU_HornStatus 0 "Off " 1 "On " ;
VAL_ 939 HU_ExhaustValEnable 0 "Inactive " 1 "Off " 2 "On " 3 "Reserved " ;
VAL_ 939 HU_SetDoorLight 0 "Inactive " 1 "On " 2 "Off " 3 "Reserved " ;
VAL_ 939 HU_SetAFS 0 "Inactive " 1 "Off " 2 "On " 3 "Reserved " ;
VAL_ 939 HU_EPSModeSet 0 "Inactive " 1 "Normal " 2 "Light " 3 "Heavy " ;
VAL_ 939 HU_STTEnable 0 "Inactive " 1 "Off " 2 "On " 3 "Reserved " ;
VAL_ 939 HU_AVHStatusSetReq 0 "Inactive " 1 "AVHOff " 2 "AVHOn " 3 "Reserved " ;
VAL_ 939 HU_ESPStatusSetReq 0 "Inactive " 1 "ESPOff " 2 "ESPOn " 3 "Reserved " ;
VAL_ 939 HU_HDCStatusSetReq 0 "Inactive " 1 "HDCOff " 2 "HDCOn " 3 "Reserved " ;
VAL_ 910 HU_APAModeSelect 0 "ParallelMode（平行） " 1 "CrossMode（垂直） " 2 "POCMode（泊出） " 3 "Invalid " 4 "EchelonMode（斜列式） " 5 "functionoff " 6 "default " 7 "Noselection " ;
VAL_ 910 HU_CrossParkingModeSet 0 "Inactive " 1 "BackIn " 2 "HeadIn " 3 "Reserved " ;
VAL_ 910 HU_ASPSwitch 0 "Inactive " 1 "Off " 2 "On " 3 "Reserved " ;
VAL_ 910 HU_EXT_RemoteDetectUploadStatus 0 "Invalid " 1 "Yes " 2 "No " 3 "Reserved " ;
VAL_ 910 HU_PACModeSelect 0 "normal " 1 "parallel " 2 "asistantlineoff " 3 "Invalid " ;
VAL_ 910 HU_ASPRemindEnable 0 "Inactive " 1 "Off " 2 "On " 3 "Reserved " ;
VAL_ 910 HU_LanguageSync 0 "Chinese " 1 "English " 2 "Russian " 3 "Arabic其他位预留 " ;
VAL_ 910 HU_SlotUserSelected 0 "Noselected " 1 "LeftSlot1 " 2 "LeftSlot2 " 3 "RightSlot1 " 4 "RightSlot2 " 5 "LeftParkOut " 6 "RightParkOut " 7 "Invalid " ;
VAL_ 910 HU_LAEBEnable 0 "Inactive " 1 "Off " 2 "On " 3 "Reserved " ;
VAL_ 910 HU_APAActive 0 "disactive " 1 "active " ;
VAL_ 840 HU_FollowTargetDisplay_Set 0 "OFF " 1 "ON " ;
VAL_ 840 HU_HUDBiasLightSet 0 "Inactive " 1 "标准模式 " 2 "雪地模式 " 3 "赛道模式 " ;
VAL_ 840 HU_HUDOnOffReq 0 "Inactive " 1 "Off " 2 "On " 3 "Reserved " ;
VAL_ 840 HU_HUDRearIncomingVehicleSet 0 "OFF " 1 "ON " ;
VAL_ 840 HU_HUDMovingTargetDetect_Set 0 "OFF " 1 "ON " ;
VAL_ 840 HU_DVRSystemImprint 0 "Inactive " 1 "Quit " 2 "DisplayReq " 3 "Reserved " ;
VAL_ 840 HU_DVRErrorRecord 0 "Inactive " 1 "Quit " 2 "DisplayReq " 3 "Reserved " ;
VAL_ 840 HU_BcallReq 0 "norequest " 1 "callup拨电话） " ;
VAL_ 840 HU_SurrondingMonitorDone 0 "NoFeedback " 1 "Finished " ;
VAL_ 840 HU_RegisterStatus 0 "NoRegister " 1 "RegisterSucceed " 2 "RegisterUnsuccessful " 3 "Registered " ;
VAL_ 840 HU_TUIDReq 0 "NoRequest " 1 "Request " 2 "Reserved " 3 "Invalid " ;
VAL_ 840 HU_Seeoffanimation 0 "notactive " 1 "active " ;
VAL_ 840 HU_SDCapacity 0 "Inactive " 1 "Quit " 2 "DisplayReq " 3 "Reserved " ;
VAL_ 840 HU_AutoViewSet 0 "Off " 1 "On " ;
VAL_ 763 HU_UltravioletRadiatorControlCommand 0 "NoReq " 1 "LightON " 2 "LightOFF " 3 "Invalid " ;
VAL_ 763 HU_WindowControlCommand 0 "Invalid " 1 "LFOFF " 2 "LFON " 3 "RFOFF " 4 "RFON " 5 "LROFF " 6 "LRON " 7 "RROFF " 8 "RRON " 9 "FRONTROWOFF " 10 "FRONTROWON " 11 "REARROWOFF " 12 "REARROWON " 13 "ALLWINDOWSOFF " 14 "ALLWINDOWSON " 15 "ALLWINDOWS90CLOSED（透气功能使用此状态） " ;
VAL_ 763 HU_HighBeamLampReq 0 "NoReq " 1 "LightON " 2 "LightOFF " 3 "invalid " ;
VAL_ 763 HU_LowBeamLampReq 0 "NoReq " 1 "LightON " 2 "LightOFF " 3 "invalid " ;
VAL_ 763 HU_PositionLampReq 0 "NoReq " 1 "LightON " 2 "LightOFF " 3 "invalid " ;
VAL_ 763 HU_AutoLightReq 0 "NoReq " 1 "LightON " 2 "LightOFF " 3 "invalid " ;
VAL_ 763 HU_WiperSpReq 0 "NoReq " 1 "WiperON " 2 "WiperHighCtrl " 3 "WiperLowCtrl " 4 "WiperMistCtrl " 5 "WiperINTCtrl " 6 "WiperOFF " 7 "invalid " ;
VAL_ 763 HU_R_WiperReq 0 "NoReq " 1 "WiperON " 2 "WiperOFF " 3 "invalid " ;
VAL_ 763 HU_PLG_Remote_commandReq 0 "NoReq " 1 "PLGOpen " 2 "PLGClose " 3 "invalid " ;
VAL_ 763 HU_LockUnlockControlSignal 0 "NoReq " 1 "Lock " 2 "Unlock " 3 "invalid " ;
VAL_ 763 HU_FollowMeHomeReq 0 "NoReq " 1 "ON " 2 "OFF " 3 "invalid " ;
VAL_ 729 LAS_VoiceWarning 0 "NoWarning不报警 " 1 "LeftWarning左报警 " 2 "RightWarning右报警 " 3 "Invalid无效 " ;
VAL_ 729 LAS_LLaneMarkerType 0 "Dashed " 1 "solid " 2 "roadedge " 3 "doublelanemark " 4 "Botts'dots " 5 "other " 6 "fence " 7 "nodisplay " ;
VAL_ 729 LAS_LDWShakeLevStatus 0 "reserved " 1 "low " 2 "normal " 3 "high " ;
VAL_ 729 LAS_RLaneMarkerType 0 "Dashed " 1 "solid " 2 "roadedge " 3 "doublelanemark " 4 "Botts'dots " 5 "other " 6 "fence " 7 "nodisplay " ;
VAL_ 728 LAS_LASModeSelectionFeedback 0 "Invalid " 1 "LDW " 2 "LKA " 3 "LCS " 4 "ASC " 5 "LDWLKA " 6 "LDWLCS " 7 "OFF " ;
VAL_ 728 LAS_LASFailure 0 "NoError " 1 "camerablocked " 2 "temporaryfailure " 3 "permanentfailure " ;
VAL_ 728 LAS_LDWStatus 0 "Off " 1 "Standby " 2 "Active " 3 "Failure " ;
VAL_ 728 LDW_VibrationWarning 0 "NoWarning不报警 " 1 "LeftWarning左报警 " 2 "RightWarning右报警 " 3 "reserved " ;
VAL_ 1600 IP_ACCInterfaceDisplaySts 0 "无显示 " 1 "待机状态 " 2 "激活状态 " 3 "Reserved " ;
VAL_ 1600 IP_ShemeColorsSwitchStatus 0 "NoRequest " 1 "主题1 " 2 "主题2 " 3 "主题3 " 4 "主题模式联动 " 5 "主题4 " 6 "Reserved " 7 "Reserved " ;
VAL_ 1600 IP_NightBiasLightStatus 0 "Invalid " 1 "1级 " 2 "2级 " 3 "3级 " 4 "4级 " 5 "5级 " 6 "Reserved " 7 "Reserved " ;
VAL_ 1600 IP_DayBiasLightStatus 0 "Invalid " 1 "1级 " 2 "2级 " 3 "3级 " 4 "4级 " 5 "5级 " 6 "Reserved " 7 "Reserved " ;
VAL_ 1328 IP_FuelGageType 0 "指针式 " 1 "段码式 " 2 "预留 " 3 "预留 " ;
VAL_ 1328 IP_FuelLevel 0 "FUEIL≤E " 1 "EFUEIL≤1/8 " 2 "1/8FUEIL≤1/4 " 3 "1/4FUEIL≤3/8 " 4 "3/8FUEIL≤1/2 " 5 "1/2FUEIL≤5/8 " 6 "5/8FUEIL≤3/4 " 7 "3/4FUEIL≤7/8 " 8 "7/8FUEIL≤F " ;
VAL_ 1326 IP_HUConnection_acknowledge 0 "Inactive " 1 "OFF " 2 "ON " 3 "Reserved " ;
VAL_ 1326 IP_IndirectTPMSReset 0 "Norequest " 1 "Request " ;
VAL_ 1290 IP_FuelLeftoverVD 0 "Valid " 1 "Invalid " ;
VAL_ 901 IP_FuelLow 0 "normal " 1 "low " ;
VAL_ 901 IP_EngineOilPressureLowSts 0 "normal " 1 "low " ;
VAL_ 901 IP_EngineCoolanTemperatureHigh 0 "normal " 1 "high " ;
VAL_ 901 IP_WelcomeSoundSetStatus 0 "inactive " 1 "Sound1 " 2 "Sound2 " 3 "Sound3 " 4 "Customize " 5 "Reserved " 6 "Reserved " 7 "Reserved " ;
VAL_ 901 IP_ECnsAvgReset 0 "NotReset " 1 "Rest " ;
VAL_ 901 IP_BrakeFluidState 0 "normal " 1 "low " ;
VAL_ 901 IP_DimmingModeSetStatus 0 "Inactive " 1 "Auto " 2 "LCM " 3 "HU " ;
VAL_ 901 IP_AlarmSoundSetStatus 0 "inactive " 1 "Sound1 " 2 "Sound2 " 3 "Sound3 " 4 "Reserved " 5 "Reserved " 6 "Reserved " 7 "Reserved " ;
VAL_ 901 IP_RearSeatbeltWarningEnableFB 0 "inactive " 1 "Off " 2 "On " 3 "Reserved " ;
VAL_ 901 IP_MaintainReset 0 "NotReset " 1 "Rest " ;
VAL_ 901 IP_MessageAlertSoundSetStatus 0 "inactive " 1 "Sound1 " 2 "Sound2 " 3 "Sound3 " 4 "Reserved " 5 "Reserved " 6 "Reserved " 7 "Reserved " ;
VAL_ 734 IP_QDashACCFail 0 "noerror " 1 "error " 2 "reserved " 3 "reserved " ;
VAL_ 734 IP_DISFail 0 "noerror " 1 "error " ;
VAL_ 734 IP_PassengerLCDALEDSts 0 "NoError " 1 "Error " ;
VAL_ 734 IP_DriverLCDALEDSts 0 "NoError " 1 "Error " ;
VAL_ 650 IP_RRReq 0 "Inactive " 1 "NoRequest " 2 "Request " 3 "Reserved " ;
VAL_ 650 IP_LRReq 0 "Inactive " 1 "NoRequest " 2 "Request " 3 "Reserved " ;
VAL_ 650 IP_RFReq 0 "Inactive " 1 "NoRequest " 2 "Request " 3 "Reserved " ;
VAL_ 650 IP_HandBrakeSwitch 0 "nouse " 1 "inuse " ;
VAL_ 650 IP_LFReq 0 "Inactive " 1 "NoRequest " 2 "Request " 3 "Reserved " ;
VAL_ 1297 AC_EnvironmentalTempSensorDiagnosis 0 "Normal " 1 "Abnormal " 2 "Reserved " 3 "Invalid " ;
VAL_ 1297 AC_ThreeStateSwitchDiagnosis 0 "Normal " 1 "Abnormal " 2 "Reserved " 3 "Invalid " ;
VAL_ 1297 AC_CarInTempSensorDiagnosis 0 "Normal " 1 "Abnormal " 2 "Reserved " 3 "Invalid " ;
VAL_ 1297 AC_LightSensorDiagnosis 0 "Normal " 1 "Abnormal " 2 "Reserved " 3 "Invalid " ;
VAL_ 1296 AC_AirQualityInCarLevel 0 "优 " 1 "良 " 2 "轻度 " 3 "中度 " 4 "重度 " 5 "严重 " 6 "Reserved " 7 "Invalid " ;
VAL_ 1296 AC_PM25InCarValid 0 "vaild " 1 "Calculating/Invaild " 2 "reserved " 3 "Failure " ;
VAL_ 923 AC_RrpanelLock_St 0 "Inactive不显示 " 1 "Active显示 " ;
VAL_ 923 AC_RearSt 0 "Rearoff " 1 "Rearon " 2 "reserved " 3 "invalid " ;
VAL_ 923 AC_PlasmaSt 0 "inactive " 1 "active " ;
VAL_ 923 AC_AQSSt 0 "inactive " 1 "active " ;
VAL_ 923 AC_ACEcoSt 0 "inactive " 1 "active " ;
VAL_ 923 AC_RecycleType 0 "recycle " 1 "fresh " 2 "autorecycle " 3 "autofresh " 4 "invalid " 5 "隧道内循环 " 6 "抽烟外循环 " 7 "洗涤水内循环 " ;
VAL_ 923 AC_VentilationOnMode 0 "Invalid " 1 "Off " 2 "Default " 3 "UserDefined " ;
VAL_ 923 AC_ClimateDisplayReq 0 "inactive " 1 "active " ;
VAL_ 923 AC_TunnelAutoRecycleWork 0 "NotWork " 1 "Work " ;
VAL_ 923 AC_RearAutoSts 0 "灭灯 " 1 "点灯 " 2 "reserved " 3 "invalid " ;
VAL_ 923 AC_RrBlowType 0 "blowface " 1 "blowface/blowfeet " 2 "blowfeet " 3 "Invalid " ;
VAL_ 923 AC_AutoWorkStatus 0 "Singelmode " 1 "Dualmode " 2 "Triplemode " 3 "Quadruplemode " ;
VAL_ 923 AC_FrAutoSts 0 "灭灯 " 1 "点灯 " 2 "reserved " 3 "invalid " ;
VAL_ 923 AC_ACSt 0 "inactive " 1 "active " ;
VAL_ 870 AC_AC_ReqValid 0 "Valid " 1 "Invalid " ;
VAL_ 870 AC_AC_Req 0 "OFF " 1 "ON " ;
VAL_ 870 AC_EnvironmentalTempVD 0 "Valid " 1 "Invalid " ;
VAL_ 870 AC_PTCStatus 0 "OFF " 1 "1挡 " 2 "2挡 " 3 "3挡 " ;
VAL_ 870 AC_FrReqWindLevel 0 "OFF " 1 "Level1 " 2 "Level2 " 3 "Level3 " 4 "Level4 " 5 "Level5 " 6 "Level6 " 7 "Level7 " 8 "Level8 " 9 "Level0扇叶 " 10 "Reserved " 11 "Reserved " 12 "Reserved " 13 "Reserved " 14 "Reserved " 15 "Invaild " ;
VAL_ 870 AC_FrReqWindLevelVD 0 "Valid " 1 "Invalid " ;
VAL_ 870 AC_PressureSwitch 0 "close " 1 "open " ;
VAL_ 870 AC_CompressorStatus 0 "OFF " 1 "ON " ;
VAL_ 848 AC_RefreshModeEnableSts 0 "Inactive " 1 "主驾清新提神 " 2 "副驾清新提神 " 3 "前排清新提神 " ;
VAL_ 848 AC_ACSceneMode_FeedBack 0 "Norequest " 1 "不满足 " 2 "满足 " 3 "reserved " ;
VAL_ 848 AC_ComFort_FeedBack 0 "Inactive " 1 "降温达到舒适 " 2 "升温达到舒适 " 3 "Reserved " ;
VAL_ 848 AC_FanComFort_ModeSts 0 "Inactive " 1 "轻柔 " 2 "适中 " 3 "强劲 " ;
VAL_ 848 AC_AutomaticdeFoggingStatus 0 "Inactive " 1 "1档 " 2 "2档 " 3 "3档 " ;
VAL_ 848 AC_Remotedefronstingfeedback 0 "Inactive " 1 "open " 2 "close " 3 "Invalid " ;
VAL_ 832 AC_Rmote_Hot_Feedback 0 "invalid " 1 "远程控制启动中 " 2 "启动成功 " 3 "温度风门不到位故障 " 4 "模式风门不到位故障 " 5 "鼓风机故障 " 6 "预留 " 7 "预留 " ;
VAL_ 832 AC_Rmote_Cool_Feedback 0 "invalid " 1 "远程控制启动中 " 2 "启动成功 " 3 "温度风门不到位故障 " 4 "模式风门不到位故障 " 5 "鼓风机故障 " 6 "三态压力开关故障 " 7 "蒸发器表面温度传感器故障 " ;
VAL_ 832 AC_ACOnOff 0 "OFF " 1 "ON " 2 "notused " 3 "invalid " ;
VAL_ 832 AC_DrAirMergePortOpeningRatioVD 0 "Valid " 1 "Invalid " ;
VAL_ 832 AC_RrReqWindLevelVD 0 "Valid " 1 "Invalid " ;
VAL_ 832 AC_RrAirMergePortOpeningRatioVD 0 "Valid " 1 "Invalid " ;
VAL_ 832 AC_RrReqWindLevel 0 "OFF " 1 "Level1 " 2 "Level2 " 3 "Level3 " 4 "Level4 " 5 "Level5 " 6 "Level6 " 7 "Level7 " 8 "Level8 " 9 "Level0扇叶 " 10 "Reserved " 11 "Reserved " 12 "Reserved " 13 "Reserved " 14 "Reserved " 15 "Invaild " ;
VAL_ 832 AC_PrAirMergePortOpeningRatioVD 0 "Valid " 1 "Invalid " ;
VAL_ 816 AC_AutoDeFoggingStatus 0 "invalid " 1 "off " 2 "on " 3 "Reserved " ;
VAL_ 816 AC_TunnelAutoRecycleStatus 0 "invalid " 1 "off " 2 "on " 3 "Reserved " ;
VAL_ 816 AC_BlueTooth_Reduce_WindSpeedSetStatus 0 "invalid " 1 "off " 2 "on " 3 "Reserved " ;
VAL_ 816 AC_ReserveGearAutoRecycleStatus 0 "invalid " 1 "off " 2 "on " 3 "Reserved " ;
VAL_ 816 AC_PanelTouchConcussFB 0 "Inactive " 1 "level1 " 2 "level2 " 3 "level3 " ;
VAL_ 816 AC_AutowindSet1Status 0 "Invalid " 1 "OFF " 2 "ON " 3 "Reserved " ;
VAL_ 816 AC_AutowindSet2Status 0 "Invalid " 1 "OFF " 2 "ON " 3 "Reserved " ;
VAL_ 816 AC_AutowindSet3Status 0 "Invalid " 1 "OFF " 2 "ON " 3 "Reserved " ;
VAL_ 816 AC_FanComfort_ModeSts 0 "NormalSpeed " 1 "SlowSpeed " 2 "Invalid " 3 "Reserved " ;
VAL_ 816 AC_TouchCtrsoundReq 0 "NoReq " 1 "Req " ;
VAL_ 816 AC_MaxDefrostIndicator 0 "OFF " 1 "ON " ;
VAL_ 816 AC_Sleep 0 "standby " 1 "working " ;
VAL_ 816 AC_FrontDefrosterSwitch 0 "inactive " 1 "active " ;
VAL_ 816 AC_SystemFailureFlag 0 "NotFailure " 1 "Failure " ;
VAL_ 769 FP_MaxDefrost_Switch 0 "Inactive " 1 "Acitve " ;
VAL_ 769 AC_HardwireDriveModeChange 0 "NotPress " 1 "舒适运动经济自定义舒适的循环往上拨 " 2 "Reserved（舒适自定义经济运动的循环往下拨 " 3 "Invalid " ;
VAL_ 769 FP_MaxAC_Switch 0 "Inactive " 1 "Active " ;
VAL_ 769 FP_OFF 0 "inacitve无按键按下 " 1 "active有按键按下 " ;
VAL_ 769 FP_AirFlowMode_CW 0 "inacitve无按键按下 " 1 "active有按键按下 " ;
VAL_ 769 FP_CyclingMode 0 "inacitve无按键按下 " 1 "active有按键按下 " ;
VAL_ 769 FP_TempLongPress_Botton 0 "inacitve无按键按下 " 1 "active有按键按下 " ;
VAL_ 769 FP_FanLongPress_Botton 0 "inacitve无按键按下 " 1 "active有按键按下 " ;
VAL_ 769 FP_Front_AUTO_Switch 0 "Inactive " 1 "Active " ;
VAL_ 769 FP_AC_Swtich 0 "Inactive " 1 "Active " ;
VAL_ 769 FP_Front_Defrost_Switch 0 "Inactive " 1 "Active " ;
VAL_ 769 FP_RearDefrosterSwitch 0 "Inactive " 1 "Active " ;
